VERSION "dbc-export 1 2025.20.8"

NS_ :

BS_:

BU_: APP BMS CC CMP CMPD CP DAS DI DIF DIR EPBL EPBR EVSE FC GTW HCML HCMR HVP ICR PCS PM PMF PMR PTC SCCM SDCR TAS UMC VC VCFRONT VCLEFT VCRIGHT VCSEC

BO_ 909 APP_VC_infoMessage: 8 APP
 SG_ APP_inTunnel : 0|2@1+ (1,0) [1|3] "" Vector__XXX
 SG_ APP_windshieldHeaterOnReason : 2|3@1+ (1,0) [1|7] "" Vector__XXX
 SG_ APP_selfieCameraBlocked : 6|2@1+ (1,0) [1|3] "" Vector__XXX
 SG_ APP_selfieCameraLUX : 8|8@1+ (1,0) [0|253] "lux" Vector__XXX
 SG_ APP_sceneTagClearlyRaining : 16|2@1+ (1,0) [1|3] "" Vector__XXX
 SG_ APP_sceneTagFog : 18|2@1+ (1,0) [1|3] "" Vector__XXX
 SG_ APP_sceneTagFullyBlocked : 20|2@1+ (1,0) [1|3] "" Vector__XXX
 SG_ APP_sceneTagIndoors : 22|2@1+ (1,0) [1|3] "" Vector__XXX
 SG_ APP_sceneTagLensFlare : 24|2@1+ (1,0) [1|3] "" Vector__XXX
 SG_ APP_sceneTagRaining : 26|2@1+ (1,0) [1|3] "" Vector__XXX
 SG_ APP_sceneTagSevereWeather : 28|2@1+ (1,0) [1|3] "" Vector__XXX
 SG_ APP_sceneTagSnowing : 30|2@1+ (1,0) [1|3] "" Vector__XXX
 SG_ APP_sceneTagSnowyRoad : 32|2@1+ (1,0) [1|3] "" Vector__XXX
 SG_ APP_sceneTagSunGlare : 34|2@1+ (1,0) [1|3] "" Vector__XXX
 SG_ APP_sceneTagTunnel : 36|2@1+ (1,0) [1|3] "" Vector__XXX
 SG_ APP_sceneTagWetRoad : 38|2@1+ (1,0) [1|3] "" Vector__XXX
 SG_ APP_fisheyeInPathVisibility : 40|3@1+ (1,0) [1|7] "" Vector__XXX
 SG_ APP_fisheyeOverallVisibility : 43|3@1+ (1,0) [1|7] "" Vector__XXX
 SG_ APP_mainInPathVisibility : 46|3@1+ (1,0) [1|7] "" Vector__XXX
 SG_ APP_mainOverallVisibility : 49|3@1+ (1,0) [1|7] "" Vector__XXX
 SG_ APP_narrowInPathVisibility : 52|3@1+ (1,0) [1|7] "" Vector__XXX
 SG_ APP_narrowOverallVisibility : 55|3@1+ (1,0) [1|7] "" Vector__XXX
 SG_ APP_frontCamOcclusionType : 58|3@1+ (1,0) [0|7] "" Vector__XXX

BO_ 818 BMS_bmbMinMax: 6 BMS
 SG_ BMS_bmbMinMaxMultiplexer M : 0|2@1+ (1,0) [0|3] "" Vector__XXX
 SG_ BMS_thermistorNumTMin m0 : 2|4@1+ (1,0) [0|15] "" Vector__XXX
 SG_ BMS_thermistorNumTMax m0 : 8|4@1+ (1,0) [0|15] "" Vector__XXX
 SG_ BMS_thermistorTMax m0 : 16|8@1+ (0.5,-40) [-40|87.5] "DegC" Vector__XXX
 SG_ BMS_thermistorTMin m0 : 24|8@1+ (0.5,-40) [-40|87.5] "DegC" Vector__XXX
 SG_ BMS_thermistorTAvg m0 : 32|8@1+ (0.5,-40) [-40|87.5] "DegC" Vector__XXX
 SG_ BMS_brickVoltageMax m1 : 2|12@1+ (0.002,0) [0|5] "V" Vector__XXX
 SG_ BMS_brickVoltageMin m1 : 16|12@1+ (0.002,0) [0|5] "V" Vector__XXX
 SG_ BMS_brickNumVoltageMax m1 : 32|7@1+ (1,1) [1|128] "" Vector__XXX
 SG_ BMS_brickNumVoltageMin m1 : 40|7@1+ (1,1) [1|128] "" Vector__XXX

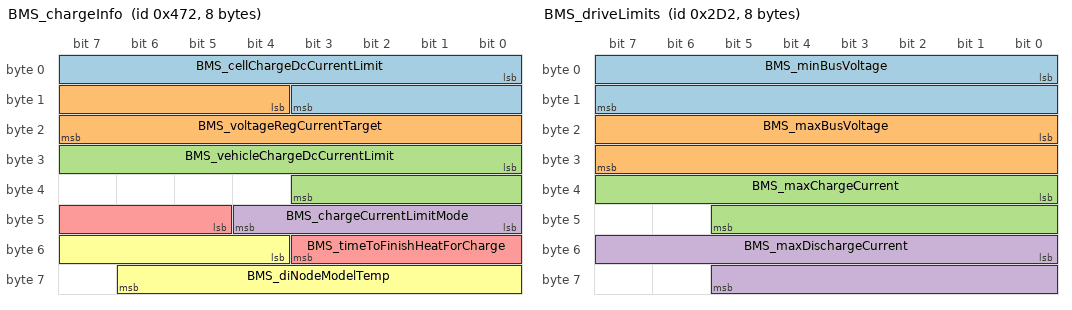
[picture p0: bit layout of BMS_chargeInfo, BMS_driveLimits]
BO_ 1138 BMS_chargeInfo: 8 BMS
 SG_ BMS_cellChargeDcCurrentLimit : 0|12@1+ (0.5,0) [0|2047.5] "A" Vector__XXX
 SG_ BMS_voltageRegCurrentTarget : 12|12@1+ (0.5,0) [0|2047.5] "A" Vector__XXX
 SG_ BMS_vehicleChargeDcCurrentLimit : 24|12@1+ (0.5,0) [0|2047.5] "A" Vector__XXX
 SG_ BMS_chargeCurrentLimitMode : 40|5@1+ (1,0) [0|31] "" Vector__XXX
 SG_ BMS_timeToFinishHeatForCharge : 45|7@1+ (5,0) [0|600] "min" Vector__XXX
 SG_ BMS_diNodeModelTemp : 52|11@1+ (0.1,-50) [-50|154.6] "degC" Vector__XXX

BO_ 722 BMS_driveLimits: 8 BMS
 SG_ BMS_minBusVoltage : 0|16@1+ (0.02,0) [0|1200] "V" Vector__XXX
 SG_ BMS_maxBusVoltage : 16|16@1+ (0.02,0) [0|1200] "V" Vector__XXX
 SG_ BMS_maxChargeCurrent : 32|14@1+ (0.1,0) [0|1638.2] "A" Vector__XXX
 SG_ BMS_maxDischargeCurrent : 48|14@1+ (0.15,0) [0|2455] "A" Vector__XXX

BO_ 850 BMS_energyStatus: 8 BMS
 SG_ BMS_energyStatusMultiplexer M : 0|2@1+ (1,0) [0|3] "" Vector__XXX
 SG_ BMS_nominalFullPackEnergy m0 : 16|16@1+ (0.02,0) [0|1310.68] "kWh" Vector__XXX
 SG_ BMS_nominalEnergyRemaining m0 : 32|16@1+ (0.02,0) [0|1310.68] "kWh" Vector__XXX
 SG_ BMS_idealEnergyRemaining m0 : 48|16@1+ (0.02,0) [0|1310.68] "kWh" Vector__XXX
 SG_ BMS_fullChargeComplete m1 : 15|1@1+ (1,0) [0|1] "" Vector__XXX
 SG_ BMS_energyBuffer m1 : 16|16@1+ (0.01,0) [0|655.34] "kWh" Vector__XXX
 SG_ BMS_expectedEnergyRemaining m1 : 32|16@1+ (0.02,0) [0|1310.68] "kWh" Vector__XXX
 SG_ BMS_energyToChargeComplete m1 : 48|16@1+ (0.02,0) [0|1310.68] "kWh" Vector__XXX
 SG_ BMS_energyRemainingDisplay m2 : 8|16@1+ (0.02,0) [0|1310.68] "kWh" Vector__XXX
 SG_ BMS_energyRemainingTDisplay m2 : 24|16@1+ (0.02,0) [0|1310.68] "kWh" Vector__XXX
 SG_ BMS_energyDisplayErrorBlendRate m2 : 40|12@1+ (0.0156288165599,0) [0|64] "%" Vector__XXX
 SG_ BMS_userFacingSoe m2 : 52|11@1+ (0.05,0) [0|100] "%" Vector__XXX

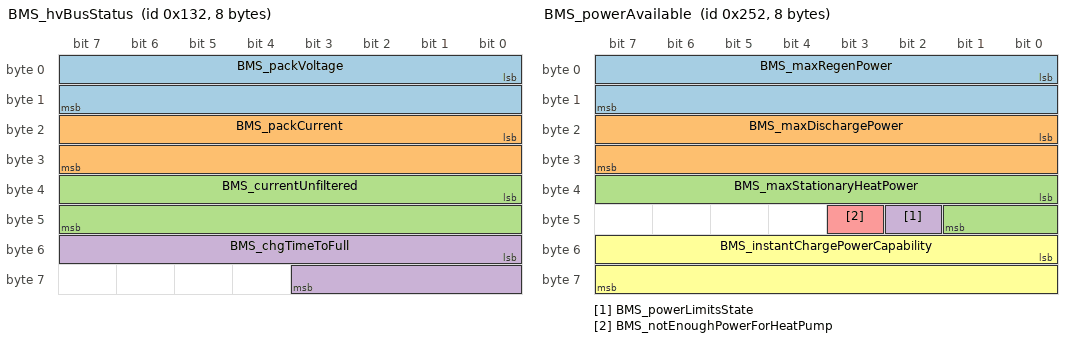
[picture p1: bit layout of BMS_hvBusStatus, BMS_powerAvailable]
BO_ 306 BMS_hvBusStatus: 8 BMS
 SG_ BMS_packVoltage : 0|16@1+ (0.01,0) [0|655.35] "V" Vector__XXX
 SG_ BMS_packCurrent : 16|16@1- (0.1,0) [-3276.7|3276.7] "A" Vector__XXX
 SG_ BMS_currentUnfiltered : 32|16@1- (0.05,-822) [-2460.3|816.3] "A" Vector__XXX
 SG_ BMS_chgTimeToFull : 48|12@1+ (0.01666667,0) [0|68.23334698] "Hours" Vector__XXX

BO_ 768 BMS_info: 8 BMS
 SG_ BMS_infoIndex M : 0|8@1+ (1,0) [0|255] "" Vector__XXX
 SG_ BMS_buildType m10 : 8|3@1+ (1,0) [0|7] "" Vector__XXX
 SG_ BMS_buildConfigId m10 : 16|16@1+ (1,0) [0|65535] "" Vector__XXX
 SG_ BMS_hardwareId m10 : 32|16@1+ (1,0) [0|65535] "" Vector__XXX
 SG_ BMS_componentId m10 : 48|16@1+ (1,0) [0|65535] "" Vector__XXX
 SG_ BMS_pcbaId m11 : 16|8@1+ (1,0) [0|255] "" Vector__XXX
 SG_ BMS_assemblyId m11 : 24|8@1+ (1,0) [0|255] "" Vector__XXX
 SG_ BMS_usageId m11 : 32|16@1+ (1,0) [0|65535] "" Vector__XXX
 SG_ BMS_subUsageId m11 : 48|16@1+ (1,0) [0|65535] "" Vector__XXX
 SG_ BMS_platformType m13 : 8|8@1+ (1,0) [0|255] "" Vector__XXX
 SG_ BMS_appCrc m13 : 32|32@1+ (1,0) [0|4294967295] "" Vector__XXX
 SG_ BMS_appGitHash m17 : 8|56@1+ (1,0) [0|7.20575940379e+16] "" Vector__XXX
 SG_ BMS_bootGitHash m18 : 8|56@1+ (1,0) [0|7.20575940379e+16] "" Vector__XXX
 SG_ BMS_bootUdsProtoVersion m20 : 8|8@1+ (1,0) [0|255] "" Vector__XXX
 SG_ BMS_bootCrc m20 : 32|32@1+ (1,0) [0|4294967295] "" Vector__XXX

BO_ 978 BMS_kwhCounter: 8 BMS
 SG_ BMS_kwhDischargeTotal : 0|32@1+ (0.001,0) [0|268435.456] "KWh" Vector__XXX
 SG_ BMS_kwhChargeTotal : 32|32@1+ (0.001,0) [0|268435.456] "KWh" Vector__XXX

BO_ 1010 BMS_kwhCountersMultiplexed: 8 BMS
 SG_ BMS_kwhCounter_Id M : 0|4@1+ (1,0) [0|15] "" Vector__XXX
 SG_ BMS_acChargerKwhTotal m0 : 8|32@1+ (0.001,0) [0|268435.456] "KWh" Vector__XXX
 SG_ BMS_dcChargerKwhTotal m1 : 8|32@1+ (0.001,0) [0|268435.456] "KWh" Vector__XXX
 SG_ BMS_kwhRegenChargeTotal m2 : 8|32@1+ (0.001,0) [0|268435.456] "KWh" Vector__XXX
 SG_ BMS_kwhDriveDischargeTotal m3 : 8|32@1+ (0.001,0) [0|268435.456] "KWh" Vector__XXX
 SG_ BMS_kwhDischargeTotalModule1 m4 : 8|28@1+ (0.001,0) [0|268435.455] "KWh" Vector__XXX
 SG_ BMS_kwhChargeTotalModule1 m4 : 36|28@1+ (0.001,0) [0|268435.455] "KWh" Vector__XXX
 SG_ BMS_kwhAcChargeTotalModule1 m5 : 8|28@1+ (0.001,0) [0|268435.455] "KWh" Vector__XXX
 SG_ BMS_kwhDcChargeTotalModule1 m5 : 36|28@1+ (0.001,0) [0|268435.455] "KWh" Vector__XXX
 SG_ BMS_kwhDischargeTotalModule2 m6 : 8|28@1+ (0.001,0) [0|268435.455] "KWh" Vector__XXX
 SG_ BMS_kwhChargeTotalModule2 m6 : 36|28@1+ (0.001,0) [0|268435.455] "KWh" Vector__XXX
 SG_ BMS_kwhAcChargeTotalModule2 m7 : 8|28@1+ (0.001,0) [0|268435.455] "KWh" Vector__XXX
 SG_ BMS_kwhDcChargeTotalModule2 m7 : 36|28@1+ (0.001,0) [0|268435.455] "KWh" Vector__XXX
 SG_ BMS_kwhDischargeTotalModule3 m8 : 8|28@1+ (0.001,0) [0|268435.455] "KWh" Vector__XXX
 SG_ BMS_kwhChargeTotalModule3 m8 : 36|28@1+ (0.001,0) [0|268435.455] "KWh" Vector__XXX
 SG_ BMS_kwhAcChargeTotalModule3 m9 : 8|28@1+ (0.001,0) [0|268435.455] "KWh" Vector__XXX
 SG_ BMS_kwhDcChargeTotalModule3 m9 : 36|28@1+ (0.001,0) [0|268435.455] "KWh" Vector__XXX
 SG_ BMS_kwhDischargeTotalModule4 m10 : 8|28@1+ (0.001,0) [0|268435.455] "KWh" Vector__XXX
 SG_ BMS_kwhChargeTotalModule4 m10 : 36|28@1+ (0.001,0) [0|268435.455] "KWh" Vector__XXX
 SG_ BMS_kwhAcChargeTotalModule4 m11 : 8|28@1+ (0.001,0) [0|268435.455] "KWh" Vector__XXX
 SG_ BMS_kwhDcChargeTotalModule4 m11 : 36|28@1+ (0.001,0) [0|268435.455] "KWh" Vector__XXX

BO_ 882 BMS_log1: 8 BMS
 SG_ BMS_log1MuxId M : 0|8@1+ (1,0) [0|255] "" Vector__XXX
 SG_ BMS_extDcPrechargeVoltageLimit m8 : 20|12@1+ (0.146502256393,0) [0|599.926739929] "V" Vector__XXX
 SG_ BMS_dcChargeCurrentRequest m8 : 32|14@1- (0.25,0) [-2048|2047.75] "A" Vector__XXX
 SG_ BMS_dcChargeCurrentLimit m8 : 46|13@1- (0.5,0) [-2048|2047.5] "A" Vector__XXX
 SG_ BMS_dcDischargeEnabled m8 : 59|1@1+ (1,0) [0|1] "" Vector__XXX
 SG_ BMS_rippleChargeRetryCount m8 : 60|3@1+ (1,0) [0|7] "" Vector__XXX
 SG_ BMS_dcChargeVoltageLimit m9 : 8|12@1+ (0.146502256393,0) [0|599.926739929] "V" Vector__XXX
 SG_ BMS_dcChargePowerLimit m9 : 20|12@1- (1,0) [-2048|2047] "kW" Vector__XXX
 SG_ BMS_maxExtIsoFcLinkV m9 : 48|13@1+ (0.134293735027,0) [0|1099.99998361] "V" Vector__XXX
 SG_ BMS_socByDeltaVEnabled m15 : 8|1@1+ (1,0) [0|1] "" Vector__XXX
 SG_ BMS_socByDvMaxSocLimit m15 : 9|10@1+ (0.1,0) [0|102.2] "%" Vector__XXX
 SG_ BMS_socByDvVoltageChangeOverAh m15 : 19|9@1+ (0.002,0) [0|1] "V" Vector__XXX
 SG_ BMS_socByDvMaxSocByAhCorrected m15 : 28|10@1+ (0.1,0) [0|102.2] "%" Vector__XXX
 SG_ BMS_socByDvMaxBrickVoltage m15 : 40|12@1+ (0.002,0) [0|5] "V" Vector__XXX
 SG_ BMS_socByDvMaxBrickId m15 : 56|8@1+ (1,1) [1|256] "" Vector__XXX

BO_ 946 BMS_log2: 8 BMS
 SG_ BMS_log2MuxId M : 0|7@1+ (1,0) [0|127] "" Vector__XXX
 SG_ BMS_cacAvg m0 : 8|13@1+ (0.1,0) [0|819.1] "Ah" Vector__XXX
 SG_ BMS_cacMin m0 : 24|13@1+ (0.1,0) [0|819.1] "Ah" Vector__XXX
 SG_ BMS_cacMinBrickId m0 : 37|7@1+ (1,1) [1|128] "" Vector__XXX
 SG_ BMS_cacMax m0 : 44|13@1+ (0.1,0) [0|819.1] "Ah" Vector__XXX
 SG_ BMS_cacMaxBrickId m0 : 57|7@1+ (1,1) [1|128] "" Vector__XXX
 SG_ BMS_acRippleConfigNvramValid m18 : 7|1@1+ (1,0) [0|1] "" Vector__XXX
 SG_ BMS_hvChain_useLeakyBucket m18 : 8|1@1+ (1,0) [0|1] "" Vector__XXX
 SG_ BMS_hvChain_iLimit m18 : 9|14@1+ (0.2,0) [0|3275] "A" Vector__XXX
 SG_ BMS_hvChain_limitingState m18 : 23|9@1+ (1,1) [1|511] "" Vector__XXX
 SG_ BMS_hvChain_limitingStateTempera m18 : 32|13@1- (0.1,367.6) [-40|775] "DegC" Vector__XXX
 SG_ BMS_acRippleIsSupported m18 : 45|1@1+ (1,0) [0|1] "" Vector__XXX
 SG_ BMS_acRippleStartTemperatureMax m18 : 46|9@1+ (0.25,-25) [-25|100] "DegC" Vector__XXX
 SG_ BMS_acRippleStartTemperatureMin m18 : 55|9@1+ (0.25,-25) [-25|100] "DegC" Vector__XXX
 SG_ BMS_fcLinkTestDecayTime m20 : 8|10@1+ (2,0) [0|2044] "mS" Vector__XXX
 SG_ BMS_fcLinkTestTimeSinceLastRun m20 : 18|12@1+ (0.0175824183971,0) [0|71.99] "Hours" Vector__XXX
 SG_ BMS_pcsPrechargeTargetVoltage m20 : 32|16@1- (0.1,0) [-3276.8|3276.7] "V" Vector__XXX
 SG_ BMS_recentOvUvAlert m20 : 48|1@1+ (1,0) [0|1] "" Vector__XXX
 SG_ BMS_recentIsoAlert m20 : 49|1@1+ (1,0) [0|1] "" Vector__XXX
 SG_ BMS_recentBmbMiaAlert m20 : 50|1@1+ (1,0) [0|1] "" Vector__XXX
 SG_ BMS_cacBlendingConfigNvramValid m20 : 51|1@1+ (1,0) [0|1] "" Vector__XXX
 SG_ BMS_cacBlendingEnabled m20 : 52|1@1+ (1,0) [0|1] "" Vector__XXX
 SG_ BMS_cacBlendPercentPerCycle m20 : 53|10@1+ (0.001,0) [0|1.023] "%" Vector__XXX
 SG_ BMS_energyVariableChgRequested m21 : 8|1@1+ (1,0) [0|1] "" Vector__XXX
 SG_ BMS_packRestTime m21 : 9|12@1+ (0.0175824183971,0) [0|71.99] "Hours" Vector__XXX
 SG_ BMS_idealEnergyFloor m21 : 21|10@1+ (0.1,0) [0|102.2] "KWh" Vector__XXX
 SG_ BMS_thmGradientSlopeCondition m21 : 31|1@1+ (1,0) [0|1] "" Vector__XXX
 SG_ BMS_recentSlopeConditon m21 : 32|1@1+ (1,0) [0|1] "" Vector__XXX
 SG_ BMS_dynamicEnergyBuffer m21 : 33|10@1+ (0.1,0) [0|102.2] "KWh" Vector__XXX
 SG_ BMS_temperatureCondition m21 : 43|1@1+ (1,0) [0|1] "" Vector__XXX
 SG_ BMS_thmGradientSlope m21 : 44|10@1- (0.01,0) [-5.12|5.11] "C/min" Vector__XXX
 SG_ BMS_thmGradient m21 : 56|8@1+ (0.1,0) [0|25.5] "C" Vector__XXX
 SG_ BMS_dSocNormalizedMin m33 : 8|12@1+ (0.0030517578125,-12.4969482422) [-12.4969482422|-0.003051757825] "%" Vector__XXX
 SG_ BMS_dSocNormalizedFiltMin m33 : 20|12@1+ (0.0030517578125,-12.4969482422) [-12.4969482422|-0.003051757825] "%" Vector__XXX
 SG_ BMS_dSocMinAlpha m33 : 32|12@1+ (0.0030517578125,-12.4969482422) [-12.4969482422|-0.003051757825] "%" Vector__XXX
 SG_ BMS_dSocMaxLowAlphaCounter m33 : 44|4@1+ (1,0) [0|15] "" Vector__XXX
 SG_ BMS_dSocMinAlphaBrickID m33 : 48|7@1+ (1,1) [1|128] "" Vector__XXX
 SG_ BMS_dSocCacMargin m33 : 55|9@1+ (0.0030517578125,0) [0|1.55639648438] "%" Vector__XXX
 SG_ BMS_lifeModelAvgTempSeverity m55 : 8|5@1+ (0.1,0) [0|3] "-" Vector__XXX
 SG_ BMS_lifeModelDepthOfDischargeSev m55 : 16|8@1+ (0.01,0) [0|1.5] "-" Vector__XXX
 SG_ BMS_lifeModelHistogramCapacityLo m55 : 24|9@1+ (0.1,0) [0|51] "%" Vector__XXX
 SG_ BMS_lifeModelHistogramBrickCapac m55 : 33|13@1+ (0.1,0) [0|819] "Ah" Vector__XXX
 SG_ BMS_lifeModelDcrGrowthPercent m55 : 48|14@1- (0.1,200) [-100|500] "%" Vector__XXX
 SG_ BMS_nominalFullPackEnergyRaw m56 : 8|16@1+ (0.02,0) [0|1310.68] "kWh" Vector__XXX
 SG_ BMS_userChargeCalibratingReason m56 : 24|2@1+ (1,0) [0|3] "" Vector__XXX
 SG_ BMS_nominalEnergyRemainingBuffer m56 : 32|16@1+ (0.02,0) [0|1310.68] "kWh" Vector__XXX
 SG_ BMS_idealEnergyRemainingBuffered m56 : 48|16@1+ (0.02,0) [0|1310.68] "kWh" Vector__XXX
 SG_ BMS_largestCacSpreadErrorLower m64 : 8|12@1+ (0.1,0) [0|409.4] "Ah" Vector__XXX
 SG_ BMS_lifeModelAverageCac m64 : 20|12@1+ (0.1,0) [0|409.4] "Ah" Vector__XXX
 SG_ BMS_lifeModelCacBrick1 m64 : 32|12@1+ (0.1,0) [0|409.4] "Ah" Vector__XXX
 SG_ BMS_lifeModelAverageOffset m64 : 44|10@1- (0.1,0) [-51.1|51.1] "Ah" Vector__XXX
 SG_ BMS_percentCacUpdatesInTimeWindo m64 : 54|10@1+ (0.1,0) [0|100] "%" Vector__XXX
 SG_ BMS_lifeModelMaxCacBrickId m65 : 8|8@1+ (1,1) [1|255] "" Vector__XXX
 SG_ BMS_lifeModelMaxCac m65 : 16|12@1+ (0.1,0) [0|409.4] "Ah" Vector__XXX
 SG_ BMS_lifeModelMinCacBrickId m65 : 28|8@1+ (1,1) [1|255] "" Vector__XXX
 SG_ BMS_lifeModelMinCac m65 : 36|12@1+ (0.1,0) [0|409.4] "Ah" Vector__XXX
 SG_ BMS_restingPointCacAvg m65 : 48|12@1+ (0.1,0) [0|409.4] "Ah" Vector__XXX
 SG_ BMS_cacEstimationSource m65 : 60|2@1+ (1,0) [0|3] "" Vector__XXX
 SG_ BMS_synchronizedCacMaxRaw m71 : 8|12@1+ (0.1,0) [0|409.4] "Ah" Vector__XXX
 SG_ BMS_synchronizedCacMinRaw m71 : 20|12@1+ (0.1,0) [0|409.4] "Ah" Vector__XXX
 SG_ BMS_largestSyncCacErrorStartSoc m71 : 32|10@1+ (0.1,0) [0|102.2] "%" Vector__XXX
 SG_ BMS_largestSyncCacErrorEndSoc m71 : 42|10@1+ (0.1,0) [0|102.2] "%" Vector__XXX
 SG_ BMS_runtimeSocConfigNvramValid m71 : 52|1@1+ (1,0) [0|1] "" Vector__XXX
 SG_ BMS_runtimeSocCorrectionsEnabled m71 : 53|1@1+ (1,0) [0|1] "" Vector__XXX
 SG_ BMS_rubberBandingEnabled m71 : 54|1@1+ (1,0) [0|1] "" Vector__XXX
 SG_ BMS_rubberBandingConfigNvramVali m71 : 55|1@1+ (1,0) [0|1] "" Vector__XXX
 SG_ BMS_runtimeSocMinTempForModel m71 : 56|6@1+ (0.5,0) [0|20] "DegC" Vector__XXX
 SG_ BMS_energyBufferConfigNvramValid m71 : 62|1@1+ (1,0) [0|1] "" Vector__XXX
 SG_ BMS_thermalEvent1pDetectConfigDi m71 : 63|1@1+ (1,0) [0|1] "" Vector__XXX
 SG_ BMS_sohEnergy m79 : 8|11@1+ (0.1,0) [0|204.6] "KWh" Vector__XXX
 SG_ BMS_fullCapacitySohEnergy m79 : 19|11@1+ (0.1,0) [0|204.6] "KWh" Vector__XXX
 SG_ BMS_calibratedCapacitySohEnergy m79 : 30|11@1+ (0.1,0) [0|204.6] "KWh" Vector__XXX
 SG_ BMS_estimatedCapacitySohEnergy m79 : 41|11@1+ (0.1,0) [0|204.6] "KWh" Vector__XXX
 SG_ BMS_prevUserFacingSohEnergy m79 : 52|11@1+ (0.1,0) [0|204.6] "KWh" Vector__XXX
 SG_ BMS_stateOfHealthMinCac m80 : 8|13@1+ (0.1,0) [0|819] "Ah" Vector__XXX
 SG_ BMS_lifeModelStorageLossPackAge m80 : 24|14@1+ (1,0) [0|16382] "days" Vector__XXX
 SG_ BMS_lifeModelThroughputCycleCoun m80 : 40|12@1+ (1,0) [0|4094] "Cycles" Vector__XXX
 SG_ BMS_lifeModelThroughputDcrCycleC m80 : 52|12@1+ (1,0) [0|4094] "Cycles" Vector__XXX
 SG_ BMS_energyWalkCounter m83 : 8|8@1+ (1,0) [0|255] "" Vector__XXX
 SG_ BMS_energyWalkTimeoutCounter m83 : 16|8@1+ (1,0) [0|255] "" Vector__XXX
 SG_ BMS_dynamicCcvEnabled m83 : 24|1@1+ (1,0) [0|1] "" Vector__XXX
 SG_ BMS_chargeTargetLookupSoc m83 : 32|10@1+ (0.1,0) [0|102.2] "%" Vector__XXX
 SG_ BMS_stateOfHealth m83 : 42|10@1+ (0.1,0) [0|100] "%" Vector__XXX

BO_ 914 BMS_packConfig: 8 BMS
 SG_ BMS_packConfigMultiplexer M : 0|8@1+ (1,0) [0|255] "" Vector__XXX
 SG_ BMS_reservedConfig_0 m0 : 8|5@1+ (1,0) [0|31] "" Vector__XXX
 SG_ BMS_moduleType m1 : 8|3@1+ (1,0) [0|7] "" Vector__XXX
 SG_ BMS_thermalPackType m1 : 11|4@1+ (1,0) [0|15] "" Vector__XXX
 SG_ BMS_packMass m1 : 16|8@1+ (1,300) [342|540] "kg" Vector__XXX
 SG_ BMS_platformMaxBusVoltage m1 : 24|10@1+ (1,300) [300|1300] "V" Vector__XXX
 SG_ BMS_standbySupplyContinuousPower m1 : 36|2@1+ (1,0) [0|3] "" Vector__XXX

BO_ 594 BMS_powerAvailable: 8 BMS
 SG_ BMS_maxRegenPower : 0|16@1+ (0.01,0) [0|655.35] "kW" Vector__XXX
 SG_ BMS_maxDischargePower : 16|16@1+ (0.013,0) [0|850] "kW" Vector__XXX
 SG_ BMS_maxStationaryHeatPower : 32|10@1+ (0.01,0) [0|10.23] "kW" Vector__XXX
 SG_ BMS_powerLimitsState : 42|1@1+ (1,0) [0|1] "" Vector__XXX
 SG_ BMS_notEnoughPowerForHeatPump : 43|1@1+ (1,0) [0|1] "" Vector__XXX
 SG_ BMS_instantChargePowerCapability : 48|16@1+ (0.05,0) [0|3276.7] "kW" Vector__XXX

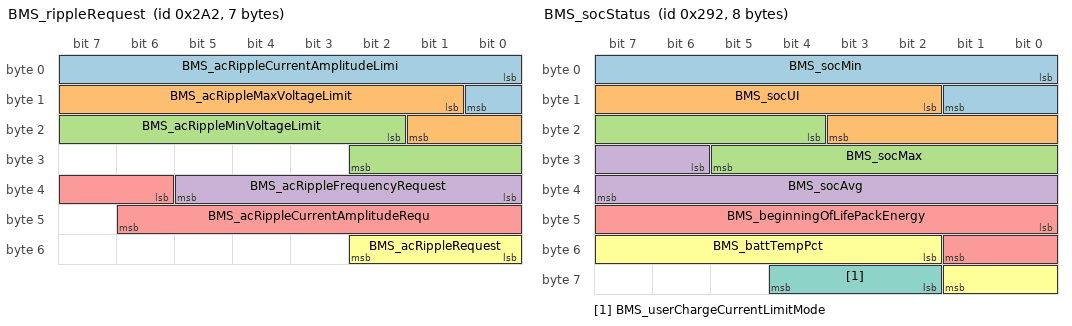
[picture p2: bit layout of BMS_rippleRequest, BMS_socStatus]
BO_ 674 BMS_rippleRequest: 7 BMS
 SG_ BMS_acRippleCurrentAmplitudeLimi : 0|9@1+ (1,0) [0|511] "A" Vector__XXX
 SG_ BMS_acRippleMaxVoltageLimit : 9|9@1+ (1,0) [0|511] "V" Vector__XXX
 SG_ BMS_acRippleMinVoltageLimit : 18|9@1+ (1,0) [0|511] "V" Vector__XXX
 SG_ BMS_acRippleFrequencyRequest : 32|6@1+ (1,80) [80|142] "Hz" Vector__XXX
 SG_ BMS_acRippleCurrentAmplitudeRequ : 38|9@1+ (1,0) [0|511] "A" Vector__XXX
 SG_ BMS_acRippleRequest : 48|3@1+ (1,0) [0|7] "" Vector__XXX

BO_ 658 BMS_socStatus: 8 BMS
 SG_ BMS_socMin : 0|10@1+ (0.1,0) [0|102.2] "%" Vector__XXX
 SG_ BMS_socUI : 10|10@1+ (0.1,0) [0|100] "%" Vector__XXX
 SG_ BMS_socMax : 20|10@1+ (0.1,0) [0|102.2] "%" Vector__XXX
 SG_ BMS_socAvg : 30|10@1+ (0.1,0) [0|102.2] "%" Vector__XXX
 SG_ BMS_beginningOfLifePackEnergy : 40|10@1+ (0.1,0) [0|102.2] "KWh" Vector__XXX
 SG_ BMS_battTempPct : 50|8@1+ (0.4,0) [0|100] "%" Vector__XXX
 SG_ BMS_userChargeCurrentLimitMode : 58|3@1+ (1,0) [0|7] "" Vector__XXX

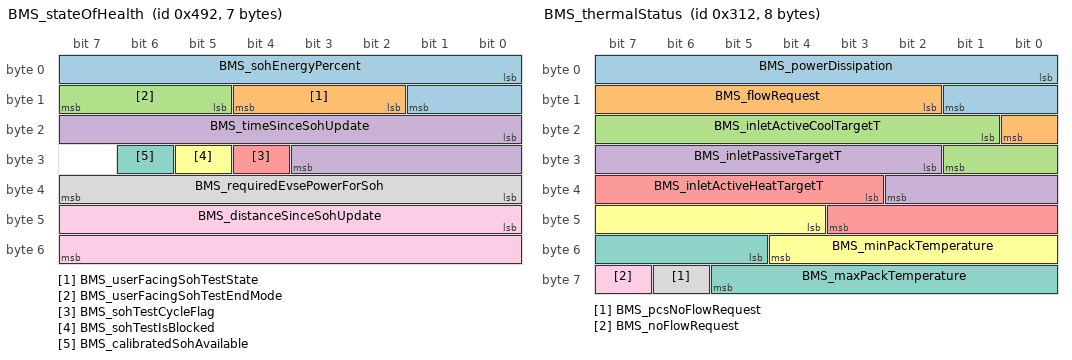
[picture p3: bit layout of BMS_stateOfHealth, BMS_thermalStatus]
BO_ 1170 BMS_stateOfHealth: 7 BMS
 SG_ BMS_sohEnergyPercent : 0|10@1+ (0.1,0) [0|100] "%" Vector__XXX
 SG_ BMS_userFacingSohTestState : 10|3@1+ (1,0) [0|7] "" Vector__XXX
 SG_ BMS_userFacingSohTestEndMode : 13|3@1+ (1,0) [0|7] "" Vector__XXX
 SG_ BMS_timeSinceSohUpdate : 16|12@1+ (1,0) [0|3650] "days" Vector__XXX
 SG_ BMS_sohTestCycleFlag : 28|1@1+ (1,0) [0|1] "" Vector__XXX
 SG_ BMS_sohTestIsBlocked : 29|1@1+ (1,0) [0|1] "" Vector__XXX
 SG_ BMS_calibratedSohAvailable : 30|1@1+ (1,0) [0|1] "" Vector__XXX
 SG_ BMS_requiredEvsePowerForSoh : 32|8@1+ (0.125,0) [0|31.75] "kW" Vector__XXX
 SG_ BMS_distanceSinceSohUpdate : 40|16@1+ (1,0) [0|65534] "km" Vector__XXX

BO_ 530 BMS_status: 8 BMS
 SG_ BMS_hvacPowerRequest : 0|1@1+ (1,0) [0|1] "" Vector__XXX
 SG_ BMS_notEnoughPowerForDrive : 1|1@1+ (1,0) [0|1] "" Vector__XXX
 SG_ BMS_notEnoughPowerForSupport : 2|1@1+ (1,0) [0|1] "" Vector__XXX
 SG_ BMS_preconditionAllowed : 3|1@1+ (1,0) [0|1] "" Vector__XXX
 SG_ BMS_updateAllowed : 4|1@1+ (1,0) [0|1] "" Vector__XXX
 SG_ BMS_activeHeatingWorthwhile : 5|1@1+ (1,0) [0|1] "" Vector__XXX
 SG_ BMS_cpMiaOnHvs : 6|1@1+ (1,0) [0|1] "" Vector__XXX
 SG_ BMS_pcsPwmEnabled : 7|1@1+ (1,0) [0|1] "" Vector__XXX
 SG_ BMS_contactorState : 8|3@1+ (1,0) [1|7] "" Vector__XXX
 SG_ BMS_userChargeStatus : 11|3@1+ (1,0) [0|7] "" Vector__XXX
 SG_ BMS_chargeRequest : 31|1@1+ (1,0) [0|1] "" Vector__XXX
 SG_ BMS_state : 32|4@1+ (1,0) [0|15] "" Vector__XXX
 SG_ BMS_diLimpRequest : 37|1@1+ (1,0) [0|1] "" Vector__XXX
 SG_ BMS_okToShipByAir : 38|1@1+ (1,0) [0|1] "" Vector__XXX
 SG_ BMS_okToShipByLand : 39|1@1+ (1,0) [0|1] "" Vector__XXX
 SG_ BMS_chgPowerAvailable : 40|12@1+ (0.125,0) [0|511.75] "kW" Vector__XXX
 SG_ BMS_chargeRetryCount : 53|3@1+ (1,0) [0|7] "" Vector__XXX
 SG_ BMS_conditioningRequest : 56|1@1+ (1,0) [0|1] "" Vector__XXX
 SG_ BMS_smStateRequest : 57|4@1+ (1,0) [0|15] "" Vector__XXX
 SG_ BMS_hvState : 61|3@1+ (1,0) [0|7] "" Vector__XXX

BO_ 786 BMS_thermalStatus: 8 BMS
 SG_ BMS_powerDissipation : 0|10@1+ (0.02,0) [0|20] "kW" Vector__XXX
 SG_ BMS_flowRequest : 10|7@1+ (0.3,0) [0|38.1] "LPM" Vector__XXX
 SG_ BMS_inletActiveCoolTargetT : 17|9@1+ (0.25,-25) [-25|100] "DegC" Vector__XXX
 SG_ BMS_inletPassiveTargetT : 26|9@1+ (0.25,-25) [-25|100] "DegC" Vector__XXX
 SG_ BMS_inletActiveHeatTargetT : 35|9@1+ (0.25,-25) [-25|100] "DegC" Vector__XXX
 SG_ BMS_minPackTemperature : 44|9@1+ (0.25,-25) [-25|102.75] "DegC" Vector__XXX
 SG_ BMS_maxPackTemperature : 53|9@1+ (0.25,-25) [-25|102.75] "DegC" Vector__XXX
 SG_ BMS_pcsNoFlowRequest : 62|1@1+ (1,0) [0|1] "" Vector__XXX
 SG_ BMS_noFlowRequest : 63|1@1+ (1,0) [0|1] "" Vector__XXX

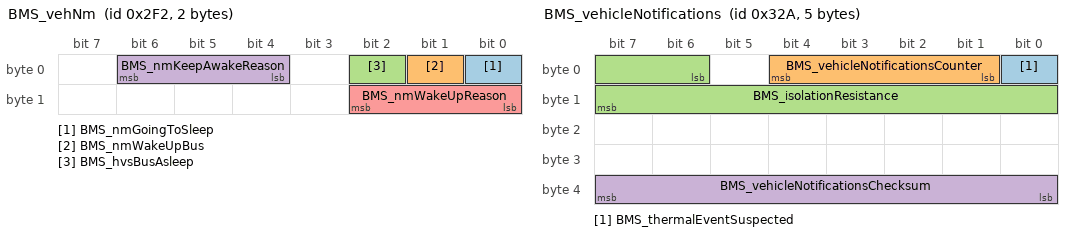
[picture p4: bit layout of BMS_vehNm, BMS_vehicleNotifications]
BO_ 754 BMS_vehNm: 2 BMS
 SG_ BMS_nmGoingToSleep : 0|1@1+ (1,0) [0|1] "" Vector__XXX
 SG_ BMS_nmWakeUpBus : 1|1@1+ (1,0) [0|1] "" Vector__XXX
 SG_ BMS_hvsBusAsleep : 2|1@1+ (1,0) [0|1] "" Vector__XXX
 SG_ BMS_nmKeepAwakeReason : 4|3@1+ (1,0) [1|7] "" Vector__XXX
 SG_ BMS_nmWakeUpReason : 8|3@1+ (1,0) [0|7] "" Vector__XXX

BO_ 810 BMS_vehicleNotifications: 5 BMS
 SG_ BMS_thermalEventSuspected : 0|1@1+ (1,0) [0|1] "" Vector__XXX
 SG_ BMS_vehicleNotificationsCounter : 1|4@1+ (1,0) [0|15] "" Vector__XXX
 SG_ BMS_isolationResistance : 6|10@1+ (10,0) [0|10000] "kOhm" Vector__XXX
 SG_ BMS_vehicleNotificationsChecksum : 32|8@1+ (1,0) [0|255] "" Vector__XXX

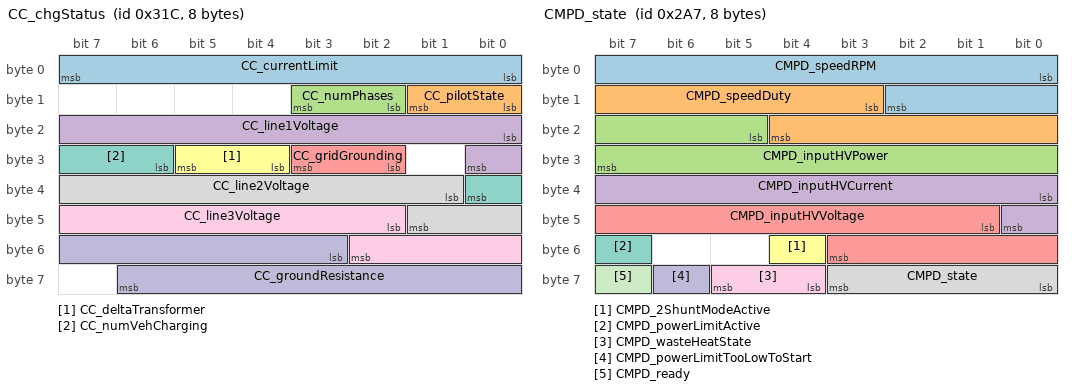
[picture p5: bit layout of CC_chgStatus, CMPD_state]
BO_ 796 CC_chgStatus: 8 CC
 SG_ CC_currentLimit : 0|8@1+ (0.5,0) [0|127] "A" Vector__XXX
 SG_ CC_pilotState : 8|2@1+ (1,0) [0|2] "" Vector__XXX
 SG_ CC_numPhases : 10|2@1+ (1,0) [1|3] "" Vector__XXX
 SG_ CC_line1Voltage : 16|9@1+ (1,0) [0|510] "V" Vector__XXX
 SG_ CC_gridGrounding : 26|2@1+ (1,0) [0|3] "" Vector__XXX
 SG_ CC_deltaTransformer : 28|2@1+ (1,0) [0|3] "" Vector__XXX
 SG_ CC_numVehCharging : 30|3@1+ (1,0) [0|7] "" Vector__XXX
 SG_ CC_line2Voltage : 33|9@1+ (1,0) [0|510] "V" Vector__XXX
 SG_ CC_line3Voltage : 42|9@1+ (1,0) [0|510] "V" Vector__XXX
 SG_ CC_groundResistance : 51|12@1+ (1,0) [0|4094] "kOhm" Vector__XXX

BO_ 797 CC_chgStatus2: 8 CC
 SG_ CC_chgStatus2Index M : 0|8@1+ (1,0) [0|255] "" Vector__XXX
 SG_ CC_buttonState m0 : 8|1@1+ (1,0) [0|1] "" Vector__XXX

BO_ 812 CC_logData: 8 CC
 SG_ CC_logIndex M : 0|8@1+ (1,0) [0|255] "" Vector__XXX
 SG_ CC_activeConnectorID m0 : 8|8@1+ (1,0) [0|255] "" Vector__XXX
 SG_ CC_temperature1 m0 : 16|8@1- (1,88) [-40|215] "DegC" Vector__XXX
 SG_ CC_temperature2 m0 : 24|8@1- (1,88) [-40|215] "DegC" Vector__XXX
 SG_ CC_temperature3 m0 : 32|8@1- (1,88) [-40|215] "DegC" Vector__XXX
 SG_ CC_contactor1Closed m0 : 40|2@1+ (1,0) [0|3] "" Vector__XXX
 SG_ CC_contactor2Closed m0 : 42|2@1+ (1,0) [0|3] "" Vector__XXX
 SG_ CC_temperature4 m0 : 44|8@1- (1,88) [-40|215] "DegC" Vector__XXX
 SG_ CC_conn1Current m1 : 8|8@1+ (0.5,0) [0|127] "A" Vector__XXX
 SG_ CC_conn2Current m2 : 8|8@1+ (0.5,0) [0|127] "A" Vector__XXX
 SG_ CC_conn3Current m3 : 8|8@1+ (0.5,0) [0|127] "A" Vector__XXX
 SG_ CC_conn4Current m4 : 8|8@1+ (0.5,0) [0|127] "A" Vector__XXX
 SG_ CC_lifetimei2t m10 : 32|32@1+ (0.1,0) [0|429496729.5] "A2h" Vector__XXX
 SG_ CC_lifetimeCtrCycles m11 : 8|28@1+ (1,0) [0|268435455] "" Vector__XXX
 SG_ CC_lifetimeCtrCyclesLoaded m11 : 36|28@1+ (1,0) [0|268435455] "" Vector__XXX
 SG_ CC_lifetimeAlertCount m12 : 8|28@1+ (1,0) [0|268435455] "" Vector__XXX
 SG_ CC_lifetimeThermalFoldbacks m12 : 36|28@1+ (1,0) [0|268435455] "" Vector__XXX
 SG_ CC_lifetimeAvgStartupTemp m13 : 36|28@1- (0.1,0) [-13421772.8|13421772.7] "degC" Vector__XXX

BO_ 870 CMPD_info: 8 CMPD
 SG_ CMPD_infoIndex M : 0|8@1+ (1,0) [0|255] "" Vector__XXX
 SG_ CMPD_infoBuildType m10 : 8|8@1+ (1,0) [0|255] "" Vector__XXX
 SG_ CMPD_infoBuildConfigId m10 : 16|16@1+ (1,0) [0|65535] "" Vector__XXX
 SG_ CMPD_infoHardwareId m10 : 32|16@1+ (1,0) [0|65535] "" Vector__XXX
 SG_ CMPD_infoComponentId m10 : 48|16@1+ (1,0) [0|65535] "" Vector__XXX
 SG_ CMPD_infoPcbaId m11 : 16|8@1+ (1,0) [0|255] "" Vector__XXX
 SG_ CMPD_infoAssemblyId m11 : 24|8@1+ (1,0) [0|254] "" Vector__XXX
 SG_ CMPD_infoUsageId m11 : 32|16@1+ (1,0) [0|65535] "" Vector__XXX
 SG_ CMPD_infoSubUsageId m11 : 48|16@1+ (1,0) [0|65535] "" Vector__XXX

BO_ 679 CMPD_state: 8 CMPD
 SG_ CMPD_speedRPM : 0|11@1+ (10,0) [0|20000] "RPM" Vector__XXX
 SG_ CMPD_speedDuty : 11|10@1+ (0.1,0) [0|100] "%" Vector__XXX
 SG_ CMPD_inputHVPower : 21|11@1+ (10,0) [0|20000] "W" Vector__XXX
 SG_ CMPD_inputHVCurrent : 32|9@1+ (0.1,0) [0|50] "A" Vector__XXX
 SG_ CMPD_inputHVVoltage : 41|11@1+ (0.5,0) [0|1000] "V" Vector__XXX
 SG_ CMPD_2ShuntModeActive : 52|1@1+ (1,0) [0|1] "" Vector__XXX
 SG_ CMPD_powerLimitActive : 55|1@1+ (1,0) [0|1] "" Vector__XXX
 SG_ CMPD_state : 56|4@1+ (1,0) [0|14] "" Vector__XXX
 SG_ CMPD_wasteHeatState : 60|2@1+ (1,0) [0|3] "" Vector__XXX
 SG_ CMPD_powerLimitTooLowToStart : 62|1@1+ (1,0) [0|1] "" Vector__XXX
 SG_ CMPD_ready : 63|1@1+ (1,0) [0|1] "" Vector__XXX

BO_ 867 CMP_info: 8 CMP
 SG_ CMP_infoIndex M : 0|8@1+ (1,0) [0|255] "" Vector__XXX
 SG_ CMP_infoBuildType m10 : 8|8@1+ (1,0) [0|255] "" Vector__XXX
 SG_ CMP_infoBuildConfigId m10 : 16|16@1+ (1,0) [0|65535] "" Vector__XXX
 SG_ CMP_infoHardwareId m10 : 32|16@1+ (1,0) [0|65535] "" Vector__XXX
 SG_ CMP_infoComponentId m10 : 48|16@1+ (1,0) [0|65535] "" Vector__XXX
 SG_ CMP_infoPcbaId m11 : 16|8@1+ (1,0) [0|255] "" Vector__XXX
 SG_ CMP_infoAssemblyId m11 : 24|8@1+ (1,0) [0|254] "" Vector__XXX
 SG_ CMP_infoUsageId m11 : 32|16@1+ (1,0) [0|65535] "" Vector__XXX
 SG_ CMP_infoSubUsageId m11 : 48|16@1+ (1,0) [0|65535] "" Vector__XXX
 SG_ CMP_infoPlatformType m13 : 8|8@1+ (1,0) [0|255] "" Vector__XXX
 SG_ CMP_infoAppCrc m13 : 32|32@1+ (1,0) [0|4294967295] "" Vector__XXX
 SG_ CMP_infoBootUdsProtoVersion m20 : 8|8@1+ (1,0) [0|255] "" Vector__XXX
 SG_ CMP_infoBootCrc m20 : 32|32@1+ (1,0) [0|4294967295] "" Vector__XXX

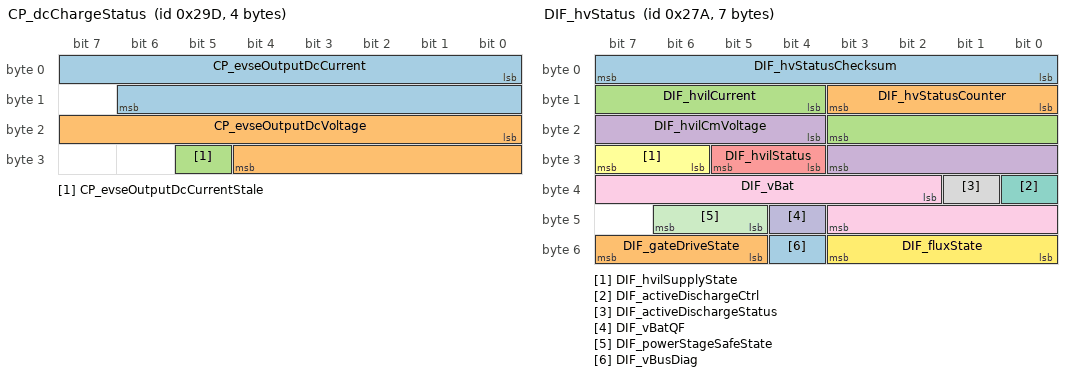
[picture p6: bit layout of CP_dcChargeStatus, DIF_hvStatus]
BO_ 669 CP_dcChargeStatus: 4 CP
 SG_ CP_evseOutputDcCurrent : 0|15@1- (0.125,0) [-2048|2047.875] "A" Vector__XXX
 SG_ CP_evseOutputDcVoltage : 16|13@1+ (0.07324219,0) [0|599.92675822] "V" Vector__XXX
 SG_ CP_evseOutputDcCurrentStale : 29|1@1+ (1,0) [0|1] "" Vector__XXX

BO_ 541 CP_evseStatus: 8 CP
 SG_ CP_evseAccept : 0|1@1+ (1,0) [0|1] "" Vector__XXX
 SG_ CP_evseRequest : 1|1@1+ (1,0) [0|1] "" Vector__XXX
 SG_ CP_proximity : 2|2@1+ (1,0) [1|3] "" Vector__XXX
 SG_ CP_pilot : 4|3@1+ (1,0) [0|6] "" Vector__XXX
 SG_ CP_digitalCommsEstablished : 7|1@1+ (1,0) [0|1] "" Vector__XXX
 SG_ CP_pilotCurrent : 8|8@1+ (0.5,0) [0|127.5] "A" Vector__XXX
 SG_ CP_cableType : 16|3@1+ (1,0) [0|7] "" Vector__XXX
 SG_ CP_iecPilotState : 19|4@1+ (1,0) [0|15] "" Vector__XXX
 SG_ CP_plcSupported : 23|1@1+ (1,0) [0|1] "" Vector__XXX
 SG_ CP_cableCurrentLimit : 24|7@1+ (1,0) [0|127] "A" Vector__XXX
 SG_ CP_teslaSwcanState : 34|4@1+ (1,0) [0|15] "" Vector__XXX
 SG_ CP_evseChargeType_UI : 38|2@1+ (1,0) [0|3] "" Vector__XXX
 SG_ CP_gbState : 40|4@1+ (1,0) [0|15] "" Vector__XXX
 SG_ CP_gbdcStopChargeReason : 44|4@1+ (1,0) [0|15] "" Vector__XXX
 SG_ CP_gbdcFailureReason : 48|2@1+ (1,0) [0|3] "" Vector__XXX
 SG_ CP_gbdcChargeAttempts : 50|2@1+ (1,0) [0|3] "" Vector__XXX
 SG_ CP_acChargeState : 52|3@1+ (1,0) [0|7] "" Vector__XXX
 SG_ CP_teslaDcState : 56|4@1+ (1,0) [0|15] "" Vector__XXX

BO_ 1342 CP_info: 8 CP
 SG_ CP_infoIndex M : 0|8@1+ (1,0) [0|255] "" Vector__XXX
 SG_ CP_buildType m10 : 8|3@1+ (1,0) [0|7] "" Vector__XXX
 SG_ CP_buildConfigId m10 : 16|16@1+ (1,0) [0|65535] "" Vector__XXX
 SG_ CP_hardwareId m10 : 32|16@1+ (1,0) [0|65535] "" Vector__XXX
 SG_ CP_componentId m10 : 48|16@1+ (1,0) [0|65535] "" Vector__XXX
 SG_ CP_pcbaId m11 : 16|8@1+ (1,0) [0|255] "" Vector__XXX
 SG_ CP_assemblyId m11 : 24|8@1+ (1,0) [0|255] "" Vector__XXX
 SG_ CP_usageId m11 : 32|16@1+ (1,0) [0|65535] "" Vector__XXX
 SG_ CP_subUsageId m11 : 48|16@1+ (1,0) [0|65535] "" Vector__XXX
 SG_ CP_platformType m13 : 8|8@1+ (1,0) [0|255] "" Vector__XXX
 SG_ CP_appCrc m13 : 32|32@1+ (1,0) [0|4294967295] "" Vector__XXX
 SG_ CP_appGitHash m17 : 8|56@1+ (1,0) [0|7.20575940379e+16] "" Vector__XXX
 SG_ CP_bootGitHash m18 : 8|56@1+ (1,0) [0|7.20575940379e+16] "" Vector__XXX
 SG_ CP_bootUdsProtoVersion m20 : 8|8@1+ (1,0) [0|255] "" Vector__XXX
 SG_ CP_bootCrc m20 : 32|32@1+ (1,0) [0|4294967295] "" Vector__XXX

BO_ 1885 CP_loggingFast: 8 CP
 SG_ CP_loggingFastSelect M : 0|4@1+ (1,0) [0|15] "" Vector__XXX
 SG_ CP_inductiveSensor_raw m0 : 4|28@1+ (1,0) [0|268435455] "" Vector__XXX
 SG_ CP_doorOpenActuationTime m0 : 32|14@1+ (1,0) [0|16383] "ms" Vector__XXX
 SG_ CP_doorCloseActuationTime m0 : 46|14@1+ (1,0) [0|16383] "ms" Vector__XXX
 SG_ CP_chargeCableSecured m0 : 60|1@1+ (1,0) [0|1] "" Vector__XXX
 SG_ CP_chargeCablePresent m0 : 61|1@1+ (1,0) [0|1] "" Vector__XXX
 SG_ CP_latchCheckAvailable m0 : 62|1@1+ (1,0) [0|1] "" Vector__XXX
 SG_ CP_UHF_controlState m2 : 4|4@1+ (1,0) [0|15] "" Vector__XXX
 SG_ CP_proximityV m2 : 8|16@1+ (0.0001,0) [0|6.5535] "V" Vector__XXX
 SG_ CP_proximityV_GBCC1 m2 : 24|14@1+ (0.001,0) [0|13.3] "V" Vector__XXX
 SG_ CP_proximityV_GBCC2 m2 : 38|14@1+ (0.001,0) [0|13.3] "V" Vector__XXX
 SG_ CP_doorPot m2 : 52|12@1+ (0.025,0) [0|100] "%" Vector__XXX
 SG_ CP_doorOpenRequest m3 : 16|4@1+ (1,0) [0|15] "" Vector__XXX
 SG_ CP_doorOpenEndOfDriveReason m3 : 20|3@1+ (1,0) [0|7] "" Vector__XXX
 SG_ CP_coverClosed m3 : 23|1@1+ (1,0) [0|1] "" Vector__XXX
 SG_ CP_doorCloseEndOfDriveReason m3 : 24|3@1+ (1,0) [0|7] "" Vector__XXX
 SG_ CP_doorCloseRequest m3 : 27|5@1+ (1,0) [0|31] "" Vector__XXX
 SG_ CP_latchDisengagingTime m3 : 32|10@1+ (1,0) [0|1023] "ms" Vector__XXX
 SG_ CP_latchEngagingTime m3 : 42|10@1+ (1,0) [0|1023] "ms" Vector__XXX
 SG_ CP_latchDisengagingStopReason m3 : 52|3@1+ (1,0) [0|7] "" Vector__XXX
 SG_ CP_latchEngagingStopReason m3 : 56|3@1+ (1,0) [0|7] "" Vector__XXX
 SG_ CP_doorIdDetectionState m3 : 59|2@1+ (1,0) [1|3] "" Vector__XXX
 SG_ CP_doorIdDetectedBin m3 : 61|2@1+ (1,0) [0|3] "" Vector__XXX

BO_ 989 CP_loggingSlow: 8 CP
 SG_ CP_loggingSlowSelect M : 0|4@1+ (1,0) [0|15] "" Vector__XXX
 SG_ CP_UHF_chipState m3 : 4|3@1+ (1,0) [0|7] "" Vector__XXX
 SG_ CP_UHF_rssi m3 : 8|8@1+ (1,0) [0|255] "" Vector__XXX
 SG_ CP_UHF_rxOverflow m3 : 16|1@1+ (1,0) [0|1] "" Vector__XXX
 SG_ CP_UHF_rxNumBytes m3 : 17|8@1+ (1,0) [0|255] "" Vector__XXX
 SG_ CP_UHF_selfTestRssi m3 : 25|8@1+ (1,0) [0|255] "" Vector__XXX
 SG_ CP_latchI m3 : 33|12@1+ (0.0025,0) [0|10.2375] "A" Vector__XXX
 SG_ CP_inlet1HarnessIdState m3 : 45|2@1+ (1,0) [1|3] "" Vector__XXX
 SG_ CP_inlet1HarnessIdValue m3 : 47|3@1+ (1,0) [0|7] "" Vector__XXX
 SG_ CP_inlet2HarnessIdState m3 : 50|2@1+ (1,0) [1|3] "" Vector__XXX
 SG_ CP_inlet2HarnessIdValue m3 : 52|3@1+ (1,0) [0|7] "" Vector__XXX
 SG_ CP_inletHeaterState m3 : 55|2@1+ (1,0) [0|3] "" Vector__XXX
 SG_ CP_inletHeaterDuty m3 : 57|7@1+ (1,0) [0|100] "%" Vector__XXX
 SG_ CP_nvm_dataValid m5 : 4|1@1+ (1,0) [0|1] "" Vector__XXX
 SG_ CP_nvm_doorOpenCycles m5 : 8|16@1+ (1,0) [0|65535] "" Vector__XXX
 SG_ CP_nvm_doorCloseCycles m5 : 24|16@1+ (1,0) [0|65535] "" Vector__XXX
 SG_ CP_nvm_doorOpen m5 : 40|1@1+ (1,0) [0|1] "" Vector__XXX
 SG_ CP_nvm_doorPresent m5 : 41|1@1+ (1,0) [0|1] "" Vector__XXX
 SG_ CP_nvm_doorPresentValid m5 : 42|1@1+ (1,0) [0|1] "" Vector__XXX
 SG_ CP_nvm_badPilotDiodeDetected m5 : 43|1@1+ (1,0) [0|1] "" Vector__XXX
 SG_ CP_nvm_pilotDiodeFaultCount m5 : 44|3@1+ (1,0) [0|7] "" Vector__XXX
 SG_ CP_doorOpenLimiterMaxCount m5 : 47|4@1+ (1,0) [0|15] "counts" Vector__XXX
 SG_ CP_doorOpenLimiterMaxRequestType m5 : 51|4@1+ (1,0) [0|15] "" Vector__XXX
 SG_ CP_doorCloseLimiterMaxCount m5 : 55|4@1+ (1,0) [0|15] "counts" Vector__XXX
 SG_ CP_doorCloseLimiterMaxRequestTyp m5 : 59|5@1+ (1,0) [0|31] "" Vector__XXX

BO_ 605 CP_status: 8 CP
 SG_ CP_type : 0|2@1+ (1,0) [0|3] "" Vector__XXX
 SG_ CP_insertEnableLine : 2|1@1+ (1,0) [0|1] "" Vector__XXX
 SG_ CP_latchState : 3|2@1+ (1,0) [1|3] "" Vector__XXX
 SG_ CP_permanentPowerRequest : 5|1@1+ (1,0) [0|1] "" Vector__XXX
 SG_ CP_chargeDoorOpen : 6|1@1+ (1,0) [0|1] "" Vector__XXX
 SG_ CP_doorControlState : 8|3@1+ (1,0) [0|7] "" Vector__XXX
 SG_ CP_doorButtonPressed : 11|1@1+ (1,0) [0|1] "" Vector__XXX
 SG_ CP_swcanRelayClosed : 12|1@1+ (1,0) [0|1] "" Vector__XXX
 SG_ CP_inhibitOta : 13|1@1+ (1,0) [0|1] "" Vector__XXX
 SG_ CP_chargeCableState : 14|2@1+ (1,0) [1|3] "" Vector__XXX
 SG_ CP_latchControlState : 16|3@1+ (1,0) [0|7] "" Vector__XXX
 SG_ CP_ledColor : 19|4@1+ (1,0) [0|15] "" Vector__XXX
 SG_ CP_UHF_handleFound : 23|1@1+ (1,0) [0|1] "" Vector__XXX
 SG_ CP_faultLineSensed : 24|1@1+ (1,0) [0|1] "" Vector__XXX
 SG_ CP_doorPresenceState : 25|3@1+ (1,0) [0|7] "" Vector__XXX
 SG_ CP_inductiveSensorState : 28|3@1+ (1,0) [0|7] "" Vector__XXX
 SG_ CP_chargeDoorOpenUI : 31|1@1+ (1,0) [0|1] "" Vector__XXX
 SG_ CP_vehicleUnlockRequest : 32|1@1+ (1,0) [0|1] "" Vector__XXX
 SG_ CP_coldWeatherMode : 33|1@1+ (1,0) [0|1] "" Vector__XXX
 SG_ CP_latchEngaged : 35|1@1+ (1,0) [0|1] "" Vector__XXX
 SG_ CP_inletHeaterUiState : 40|3@1+ (1,0) [0|7] "" Vector__XXX

BO_ 893 CP_thermalStatus: 8 CP
 SG_ CP_thermalStatusSelect M : 0|1@1+ (1,0) [0|1] "" Vector__XXX
 SG_ CP_pinTemperature1 m1 : 8|8@1+ (0.8039216,-55) [-55|149.99] "C" Vector__XXX
 SG_ CP_pinTemperature2 m1 : 16|8@1+ (0.8039216,-55) [-55|149.99] "C" Vector__XXX
 SG_ CP_pinTemperature3 m1 : 24|8@1+ (0.8039216,-55) [-55|149.99] "C" Vector__XXX

BO_ 1001 DAS_bodyControls: 8 DAS
 SG_ DAS_headlightRequest : 0|2@1+ (1,0) [0|3] "" Vector__XXX
 SG_ DAS_hazardLightRequest : 2|2@1+ (1,0) [0|2] "" Vector__XXX
 SG_ DAS_wiperSpeed : 4|4@1+ (1,0) [0|15] "" Vector__XXX
 SG_ DAS_turnIndicatorRequest : 8|3@1+ (1,0) [0|7] "" Vector__XXX
 SG_ DAS_highLowBeamDecision : 11|2@1+ (1,0) [0|2] "" Vector__XXX
 SG_ DAS_heaterRequest : 13|2@1+ (1,0) [1|3] "" Vector__XXX
 SG_ DAS_highLowBeamOffReason : 15|3@1+ (1,0) [0|7] "" Vector__XXX
 SG_ DAS_forwardCamHeaterDutyCycle : 18|4@1+ (0.06666667,0) [0|1] "-" Vector__XXX
 SG_ DAS_dynamicBrakeLightRequest : 22|1@1+ (1,0) [0|1] "" Vector__XXX
 SG_ DAS_radarHeaterRequest : 23|1@1+ (1,0) [0|1] "" Vector__XXX
 SG_ DAS_ahlbOverride : 24|1@1+ (1,0) [0|1] "" Vector__XXX
 SG_ DAS_mirrorFoldRequest : 25|2@1+ (1,0) [0|2] "" Vector__XXX
 SG_ DAS_wiperWashRequest : 27|1@1+ (1,0) [0|1] "" Vector__XXX
 SG_ DAS_ulcConfirmationRequestActive : 28|1@1+ (1,0) [0|1] "" Vector__XXX
 SG_ DAS_overrideWiperSetting : 29|1@1+ (1,0) [0|1] "" Vector__XXX
 SG_ DAS_autoWiperState : 30|3@1+ (1,0) [0|7] "" Vector__XXX
 SG_ DAS_turnIndicatorRequestReason : 33|5@1+ (1,0) [0|31] "" Vector__XXX
 SG_ DAS_forwardRadarPowerRequest : 38|1@1+ (1,0) [0|1] "" Vector__XXX
 SG_ DAS_driverDomeLightRequest : 39|1@1+ (1,0) [0|1] "" Vector__XXX
 SG_ DAS_drivePowerStateRequest : 43|1@1+ (1,0) [0|1] "" Vector__XXX
 SG_ DAS_enableIcrDataCollection : 44|1@1+ (1,0) [0|1] "" Vector__XXX
 SG_ DAS_rPillarCamHeaterDutyCycle : 45|4@1+ (0.06666667,0) [0|1] "-" Vector__XXX
 SG_ DAS_adaptiveHighBeamIsFaulted : 49|1@1+ (1,0) [0|1] "" Vector__XXX
 SG_ DAS_restrictDoorReleaseLeft : 50|1@1+ (1,0) [0|1] "" Vector__XXX
 SG_ DAS_restrictDoorReleaseRight : 51|1@1+ (1,0) [0|1] "" Vector__XXX
 SG_ DAS_bodyControlsCounter : 52|4@1+ (1,0) [0|15] "" Vector__XXX
 SG_ DAS_bodyControlsChecksum : 56|8@1+ (1,0) [0|255] "" Vector__XXX

BO_ 634 DIF_hvStatus: 7 DIF
 SG_ DIF_hvStatusChecksum : 0|8@1+ (1,0) [0|255] "" Vector__XXX
 SG_ DIF_hvStatusCounter : 8|4@1+ (1,0) [0|15] "" Vector__XXX
 SG_ DIF_hvilCurrent : 12|8@1+ (0.1,0) [0|25.5] "mA" Vector__XXX
 SG_ DIF_hvilCmVoltage : 20|8@1+ (0.08,0) [0|20.4] "V" Vector__XXX
 SG_ DIF_hvilStatus : 28|2@1+ (1,0) [0|2] "" Vector__XXX
 SG_ DIF_hvilSupplyState : 30|2@1+ (1,0) [0|3] "" Vector__XXX
 SG_ DIF_activeDischargeCtrl : 32|1@1+ (1,0) [0|1] "" Vector__XXX
 SG_ DIF_activeDischargeStatus : 33|1@1+ (1,0) [0|1] "" Vector__XXX
 SG_ DIF_vBat : 34|10@1+ (1,0) [0|1023] "V" Vector__XXX
 SG_ DIF_vBatQF : 44|1@1+ (1,0) [0|1] "" Vector__XXX
 SG_ DIF_powerStageSafeState : 45|2@1+ (1,0) [0|3] "" Vector__XXX
 SG_ DIF_fluxState : 48|4@1+ (1,0) [0|15] "" Vector__XXX
 SG_ DIF_vBusDiag : 52|1@1+ (1,0) [0|1] "" Vector__XXX
 SG_ DIF_gateDriveState : 53|3@1+ (1,0) [0|7] "" Vector__XXX

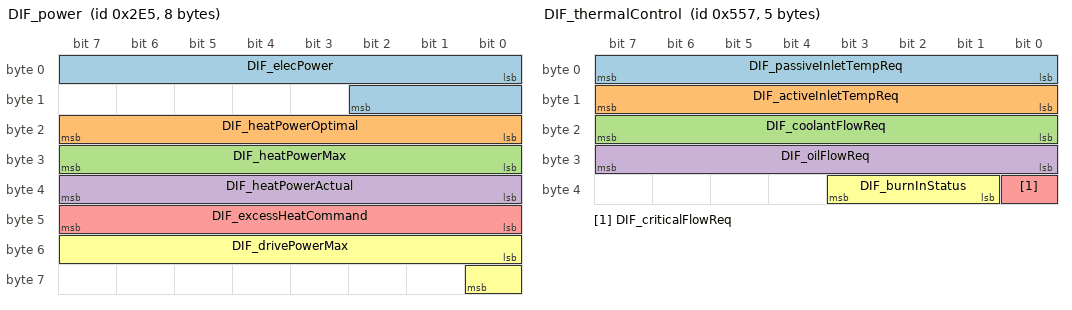
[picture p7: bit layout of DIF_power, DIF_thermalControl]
BO_ 741 DIF_power: 8 DIF
 SG_ DIF_elecPower : 0|11@1- (0.5,0) [-500|500] "kW" Vector__XXX
 SG_ DIF_heatPowerOptimal : 16|8@1+ (0.08,0) [0|20] "kW" Vector__XXX
 SG_ DIF_heatPowerMax : 24|8@1+ (0.08,0) [0|20] "kW" Vector__XXX
 SG_ DIF_heatPowerActual : 32|8@1+ (0.08,0) [0|20] "kW" Vector__XXX
 SG_ DIF_excessHeatCommand : 40|8@1+ (0.08,0) [0|20] "kW" Vector__XXX
 SG_ DIF_drivePowerMax : 48|9@1+ (1,0) [0|400] "kW" Vector__XXX

BO_ 886 DIF_temperature: 8 DIF
 SG_ DIF_tempIndex M : 0|3@1+ (1,0) [0|7] "" Vector__XXX
 SG_ DIF_inverterTQF m0 : 3|2@1+ (1,0) [0|3] "" Vector__XXX
 SG_ DIF_pcbT m0 : 8|8@1+ (1,-40) [-39|215] "DegC" Vector__XXX
 SG_ DIF_inverterT m0 : 16|8@1+ (1,-40) [-40|215] "DegC" Vector__XXX
 SG_ DIF_statorT m0 : 24|8@1+ (1,-40) [-39|215] "DegC" Vector__XXX
 SG_ DIF_dcCapT m0 : 32|8@1+ (1,-40) [-39|215] "DegC" Vector__XXX
 SG_ DIF_heatsinkT m0 : 40|8@1+ (1,-40) [-39|215] "DegC" Vector__XXX
 SG_ DIF_inverterTpct m0 : 48|8@1+ (0.4,0) [0|100] "%" Vector__XXX
 SG_ DIF_statorTpct m0 : 56|8@1+ (0.4,0) [0|100] "%" Vector__XXX
 SG_ DIF_fluidInTemp m2 : 8|8@1+ (1,-40) [-39|215] "DegC" Vector__XXX
 SG_ DIF_normalFetBurnIn m2 : 16|16@1+ (0.00763,0) [0|500] "Hours" Vector__XXX
 SG_ DIF_additionalFetBurnIn m2 : 32|16@1+ (0.00763,0) [0|500] "Hours" Vector__XXX
 SG_ DIF_currentWeibullMiles m3 : 3|16@1+ (8,0) [0|500000] "miles" Vector__XXX
 SG_ DIF_endOfServiceWeibullMiles m3 : 19|16@1+ (8,0) [0|500000] "miles" Vector__XXX
 SG_ DIF_burnInDamageRatio m3 : 35|9@1+ (0.01,0) [0|5] "1" Vector__XXX
 SG_ DIF_inverterSensorEst m3 : 44|8@1+ (1,-40) [-40|120] "C" Vector__XXX
 SG_ DIF_inverterHS1Est m3 : 52|8@1+ (1,-40) [-40|120] "C" Vector__XXX
 SG_ DIF_initialBurnInVehicleOdometer m4 : 8|32@1+ (0.001,0) [0|4294967.294] "km" Vector__XXX
 SG_ DIF_inverterHS2Est m4 : 40|8@1+ (1,-40) [-40|120] "C" Vector__XXX
 SG_ DIF_inverterInletEst m4 : 48|8@1+ (1,-40) [-40|120] "C" Vector__XXX

BO_ 1367 DIF_thermalControl: 5 DIF
 SG_ DIF_passiveInletTempReq : 0|8@1+ (1,-40) [-40|215] "DegC" Vector__XXX
 SG_ DIF_activeInletTempReq : 8|8@1+ (1,-40) [-40|215] "DegC" Vector__XXX
 SG_ DIF_coolantFlowReq : 16|8@1+ (0.2,0) [0|50] "LPM" Vector__XXX
 SG_ DIF_oilFlowReq : 24|8@1+ (0.1,0) [0|25.4] "LPM" Vector__XXX
 SG_ DIF_criticalFlowReq : 32|1@1+ (1,0) [0|1] "" Vector__XXX
 SG_ DIF_burnInStatus : 33|3@1+ (1,0) [0|7] "" Vector__XXX

BO_ 2005 DIR_debug: 8 DIR
 SG_ DIR_debugSelector M : 0|8@1+ (1,0) [0|255] "" Vector__XXX
 SG_ DIR_phaseOutBusbarTemp m70 : 8|8@1+ (1,-40) [-39|215] "DegC" Vector__XXX
 SG_ DIR_phaseOutBusbarWeldTemp m70 : 16|8@1+ (1,-40) [-39|215] "DegC" Vector__XXX
 SG_ DIR_phaseOutLugTemp m70 : 24|8@1+ (1,-40) [-39|215] "DegC" Vector__XXX
 SG_ DIR_dcLinkCapTemp m70 : 32|8@1+ (1,-40) [-39|215] "DegC" Vector__XXX
 SG_ DIR_hvDcCableTemp m70 : 40|8@1+ (1,-40) [-39|215] "DegC" Vector__XXX
 SG_ DIR_negDcBusbarTemp m70 : 48|8@1+ (1,-40) [-39|215] "DegC" Vector__XXX
 SG_ DIR_posDcBusbarTemp m70 : 56|8@1+ (1,-40) [-39|215] "DegC" Vector__XXX
 SG_ DIR_statorEndWindingTemp m72 : 8|8@1+ (1,-40) [-39|215] "DegC" Vector__XXX
 SG_ DIR_rotorMaxMagnetTemp m72 : 16|8@1+ (1,-40) [-39|215] "DegC" Vector__XXX
 SG_ DIR_lightSenseV m72 : 24|6@1+ (0.1,0) [0|3.3] "V" Vector__XXX
 SG_ DIR_pyroSenseV m72 : 30|8@1+ (0.02,0) [0|3.3] "V" Vector__XXX
 SG_ DIR_statorSlotWindingTemp m72 : 46|8@1+ (1,-40) [-39|215] "DegC" Vector__XXX
 SG_ DIR_intervalMaxHvBusV m72 : 54|10@1+ (1,0) [0|1023] "V" Vector__XXX

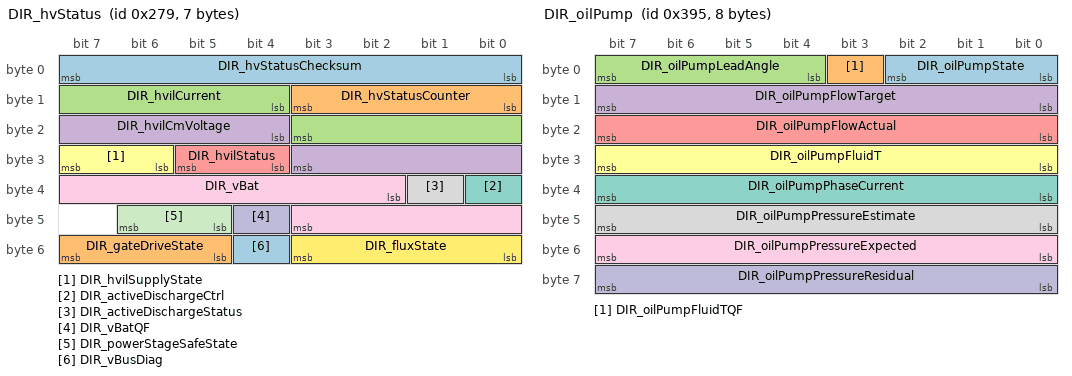
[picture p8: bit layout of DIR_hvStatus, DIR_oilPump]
BO_ 633 DIR_hvStatus: 7 DIR
 SG_ DIR_hvStatusChecksum : 0|8@1+ (1,0) [0|255] "" Vector__XXX
 SG_ DIR_hvStatusCounter : 8|4@1+ (1,0) [0|15] "" Vector__XXX
 SG_ DIR_hvilCurrent : 12|8@1+ (0.1,0) [0|25.5] "mA" Vector__XXX
 SG_ DIR_hvilCmVoltage : 20|8@1+ (0.08,0) [0|20.4] "V" Vector__XXX
 SG_ DIR_hvilStatus : 28|2@1+ (1,0) [0|2] "" Vector__XXX
 SG_ DIR_hvilSupplyState : 30|2@1+ (1,0) [0|3] "" Vector__XXX
 SG_ DIR_activeDischargeCtrl : 32|1@1+ (1,0) [0|1] "" Vector__XXX
 SG_ DIR_activeDischargeStatus : 33|1@1+ (1,0) [0|1] "" Vector__XXX
 SG_ DIR_vBat : 34|10@1+ (1,0) [0|1023] "V" Vector__XXX
 SG_ DIR_vBatQF : 44|1@1+ (1,0) [0|1] "" Vector__XXX
 SG_ DIR_powerStageSafeState : 45|2@1+ (1,0) [0|3] "" Vector__XXX
 SG_ DIR_fluxState : 48|4@1+ (1,0) [0|15] "" Vector__XXX
 SG_ DIR_vBusDiag : 52|1@1+ (1,0) [0|1] "" Vector__XXX
 SG_ DIR_gateDriveState : 53|3@1+ (1,0) [0|7] "" Vector__XXX

BO_ 821 DIR_info: 8 DIR
 SG_ DIR_infoIndex M : 0|8@1+ (1,0) [0|255] "" Vector__XXX
 SG_ DIR_buildType m10 : 8|3@1+ (1,0) [0|7] "" Vector__XXX
 SG_ DIR_buildConfigurationId m10 : 16|16@1+ (1,0) [0|65535] "" Vector__XXX
 SG_ DIR_hardwareId m10 : 32|8@1+ (1,0) [0|252] "" Vector__XXX
 SG_ DIR_componentId m10 : 48|16@1+ (1,0) [0|65535] "" Vector__XXX
 SG_ DIR_pcbaId m11 : 16|8@1+ (1,0) [0|255] "" Vector__XXX
 SG_ DIR_assemblyId m11 : 24|8@1+ (1,0) [0|255] "" Vector__XXX
 SG_ DIR_usageId m11 : 32|16@1+ (1,0) [0|65535] "" Vector__XXX
 SG_ DIR_subUsageId m11 : 48|16@1+ (1,0) [0|65535] "" Vector__XXX
 SG_ DIR_motorType m12 : 8|5@1+ (1,0) [1|31] "" Vector__XXX
 SG_ DIR_siliconType m12 : 16|1@1+ (1,0) [0|1] "" Vector__XXX
 SG_ DIR_mechSafeStateType m12 : 24|2@1+ (1,0) [1|3] "" Vector__XXX
 SG_ DIR_applicationCrc m13 : 32|32@1+ (1,0) [0|4294967295] "" Vector__XXX
 SG_ DIR_oilPumpBuildType m16 : 8|3@1+ (1,0) [0|7] "" Vector__XXX
 SG_ DIR_oilPumpAppCrc m16 : 16|32@1+ (1,0) [0|4294967295] "" Vector__XXX
 SG_ DIR_FPGA_version m16 : 48|8@1+ (1,0) [0|254] "" Vector__XXX
 SG_ DIR_bootGitHash m18 : 8|56@1+ (1,0) [0|7.20575940379e+16] "" Vector__XXX
 SG_ DIR_infoBootLdUdsProtocolVersion m20 : 8|8@1+ (1,0) [0|255] "" Vector__XXX
 SG_ DIR_bootloaderCrc m20 : 32|32@1+ (1,0) [0|4294967295] "" Vector__XXX
 SG_ DIR_oilPumpPcbaId m33 : 8|8@1+ (1,0) [0|255] "" Vector__XXX
 SG_ DIR_oilPumpAssemblyId m33 : 16|8@1+ (1,0) [0|255] "" Vector__XXX
 SG_ DIR_oilPumpUsageId m33 : 24|16@1+ (1,0) [0|65535] "" Vector__XXX
 SG_ DIR_refRotorFlux m35 : 8|16@1+ (0.0001,0) [0|6.5535] "Wb" Vector__XXX
 SG_ DIR_refRotorOffset m35 : 24|12@1- (0.1,0) [-180|180] "deg" Vector__XXX
 SG_ DIR_speedWearTotal m36 : 8|8@1+ (0.4,0) [0|100] "%" Vector__XXX
 SG_ DIR_torqueWearTotal m36 : 24|8@1+ (0.02,0) [0|5.08] "1" Vector__XXX

BO_ 917 DIR_oilPump: 8 DIR
 SG_ DIR_oilPumpState : 0|3@1+ (1,0) [0|6] "" Vector__XXX
 SG_ DIR_oilPumpFluidTQF : 3|1@1+ (1,0) [0|1] "" Vector__XXX
 SG_ DIR_oilPumpLeadAngle : 4|4@1+ (1.875,0) [0|28.125] "degrees" Vector__XXX
 SG_ DIR_oilPumpFlowTarget : 8|8@1+ (0.1,0) [0|25.4] "LPM" Vector__XXX
 SG_ DIR_oilPumpFlowActual : 16|8@1+ (0.1,0) [0|25.4] "LPM" Vector__XXX
 SG_ DIR_oilPumpFluidT : 24|8@1+ (1,-40) [-40|214] "DegC" Vector__XXX
 SG_ DIR_oilPumpPhaseCurrent : 32|8@1+ (0.1,0) [0|25.4] "A" Vector__XXX
 SG_ DIR_oilPumpPressureEstimate : 40|8@1+ (2,0) [0|500] "kPa" Vector__XXX
 SG_ DIR_oilPumpPressureExpected : 48|8@1+ (2,0) [0|500] "kPa" Vector__XXX
 SG_ DIR_oilPumpPressureResidual : 56|8@1+ (4,-500) [-500|500] "kPa" Vector__XXX

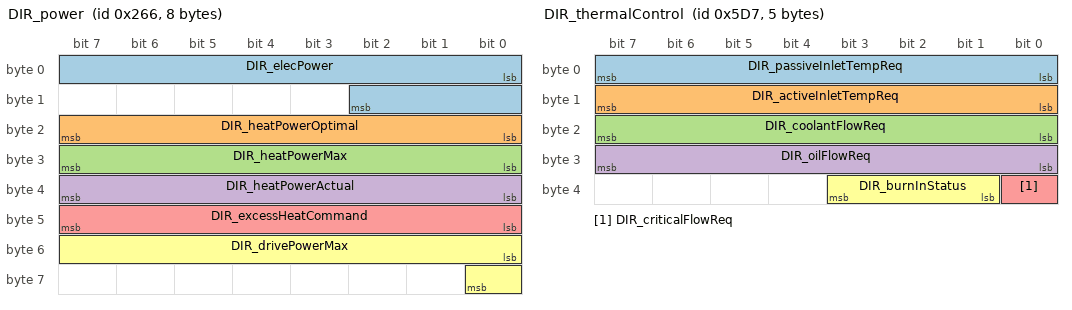
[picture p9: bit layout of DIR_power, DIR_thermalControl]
BO_ 614 DIR_power: 8 DIR
 SG_ DIR_elecPower : 0|11@1- (0.5,0) [-500|500] "kW" Vector__XXX
 SG_ DIR_heatPowerOptimal : 16|8@1+ (0.08,0) [0|20] "kW" Vector__XXX
 SG_ DIR_heatPowerMax : 24|8@1+ (0.08,0) [0|20] "kW" Vector__XXX
 SG_ DIR_heatPowerActual : 32|8@1+ (0.08,0) [0|20] "kW" Vector__XXX
 SG_ DIR_excessHeatCommand : 40|8@1+ (0.08,0) [0|20] "kW" Vector__XXX
 SG_ DIR_drivePowerMax : 48|9@1+ (1,0) [0|400] "kW" Vector__XXX

BO_ 789 DIR_temperature: 8 DIR
 SG_ DIR_tempIndex M : 0|3@1+ (1,0) [0|7] "" Vector__XXX
 SG_ DIR_inverterTQF m0 : 3|2@1+ (1,0) [0|3] "" Vector__XXX
 SG_ DIR_pcbT m0 : 8|8@1+ (1,-40) [-39|215] "DegC" Vector__XXX
 SG_ DIR_inverterT m0 : 16|8@1+ (1,-40) [-40|215] "DegC" Vector__XXX
 SG_ DIR_statorT m0 : 24|8@1+ (1,-40) [-39|215] "DegC" Vector__XXX
 SG_ DIR_dcCapT m0 : 32|8@1+ (1,-40) [-39|215] "DegC" Vector__XXX
 SG_ DIR_heatsinkT m0 : 40|8@1+ (1,-40) [-39|215] "DegC" Vector__XXX
 SG_ DIR_inverterTpct m0 : 48|8@1+ (0.4,0) [0|100] "%" Vector__XXX
 SG_ DIR_statorTpct m0 : 56|8@1+ (0.4,0) [0|100] "%" Vector__XXX
 SG_ DIR_fluidInTemp m2 : 8|8@1+ (1,-40) [-39|215] "DegC" Vector__XXX
 SG_ DIR_normalFetBurnIn m2 : 16|16@1+ (0.00763,0) [0|500] "Hours" Vector__XXX
 SG_ DIR_additionalFetBurnIn m2 : 32|16@1+ (0.00763,0) [0|500] "Hours" Vector__XXX
 SG_ DIR_currentWeibullMiles m3 : 3|16@1+ (8,0) [0|500000] "miles" Vector__XXX
 SG_ DIR_endOfServiceWeibullMiles m3 : 19|16@1+ (8,0) [0|500000] "miles" Vector__XXX
 SG_ DIR_burnInDamageRatio m3 : 35|9@1+ (0.01,0) [0|5] "1" Vector__XXX
 SG_ DIR_inverterSensorEst m3 : 44|8@1+ (1,-40) [-40|120] "C" Vector__XXX
 SG_ DIR_inverterHS1Est m3 : 52|8@1+ (1,-40) [-40|120] "C" Vector__XXX
 SG_ DIR_initialBurnInVehicleOdometer m4 : 8|32@1+ (0.001,0) [0|4294967.294] "km" Vector__XXX
 SG_ DIR_inverterHS2Est m4 : 40|8@1+ (1,-40) [-40|120] "C" Vector__XXX
 SG_ DIR_inverterInletEst m4 : 48|8@1+ (1,-40) [-40|120] "C" Vector__XXX

BO_ 1495 DIR_thermalControl: 5 DIR
 SG_ DIR_passiveInletTempReq : 0|8@1+ (1,-40) [-40|215] "DegC" Vector__XXX
 SG_ DIR_activeInletTempReq : 8|8@1+ (1,-40) [-40|215] "DegC" Vector__XXX
 SG_ DIR_coolantFlowReq : 16|8@1+ (0.2,0) [0|50] "LPM" Vector__XXX
 SG_ DIR_oilFlowReq : 24|8@1+ (0.1,0) [0|25.4] "LPM" Vector__XXX
 SG_ DIR_criticalFlowReq : 32|1@1+ (1,0) [0|1] "" Vector__XXX
 SG_ DIR_burnInStatus : 33|3@1+ (1,0) [0|7] "" Vector__XXX

BO_TX_BU_ 909 : APP;
BO_TX_BU_ 818 : BMS;
BO_TX_BU_ 1138 : BMS;
BO_TX_BU_ 722 : BMS;
BO_TX_BU_ 850 : BMS;
BO_TX_BU_ 306 : BMS;
BO_TX_BU_ 768 : BMS;
BO_TX_BU_ 978 : BMS;
BO_TX_BU_ 1010 : BMS;
BO_TX_BU_ 882 : BMS;
BO_TX_BU_ 946 : BMS;
BO_TX_BU_ 914 : BMS;
BO_TX_BU_ 594 : BMS;
BO_TX_BU_ 674 : BMS;
BO_TX_BU_ 658 : BMS;
BO_TX_BU_ 1170 : BMS;
BO_TX_BU_ 530 : BMS;
BO_TX_BU_ 786 : BMS;
BO_TX_BU_ 754 : BMS;
BO_TX_BU_ 810 : BMS;
BO_TX_BU_ 796 : CC;
BO_TX_BU_ 797 : CC;
BO_TX_BU_ 812 : CC;
BO_TX_BU_ 870 : CMPD;
BO_TX_BU_ 679 : CMPD;
BO_TX_BU_ 867 : CMP;
BO_TX_BU_ 669 : CP;
BO_TX_BU_ 541 : CP;
BO_TX_BU_ 1342 : CP;
BO_TX_BU_ 1885 : CP;
BO_TX_BU_ 989 : CP;
BO_TX_BU_ 605 : CP;
BO_TX_BU_ 893 : CP;
BO_TX_BU_ 1001 : DAS;
BO_TX_BU_ 634 : DIF;
BO_TX_BU_ 741 : DIF;
BO_TX_BU_ 886 : DIF;
BO_TX_BU_ 1367 : DIF;
BO_TX_BU_ 2005 : DIR;
BO_TX_BU_ 633 : DIR;
BO_TX_BU_ 821 : DIR;
BO_TX_BU_ 917 : DIR;
BO_TX_BU_ 614 : DIR;
BO_TX_BU_ 789 : DIR;
BO_TX_BU_ 1495 : DIR;

CM_ "Tesla Model 3 CAN bus database; bus VEH; firmware 2025.20.8. Decoded CAN signal definitions (layout, scaling, units, value tables).";
CM_ BU_ APP "Driver assistance computer (primary)";
CM_ BU_ BMS "High-voltage battery management system";
CM_ BU_ CC "Charge cable controller";
CM_ BU_ CMP "A/C compressor";
CM_ BU_ CMPD "CMPD ECU";
CM_ BU_ CP "Charge port controller";
CM_ BU_ DAS "Driver assistance computer";
CM_ BU_ DI "Drive inverter";
CM_ BU_ DIF "Front drive inverter";
CM_ BU_ DIR "Rear drive inverter";
CM_ BU_ EPBL "Left electric parking brake";
CM_ BU_ EPBR "Right electric parking brake";
CM_ BU_ EVSE "EVSE ECU";
CM_ BU_ FC "FC ECU";
CM_ BU_ GTW "Gateway";
CM_ BU_ HCML "HCML ECU";
CM_ BU_ HCMR "HCMR ECU";
CM_ BU_ HVP "High-voltage processor (pack contactor and isolation controller)";
CM_ BU_ ICR "ICR ECU";
CM_ BU_ PCS "Power conversion system (on-board charger and DC-DC converter)";
CM_ BU_ PM "PM ECU";
CM_ BU_ PMF "PMF ECU";
CM_ BU_ PMR "PMR ECU";
CM_ BU_ PTC "Cabin heater";
CM_ BU_ SCCM "Steering column control module";
CM_ BU_ SDCR "SDCR ECU";
CM_ BU_ TAS "Air suspension controller";
CM_ BU_ UMC "UMC ECU";
CM_ BU_ VC "VC ECU";
CM_ BU_ VCFRONT "Front body controller";
CM_ BU_ VCLEFT "Left body controller";
CM_ BU_ VCRIGHT "Right body controller";
CM_ BU_ VCSEC "Vehicle security controller";
CM_ BO_ 909 "Driver assistance computer (primary) message: VC info message";
CM_ SG_ 909 APP_inTunnel "Driver assistance computer (primary): in tunnel; raw 0 = signal not available (SNA)";
CM_ SG_ 909 APP_windshieldHeaterOnReason "Reports the reason why Autopilot (AP) is turning windshield heater on.; raw 0 = signal not available (SNA)";
CM_ SG_ 909 APP_selfieCameraBlocked "Indicates if the selfie camera is currently blocked, or if this selfie camera model doesn't report lux.; raw 0 = signal not available (SNA)";
CM_ SG_ 909 APP_selfieCameraLUX "Reports lux reading. Note that selfie camera lux is not currently calibrated against other cameras so the range is different.; raw 255 = signal not available (SNA)";
CM_ SG_ 909 APP_sceneTagClearlyRaining "Indicates if the vision scene tag is clearly raining.; raw 0 = signal not available (SNA)";
CM_ SG_ 909 APP_sceneTagFog "Indicates if the vision scene tag detects fog.; raw 0 = signal not available (SNA)";
CM_ SG_ 909 APP_sceneTagFullyBlocked "Indicates if the vision scene tag detects a fully blocked view.; raw 0 = signal not available (SNA)";
CM_ SG_ 909 APP_sceneTagIndoors "Indicates if the vision scene tag detects an indoor environment.; raw 0 = signal not available (SNA)";
CM_ SG_ 909 APP_sceneTagLensFlare "Indicates if the vision scene tag detects lens flare.; raw 0 = signal not available (SNA)";
CM_ SG_ 909 APP_sceneTagRaining "Indicates if the vision scene tag detects raining conditions.; raw 0 = signal not available (SNA)";
CM_ SG_ 909 APP_sceneTagSevereWeather "Indicates if the vision scene tag detects severe weather conditions.; raw 0 = signal not available (SNA)";
CM_ SG_ 909 APP_sceneTagSnowing "Indicates if the vision scene tag detects snowing conditions.; raw 0 = signal not available (SNA)";
CM_ SG_ 909 APP_sceneTagSnowyRoad "Indicates if the vision scene tag detects snowy road conditions.; raw 0 = signal not available (SNA)";
CM_ SG_ 909 APP_sceneTagSunGlare "Indicates if the vision scene tag detects sun glare conditions.; raw 0 = signal not available (SNA)";
CM_ SG_ 909 APP_sceneTagTunnel "Indicates if the vision scene tag detects a tunnel environment.; raw 0 = signal not available (SNA)";
CM_ SG_ 909 APP_sceneTagWetRoad "Indicates if the vision scene tag detects wet road conditions.; raw 0 = signal not available (SNA)";
CM_ SG_ 909 APP_fisheyeInPathVisibility "Driver assistance computer (primary): fisheye in path visibility; raw 0 = signal not available (SNA)";
CM_ SG_ 909 APP_fisheyeOverallVisibility "Driver assistance computer (primary): fisheye overall visibility; raw 0 = signal not available (SNA)";
CM_ SG_ 909 APP_mainInPathVisibility "Driver assistance computer (primary): main in path visibility; raw 0 = signal not available (SNA)";
CM_ SG_ 909 APP_mainOverallVisibility "Driver assistance computer (primary): main overall visibility; raw 0 = signal not available (SNA)";
CM_ SG_ 909 APP_narrowInPathVisibility "Driver assistance computer (primary): narrow in path visibility; raw 0 = signal not available (SNA)";
CM_ SG_ 909 APP_narrowOverallVisibility "Driver assistance computer (primary): narrow overall visibility; raw 0 = signal not available (SNA)";
CM_ SG_ 909 APP_frontCamOcclusionType "Reports the current type of what is obstructing the front camera vision.";
CM_ BO_ 818 "High-voltage battery management system message: bmb min max";
CM_ SG_ 818 BMS_bmbMinMaxMultiplexer "High-voltage battery management system: bmb min max multiplexer";
CM_ SG_ 818 BMS_thermistorNumTMin "BMB module number with minimum temperature.";
CM_ SG_ 818 BMS_thermistorNumTMax "BMB module number with maximum temperature.";
CM_ SG_ 818 BMS_thermistorTMax "Max temperature of all valid filtered thermistors";
CM_ SG_ 818 BMS_thermistorTMin "Min temperature of all valid filtered thermistors";
CM_ SG_ 818 BMS_thermistorTAvg "Average temperature of all valid filtered thermistors";
CM_ SG_ 818 BMS_brickVoltageMax "Brick voltage maximum.";
CM_ SG_ 818 BMS_brickVoltageMin "Brick voltage minimum.";
CM_ SG_ 818 BMS_brickNumVoltageMax "Brick number with maximum voltage (1 indexed)";
CM_ SG_ 818 BMS_brickNumVoltageMin "Brick number with minimum voltage (1 indexed)";
CM_ BO_ 1138 "High-voltage battery management system message: charge info";
CM_ SG_ 1138 BMS_cellChargeDcCurrentLimit "DC current target based on cell voltage & temp tables";
CM_ SG_ 1138 BMS_voltageRegCurrentTarget "DC current target based on voltage regulator";
CM_ SG_ 1138 BMS_vehicleChargeDcCurrentLimit "Charge current target after all aggregating all vehicle-side limits, exclude EVSE limits";
CM_ SG_ 1138 BMS_chargeCurrentLimitMode "BMS charging current limiting factor";
CM_ SG_ 1138 BMS_timeToFinishHeatForCharge "High-voltage battery management system: time to finish heat for charge; raw 127 = signal not available (SNA)";
CM_ SG_ 1138 BMS_diNodeModelTemp "High-voltage battery management system: di node model temp; raw 2047 = signal not available (SNA)";
CM_ BO_ 722 "High-voltage battery management system message: drive limits";
CM_ SG_ 722 BMS_minBusVoltage "Calculated min bus voltage limit";
CM_ SG_ 722 BMS_maxBusVoltage "Calculated max bus voltage limit for the pack";
CM_ SG_ 722 BMS_maxChargeCurrent "Calculated max charge current limit for the pack";
CM_ SG_ 722 BMS_maxDischargeCurrent "Calculated max discharge current limit for the pack";
CM_ BO_ 850 "High-voltage battery management system message: energy status";
CM_ SG_ 850 BMS_energyStatusMultiplexer "High-voltage battery management system: energy status multiplexer";
CM_ SG_ 850 BMS_nominalFullPackEnergy "Full pack energy based on calculated pack energy from the full pack discharge energy walk; raw 65535 = signal not available (SNA)";
CM_ SG_ 850 BMS_nominalEnergyRemaining "Nominal energy remaining based on calculated pack energy from the nominal discharge energy walk; raw 65535 = signal not available (SNA)";
CM_ SG_ 850 BMS_idealEnergyRemaining "Ideal energy remaining based on calculated pack energy from ideal discharge energy walk; raw 65535 = signal not available (SNA)";
CM_ SG_ 850 BMS_fullChargeComplete "Indicates BMS is fully charged";
CM_ SG_ 850 BMS_energyBuffer "Rough indication of confidence in the energy estimation; raw 65535 = signal not available (SNA)";
CM_ SG_ 850 BMS_expectedEnergyRemaining "High-voltage battery management system: expected energy remaining; raw 65535 = signal not available (SNA)";
CM_ SG_ 850 BMS_energyToChargeComplete "Calculated energy required to reach charge complete; raw 65535 = signal not available (SNA)";
CM_ SG_ 850 BMS_energyRemainingDisplay "Rubber-banding energy remaining to be used for the UI facing miles remaining display; raw 65535 = signal not available (SNA)";
CM_ SG_ 850 BMS_energyRemainingTDisplay "Rubber-banding energy remaining to be used for the UI facing miles remaining display; raw 65535 = signal not available (SNA)";
CM_ SG_ 850 BMS_energyDisplayErrorBlendRate "Rubber-banding blend rate to be used to ensure consistency between the gauge display and UI energy algorithms";
CM_ SG_ 850 BMS_userFacingSoe "User facing state of energy; raw 2047 = signal not available (SNA)";
CM_ BO_ 306 "High-voltage battery management system message: hv bus status";
CM_ SG_ 306 BMS_packVoltage "Measures voltage on the battery side of the High Voltage (HV) contactors.";
CM_ SG_ 306 BMS_packCurrent "Current measured at the HV contactors of the HV battery.; raw 32768 = signal not available (SNA)";
CM_ SG_ 306 BMS_currentUnfiltered "Pack current with no filters applied; raw 32768 = signal not available (SNA)";
CM_ SG_ 306 BMS_chgTimeToFull "Estimated time remaining until charge termination percent will be reached; raw 4095 = signal not available (SNA)";
CM_ BO_ 768 "High-voltage battery management system message: info";
CM_ SG_ 768 BMS_infoIndex "High-voltage battery management system: info index";
CM_ SG_ 768 BMS_buildType "High-voltage battery management system: build type";
CM_ SG_ 768 BMS_buildConfigId "High-voltage battery management system: build config id";
CM_ SG_ 768 BMS_hardwareId "High-voltage battery management system: hardware id";
CM_ SG_ 768 BMS_componentId "High-voltage battery management system: component id";
CM_ SG_ 768 BMS_pcbaId "BMS' assigned PCBA ID";
CM_ SG_ 768 BMS_assemblyId "BMS' assigned assembly ID";
CM_ SG_ 768 BMS_usageId "BMS' assigned usage ID";
CM_ SG_ 768 BMS_subUsageId "BMS' assigned subusage ID";
CM_ SG_ 768 BMS_platformType "High-voltage battery management system: platform type";
CM_ SG_ 768 BMS_appCrc "High-voltage battery management system: app crc";
CM_ SG_ 768 BMS_appGitHash "High-voltage battery management system: app git hash";
CM_ SG_ 768 BMS_bootGitHash "High-voltage battery management system: boot git hash";
CM_ SG_ 768 BMS_bootUdsProtoVersion "High-voltage battery management system: boot uds proto version";
CM_ SG_ 768 BMS_bootCrc "High-voltage battery management system: boot crc";
CM_ BO_ 978 "High-voltage battery management system message: kwh counter";
CM_ SG_ 978 BMS_kwhDischargeTotal "Total energy-lost kWh count during discharging";
CM_ SG_ 978 BMS_kwhChargeTotal "Total energy-gained kWh count during charging";
CM_ BO_ 1010 "High-voltage battery management system message: kwh counters multiplexed";
CM_ SG_ 1010 BMS_kwhCounter_Id "High-voltage battery management system: kwh counter id";
CM_ SG_ 1010 BMS_acChargerKwhTotal "Total energy-gained kWh count during AC charge";
CM_ SG_ 1010 BMS_dcChargerKwhTotal "Total energy-gained kWh count during DC charging";
CM_ SG_ 1010 BMS_kwhRegenChargeTotal "Total energy-gained kWh count during charging with regen";
CM_ SG_ 1010 BMS_kwhDriveDischargeTotal "Total energy-lost kWh count during discharging while driving";
CM_ SG_ 1010 BMS_kwhDischargeTotalModule1 "Total energy-lost kWh count during discharging for module number (1 indexed)";
CM_ SG_ 1010 BMS_kwhChargeTotalModule1 "Total energy-gained kWh count for module number (1 indexed)";
CM_ SG_ 1010 BMS_kwhAcChargeTotalModule1 "Total energy-gained kWh count during AC charge for module number (1 indexed)";
CM_ SG_ 1010 BMS_kwhDcChargeTotalModule1 "Total energy-gained kWh count during DC charge for module number (1 indexed)";
CM_ SG_ 1010 BMS_kwhDischargeTotalModule2 "Total energy-lost kWh count during discharging for module number (1 indexed)";
CM_ SG_ 1010 BMS_kwhChargeTotalModule2 "Total energy-gained kWh count for module number (1 indexed)";
CM_ SG_ 1010 BMS_kwhAcChargeTotalModule2 "Total energy-gained kWh count during AC charge for module number (1 indexed)";
CM_ SG_ 1010 BMS_kwhDcChargeTotalModule2 "Total energy-gained kWh count during DC charge for module number (1 indexed)";
CM_ SG_ 1010 BMS_kwhDischargeTotalModule3 "Total energy-lost kWh count during discharging for module number (1 indexed)";
CM_ SG_ 1010 BMS_kwhChargeTotalModule3 "Total energy-gained kWh count for module number (1 indexed)";
CM_ SG_ 1010 BMS_kwhAcChargeTotalModule3 "Total energy-gained kWh count during AC charge for module number (1 indexed)";
CM_ SG_ 1010 BMS_kwhDcChargeTotalModule3 "Total energy-gained kWh count during DC charge for module number (1 indexed)";
CM_ SG_ 1010 BMS_kwhDischargeTotalModule4 "Total energy-lost kWh count during discharging for module number (1 indexed)";
CM_ SG_ 1010 BMS_kwhChargeTotalModule4 "Total energy-gained kWh count for module number (1 indexed)";
CM_ SG_ 1010 BMS_kwhAcChargeTotalModule4 "Total energy-gained kWh count during AC charge for module number (1 indexed)";
CM_ SG_ 1010 BMS_kwhDcChargeTotalModule4 "Total energy-gained kWh count during DC charge for module number (1 indexed)";
CM_ BO_ 882 "High-voltage battery management system message: log1";
CM_ SG_ 882 BMS_log1MuxId "High-voltage battery management system: log1 mux id";
CM_ SG_ 882 BMS_extDcPrechargeVoltageLimit "High-voltage battery management system: ext dc precharge voltage limit";
CM_ SG_ 882 BMS_dcChargeCurrentRequest "The BMS's instantaneous DC charge current request to the EVSE";
CM_ SG_ 882 BMS_dcChargeCurrentLimit "The vehicle's charge current limit on a DC EVSE's output";
CM_ SG_ 882 BMS_dcDischargeEnabled "High-voltage battery management system: dc discharge enabled";
CM_ SG_ 882 BMS_rippleChargeRetryCount "High-voltage battery management system: ripple charge retry count";
CM_ SG_ 882 BMS_dcChargeVoltageLimit "The vehicle's charge voltage limit on a DC EVSE's output";
CM_ SG_ 882 BMS_dcChargePowerLimit "Max power limit for pack during DC charging";
CM_ SG_ 882 BMS_maxExtIsoFcLinkV "The max voltage read on the FC link during the external isolation check";
CM_ SG_ 882 BMS_socByDeltaVEnabled "High-voltage battery management system: soc by delta v enabled";
CM_ SG_ 882 BMS_socByDvMaxSocLimit "High-voltage battery management system: soc by dv max soc limit";
CM_ SG_ 882 BMS_socByDvVoltageChangeOverAh "High-voltage battery management system: soc by dv voltage change over ah";
CM_ SG_ 882 BMS_socByDvMaxSocByAhCorrected "High-voltage battery management system: soc by dv max soc by ah corrected";
CM_ SG_ 882 BMS_socByDvMaxBrickVoltage "High-voltage battery management system: soc by dv max brick voltage";
CM_ SG_ 882 BMS_socByDvMaxBrickId "High-voltage battery management system: soc by dv max brick id";
CM_ BO_ 946 "High-voltage battery management system message: log2";
CM_ SG_ 946 BMS_log2MuxId "High-voltage battery management system: log2 mux id";
CM_ SG_ 946 BMS_cacAvg "BMS Calculated Ah Capacity (CAC). This is the average of all the brick CACs";
CM_ SG_ 946 BMS_cacMin "BMS Calculated Ah Capacity (CAC). This is the min of all the brick CACs";
CM_ SG_ 946 BMS_cacMinBrickId "High-voltage battery management system: cac min brick id";
CM_ SG_ 946 BMS_cacMax "BMS Calculated Ah Capacity (CAC). This is the max of all the brick CACs";
CM_ SG_ 946 BMS_cacMaxBrickId "High-voltage battery management system: cac max brick id";
CM_ SG_ 946 BMS_acRippleConfigNvramValid "High-voltage battery management system: ac ripple config nvram valid";
CM_ SG_ 946 BMS_hvChain_useLeakyBucket "Is the leaky bucket being used - an indicator of the HV Chain Model health";
CM_ SG_ 946 BMS_hvChain_iLimit "High-voltage battery management system: hv chain i limit; raw 16383 = signal not available (SNA)";
CM_ SG_ 946 BMS_hvChain_limitingState "High-voltage battery management system: hv chain limiting state; raw 511 = signal not available (SNA)";
CM_ SG_ 946 BMS_hvChain_limitingStateTempera "High-voltage battery management system: hv chain limiting state temperature; raw 4096 = signal not available (SNA)";
CM_ SG_ 946 BMS_acRippleIsSupported "High-voltage battery management system: ac ripple is supported";
CM_ SG_ 946 BMS_acRippleStartTemperatureMax "High-voltage battery management system: ac ripple start temperature max";
CM_ SG_ 946 BMS_acRippleStartTemperatureMin "High-voltage battery management system: ac ripple start temperature min";
CM_ SG_ 946 BMS_fcLinkTestDecayTime "High-voltage battery management system: fc link test decay time; raw 1023 = signal not available (SNA)";
CM_ SG_ 946 BMS_fcLinkTestTimeSinceLastRun "High-voltage battery management system: fc link test time since last run";
CM_ SG_ 946 BMS_pcsPrechargeTargetVoltage "Target voltage for precharging HV bus";
CM_ SG_ 946 BMS_recentOvUvAlert "At least one of the Brick OV or UV alerts has been active recently; consumed by BMS_a049_SW_Thermal_Event set condition";
CM_ SG_ 946 BMS_recentIsoAlert "At least one of the isolation alerts has been active recently; consumed by BMS_a049_SW_Thermal_Event set condition";
CM_ SG_ 946 BMS_recentBmbMiaAlert "At least one of the BMB communication alerts has been active recently; consumed by BMS_a049_SW_Thermal_Event set condition";
CM_ SG_ 946 BMS_cacBlendingConfigNvramValid "High-voltage battery management system: cac blending config nvram valid";
CM_ SG_ 946 BMS_cacBlendingEnabled "High-voltage battery management system: cac blending enabled";
CM_ SG_ 946 BMS_cacBlendPercentPerCycle "High-voltage battery management system: cac blend percent per cycle";
CM_ SG_ 946 BMS_energyVariableChgRequested "High-voltage battery management system: energy variable chg requested";
CM_ SG_ 946 BMS_packRestTime "Minimum resting time of all bricks";
CM_ SG_ 946 BMS_idealEnergyFloor "Ideal energy estimate based on the min bounded SOC that accounts for accumulated shunt error; raw 1023 = signal not available (SNA)";
CM_ SG_ 946 BMS_thmGradientSlopeCondition "High-voltage battery management system: thm gradient slope condition";
CM_ SG_ 946 BMS_recentSlopeConditon "High-voltage battery management system: recent slope conditon";
CM_ SG_ 946 BMS_dynamicEnergyBuffer "BMS estimate of energy error based on SOC measurement inaccuracy; raw 1023 = signal not available (SNA)";
CM_ SG_ 946 BMS_temperatureCondition "High-voltage battery management system: temperature condition";
CM_ SG_ 946 BMS_thmGradientSlope "High-voltage battery management system: thm gradient slope";
CM_ SG_ 946 BMS_thmGradient "High-voltage battery management system: thm gradient";
CM_ SG_ 946 BMS_dSocNormalizedMin "High-voltage battery management system: d soc normalized min; raw 4095 = signal not available (SNA)";
CM_ SG_ 946 BMS_dSocNormalizedFiltMin "High-voltage battery management system: d soc normalized filt min; raw 4095 = signal not available (SNA)";
CM_ SG_ 946 BMS_dSocMinAlpha "minimum calculated alpha value across all bricks and all dSOC calculations; raw 4095 = signal not available (SNA)";
CM_ SG_ 946 BMS_dSocMaxLowAlphaCounter "High-voltage battery management system: d soc max low alpha counter";
CM_ SG_ 946 BMS_dSocMinAlphaBrickID "High-voltage battery management system: d soc min alpha brick ID";
CM_ SG_ 946 BMS_dSocCacMargin "High-voltage battery management system: d soc cac margin; raw 511 = signal not available (SNA)";
CM_ SG_ 946 BMS_lifeModelAvgTempSeverity "High-voltage battery management system: life model avg temp severity; raw 31 = signal not available (SNA)";
CM_ SG_ 946 BMS_lifeModelDepthOfDischargeSev "High-voltage battery management system: life model depth of discharge severity; raw 255 = signal not available (SNA)";
CM_ SG_ 946 BMS_lifeModelHistogramCapacityLo "High-voltage battery management system: life model histogram capacity loss; raw 511 = signal not available (SNA)";
CM_ SG_ 946 BMS_lifeModelHistogramBrickCapac "High-voltage battery management system: life model histogram brick capacity; raw 8191 = signal not available (SNA)";
CM_ SG_ 946 BMS_lifeModelDcrGrowthPercent "High-voltage battery management system: life model dcr growth percent; raw 8192 = signal not available (SNA)";
CM_ SG_ 946 BMS_nominalFullPackEnergyRaw "Non-latched version of BMS_nominalEnergyRemaining; raw 65535 = signal not available (SNA)";
CM_ SG_ 946 BMS_userChargeCalibratingReason "High-voltage battery management system: user charge calibrating reason";
CM_ SG_ 946 BMS_nominalEnergyRemainingBuffer "Buffered version of BMS_nominalEnergyRemaining; raw 65535 = signal not available (SNA)";
CM_ SG_ 946 BMS_idealEnergyRemainingBuffered "Buffered version of BMS_idealEnergyRemaining; raw 65535 = signal not available (SNA)";
CM_ SG_ 946 BMS_largestCacSpreadErrorLower "High-voltage battery management system: largest cac spread error lower; raw 4095 = signal not available (SNA)";
CM_ SG_ 946 BMS_lifeModelAverageCac "High-voltage battery management system: life model average cac; raw 4095 = signal not available (SNA)";
CM_ SG_ 946 BMS_lifeModelCacBrick1 "High-voltage battery management system: life model cac brick1; raw 4095 = signal not available (SNA)";
CM_ SG_ 946 BMS_lifeModelAverageOffset "High-voltage battery management system: life model average offset; raw 512 = signal not available (SNA)";
CM_ SG_ 946 BMS_percentCacUpdatesInTimeWindo "High-voltage battery management system: percent cac updates in time window";
CM_ SG_ 946 BMS_lifeModelMaxCacBrickId "High-voltage battery management system: life model max cac brick id; raw 255 = signal not available (SNA)";
CM_ SG_ 946 BMS_lifeModelMaxCac "High-voltage battery management system: life model max cac; raw 4095 = signal not available (SNA)";
CM_ SG_ 946 BMS_lifeModelMinCacBrickId "High-voltage battery management system: life model min cac brick id; raw 255 = signal not available (SNA)";
CM_ SG_ 946 BMS_lifeModelMinCac "High-voltage battery management system: life model min cac; raw 4095 = signal not available (SNA)";
CM_ SG_ 946 BMS_restingPointCacAvg "High-voltage battery management system: resting point cac avg; raw 4095 = signal not available (SNA)";
CM_ SG_ 946 BMS_cacEstimationSource "High-voltage battery management system: cac estimation source";
CM_ SG_ 946 BMS_synchronizedCacMaxRaw "High-voltage battery management system: synchronized cac max raw; raw 4095 = signal not available (SNA)";
CM_ SG_ 946 BMS_synchronizedCacMinRaw "High-voltage battery management system: synchronized cac min raw; raw 4095 = signal not available (SNA)";
CM_ SG_ 946 BMS_largestSyncCacErrorStartSoc "Start SOC for CAC update from the brick with the highest synchronized CAC error";
CM_ SG_ 946 BMS_largestSyncCacErrorEndSoc "Start SOC for CAC update from the brick with the highest synchronized CAC error";
CM_ SG_ 946 BMS_runtimeSocConfigNvramValid "High-voltage battery management system: runtime soc config nvram valid";
CM_ SG_ 946 BMS_runtimeSocCorrectionsEnabled "High-voltage battery management system: runtime soc corrections enabled";
CM_ SG_ 946 BMS_rubberBandingEnabled "Reports whether rubber banding of output energy corrections is enabled.";
CM_ SG_ 946 BMS_rubberBandingConfigNvramVali "High-voltage battery management system: rubber banding config nvram valid";
CM_ SG_ 946 BMS_runtimeSocMinTempForModel "High-voltage battery management system: runtime soc min temp for model";
CM_ SG_ 946 BMS_energyBufferConfigNvramValid "High-voltage battery management system: energy buffer config nvram valid";
CM_ SG_ 946 BMS_thermalEvent1pDetectConfigDi "High-voltage battery management system: thermal event1p detect config disabled";
CM_ SG_ 946 BMS_sohEnergy "Battery SOH energy estimate. If calibrated SOH capacity is unavailable, this value is a filtered result from brick CACs.; raw 2047 = signal not available (SNA)";
CM_ SG_ 946 BMS_fullCapacitySohEnergy "Energy estimate using nominal brick capacity at maximum SOC using SOH retention test conditions; raw 2047 = signal not available (SNA)";
CM_ SG_ 946 BMS_calibratedCapacitySohEnergy "Energy estimate using CAC from the most recent valid SOH test at maximum SOC using SOH retention test conditions; raw 2047 = signal not available (SNA)";
CM_ SG_ 946 BMS_estimatedCapacitySohEnergy "Energy estimate using filtered brick capacities at maximum SOC using SOH retention test conditions; raw 2047 = signal not available (SNA)";
CM_ SG_ 946 BMS_prevUserFacingSohEnergy "The last soh energy stored in NVM for rate limiting purposes; raw 2047 = signal not available (SNA)";
CM_ SG_ 946 BMS_stateOfHealthMinCac "Reports the minimum Calculated Amp-hour Capacity (CAC) by aged Open Circuit Voltage (OCV) raw values across bricks that could be used in State of Health (SOH) calculations.; raw 8191 = signal not available (SNA)";
CM_ SG_ 946 BMS_lifeModelStorageLossPackAge "High-voltage battery management system: life model storage loss pack age; raw 16383 = signal not available (SNA)";
CM_ SG_ 946 BMS_lifeModelThroughputCycleCoun "High-voltage battery management system: life model throughput cycle count; raw 4095 = signal not available (SNA)";
CM_ SG_ 946 BMS_lifeModelThroughputDcrCycleC "High-voltage battery management system: life model throughput dcr cycle count; raw 4095 = signal not available (SNA)";
CM_ SG_ 946 BMS_energyWalkCounter "High-voltage battery management system: energy walk counter";
CM_ SG_ 946 BMS_energyWalkTimeoutCounter "High-voltage battery management system: energy walk timeout counter";
CM_ SG_ 946 BMS_dynamicCcvEnabled "High-voltage battery management system: dynamic ccv enabled";
CM_ SG_ 946 BMS_chargeTargetLookupSoc "High-voltage battery management system: charge target lookup soc";
CM_ SG_ 946 BMS_stateOfHealth "Most recent battery capacity estimate, from a successful SOH test in %; raw 1023 = signal not available (SNA)";
CM_ BO_ 914 "High-voltage battery management system message: pack config";
CM_ SG_ 914 BMS_packConfigMultiplexer "High-voltage battery management system: pack config multiplexer";
CM_ SG_ 914 BMS_reservedConfig_0 "High-voltage battery management system: reserved config 0";
CM_ SG_ 914 BMS_moduleType "High-voltage battery management system: module type";
CM_ SG_ 914 BMS_thermalPackType "High-voltage battery management system: thermal pack type";
CM_ SG_ 914 BMS_packMass "High-voltage battery management system: pack mass";
CM_ SG_ 914 BMS_platformMaxBusVoltage "High-voltage battery management system: platform max bus voltage";
CM_ SG_ 914 BMS_standbySupplyContinuousPower "High-voltage battery management system: standby supply continuous power limit";
CM_ BO_ 594 "High-voltage battery management system message: power available";
CM_ SG_ 594 BMS_maxRegenPower "Calculated max regen power";
CM_ SG_ 594 BMS_maxDischargePower "Calculated max discharge power possible based on max discharge current and sum of loaded voltages";
CM_ SG_ 594 BMS_maxStationaryHeatPower "Maximum heating power the DI can produce when in stationary heating mode";
CM_ SG_ 594 BMS_powerLimitsState "High-voltage battery management system: power limits state";
CM_ SG_ 594 BMS_notEnoughPowerForHeatPump "Flag indicating the min pack power is lower than specified threshold to support heating with the heat pump";
CM_ SG_ 594 BMS_instantChargePowerCapability "Indicates the instantaneous charge power capability of the high voltage battery.; raw 65535 = signal not available (SNA)";
CM_ BO_ 674 "High-voltage battery management system message: ripple request";
CM_ SG_ 674 BMS_acRippleCurrentAmplitudeLimi "Transmits the Battery Management System (BMS) AC ripple current amplitude limit to the Electric Vehicle Supply Equipment (EVSE).";
CM_ SG_ 674 BMS_acRippleMaxVoltageLimit "Reports the maximum voltage limit when the Electric Vehicle Supply Equipment (EVSE) is performing the AC ripple.";
CM_ SG_ 674 BMS_acRippleMinVoltageLimit "Reports the minimum voltage limit when the Electric Vehicle Supply Equipment (EVSE) is performing the AC ripple.";
CM_ SG_ 674 BMS_acRippleFrequencyRequest "Transmits the Battery Management System (BMS) AC ripple frequency request to the Electric Vehicle Supply Equipment (EVSE).; raw 63 = signal not available (SNA)";
CM_ SG_ 674 BMS_acRippleCurrentAmplitudeRequ "Transmits the Battery Management System (BMS) AC ripple current amplitude request to the Electric Vehicle Supply Equipment (EVSE).";
CM_ SG_ 674 BMS_acRippleRequest "High-voltage battery management system: ac ripple request";
CM_ BO_ 658 "High-voltage battery management system message: soc status";
CM_ SG_ 658 BMS_socMin "BMS State Of Charge (SOC). This is the minimum brick SOC.";
CM_ SG_ 658 BMS_socUI "BMS State Of Energy (SOE) for the UI. This is ideal discharge energy from present state / ideal discharge energy from full.";
CM_ SG_ 658 BMS_socMax "BMS State Of Charge (SOC). This is the maximum brick SOC.";
CM_ SG_ 658 BMS_socAvg "BMS State Of Charge (SOC). This is the average of all the brick SOCs";
CM_ SG_ 658 BMS_beginningOfLifePackEnergy "High-voltage battery management system: beginning of life pack energy; raw 1023 = signal not available (SNA)";
CM_ SG_ 658 BMS_battTempPct "High-voltage battery management system: batt temp pct; raw 255 = signal not available (SNA)";
CM_ SG_ 658 BMS_userChargeCurrentLimitMode "BMS' user-facing reason for charge being either limited or not limited";
CM_ BO_ 1170 "High-voltage battery management system message: state of health";
CM_ SG_ 1170 BMS_sohEnergyPercent "Estimate of battery SOH Energy % based on the most accurate capacity estimates the BMS has available; raw 1023 = signal not available (SNA)";
CM_ SG_ 1170 BMS_userFacingSohTestState "High-voltage battery management system: user facing soh test state";
CM_ SG_ 1170 BMS_userFacingSohTestEndMode "High-voltage battery management system: user facing soh test end mode";
CM_ SG_ 1170 BMS_timeSinceSohUpdate "Days since last successful SOH test; raw 4095 = signal not available (SNA)";
CM_ SG_ 1170 BMS_sohTestCycleFlag "Flag that is True from the start of an SOH test until it ends and all relevant signals have been logged";
CM_ SG_ 1170 BMS_sohTestIsBlocked "High-voltage battery management system: soh test is blocked";
CM_ SG_ 1170 BMS_calibratedSohAvailable "SOH Energy is based on valid results from the SOH capacity test";
CM_ SG_ 1170 BMS_requiredEvsePowerForSoh "High-voltage battery management system: required evse power for soh; raw 255 = signal not available (SNA)";
CM_ SG_ 1170 BMS_distanceSinceSohUpdate "Distance since the last State of Health update in km; raw 65535 = signal not available (SNA)";
CM_ BO_ 530 "High-voltage battery management system message: status";
CM_ SG_ 530 BMS_hvacPowerRequest "High-voltage battery management system: hvac power request";
CM_ SG_ 530 BMS_notEnoughPowerForDrive "Flag indicating the min pack power is lower than specified threshold to support drive";
CM_ SG_ 530 BMS_notEnoughPowerForSupport "Flag indicating if the system can support a new request for 12V battery support";
CM_ SG_ 530 BMS_preconditionAllowed "High-voltage battery management system: precondition allowed";
CM_ SG_ 530 BMS_updateAllowed "High-voltage battery management system: update allowed";
CM_ SG_ 530 BMS_activeHeatingWorthwhile "Determination by the Battery Management System (BMS) if active heating is worthwhile";
CM_ SG_ 530 BMS_cpMiaOnHvs "Flag indicating that BMS is no longer receiving comms from CP on HVS bus";
CM_ SG_ 530 BMS_pcsPwmEnabled "Reports the state of the PCS_PWM_ENABLE input on the HVBMS, which is derived from the P1-12-DCDC-ENABLE input, which comes from VCFRONT";
CM_ SG_ 530 BMS_contactorState "BMS Contactor Status; raw 0 = signal not available (SNA)";
CM_ SG_ 530 BMS_userChargeStatus "BMS charge status for UI display. Renamed from BMS_uiChargeStatus";
CM_ SG_ 530 BMS_chargeRequest "Indicates charge is available and charge is desired";
CM_ SG_ 530 BMS_state "BMS operating state.; raw 9 = signal not available (SNA)";
CM_ SG_ 530 BMS_diLimpRequest "BMS request to DI to enter limp mode";
CM_ SG_ 530 BMS_okToShipByAir "High-voltage battery management system: ok to ship by air";
CM_ SG_ 530 BMS_okToShipByLand "High-voltage battery management system: ok to ship by land";
CM_ SG_ 530 BMS_chgPowerAvailable "BMS available charge power; raw 4095 = signal not available (SNA)";
CM_ SG_ 530 BMS_chargeRetryCount "Number of retries remaining to enable charge";
CM_ SG_ 530 BMS_conditioningRequest "BMS request to enable conditioning so it can attempt FEIM recovery";
CM_ SG_ 530 BMS_smStateRequest "BMS high level state request; raw 9 = signal not available (SNA)";
CM_ SG_ 530 BMS_hvState "BMS high voltage state";
CM_ BO_ 786 "High-voltage battery management system message: thermal status";
CM_ SG_ 786 BMS_powerDissipation "High-voltage battery management system: power dissipation";
CM_ SG_ 786 BMS_flowRequest "Requested coolant flow rate in liters per minute (LPM) from the Battery Management System (BMS) to the thermal module";
CM_ SG_ 786 BMS_inletActiveCoolTargetT "Calculated active cooling temperature target at the inlet";
CM_ SG_ 786 BMS_inletPassiveTargetT "Calculated passive temperature target at the inlet";
CM_ SG_ 786 BMS_inletActiveHeatTargetT "Calculated active heating temperature target at the inlet";
CM_ SG_ 786 BMS_minPackTemperature "Minimum pack temperature for consumption by external entities";
CM_ SG_ 786 BMS_maxPackTemperature "Maximum pack temperature for consumption by external entities";
CM_ SG_ 786 BMS_pcsNoFlowRequest "High-voltage battery management system: pcs no flow request";
CM_ SG_ 786 BMS_noFlowRequest "High-voltage battery management system: no flow request";
CM_ BO_ 754 "High-voltage battery management system message: veh nm";
CM_ SG_ 754 BMS_nmGoingToSleep "High-voltage battery management system: nm going to sleep";
CM_ SG_ 754 BMS_nmWakeUpBus "High-voltage battery management system: nm wake up bus";
CM_ SG_ 754 BMS_hvsBusAsleep "HVS bus reported as off";
CM_ SG_ 754 BMS_nmKeepAwakeReason "BMS' determined reason to keep CAN awake; raw 0 = signal not available (SNA)";
CM_ SG_ 754 BMS_nmWakeUpReason "BMS' determined reason to wake up CAN";
CM_ BO_ 810 "High-voltage battery management system message: vehicle notifications";
CM_ SG_ 810 BMS_thermalEventSuspected "Indicates the Battery Management System (BMS) has detected conditions that reflect a possible battery thermal event";
CM_ SG_ 810 BMS_vehicleNotificationsCounter "High-voltage battery management system: vehicle notifications counter";
CM_ SG_ 810 BMS_isolationResistance "Resistance between HV bus and chassis.; raw 1023 = signal not available (SNA)";
CM_ SG_ 810 BMS_vehicleNotificationsChecksum "High-voltage battery management system: vehicle notifications checksum";
CM_ BO_ 796 "Charge cable controller message: chg status";
CM_ SG_ 796 CC_currentLimit "Maximum allowable AC current the wall connector is willing to provide; raw 255 = signal not available (SNA)";
CM_ SG_ 796 CC_pilotState "State of pilot signal reported by the wall connector; raw 3 = signal not available (SNA)";
CM_ SG_ 796 CC_numPhases "Number of AC phases expected by wall connector; raw 0 = signal not available (SNA)";
CM_ SG_ 796 CC_line1Voltage "RMS voltage on L1 terminal of wall connector; raw 511 = signal not available (SNA)";
CM_ SG_ 796 CC_gridGrounding "Grouding scheme expected by the wall connector; raw 2 = signal not available (SNA)";
CM_ SG_ 796 CC_deltaTransformer "Grid configuration expected by the wall connector";
CM_ SG_ 796 CC_numVehCharging "Number of vehicles charging in wall connector load sharing group";
CM_ SG_ 796 CC_line2Voltage "RMS voltage on L2 terminal of wall connector; raw 511 = signal not available (SNA)";
CM_ SG_ 796 CC_line3Voltage "RMS voltage on L3 terminal of wall connector; raw 511 = signal not available (SNA)";
CM_ SG_ 796 CC_groundResistance "Charge cable controller: ground resistance; raw 4095 = signal not available (SNA)";
CM_ BO_ 797 "Charge cable controller message: chg status2";
CM_ SG_ 797 CC_chgStatus2Index "Charge cable controller: chg status2 index";
CM_ SG_ 797 CC_buttonState "Charge cable controller: button state";
CM_ BO_ 812 "Charge cable controller message: log data";
CM_ SG_ 812 CC_logIndex "Charge cable controller: log index";
CM_ SG_ 812 CC_activeConnectorID "Site identifier of active charge connector";
CM_ SG_ 812 CC_temperature1 "Charge cable vehicle connector temperature";
CM_ SG_ 812 CC_temperature2 "Charge cable vehicle connector temperature";
CM_ SG_ 812 CC_temperature3 "Charge cable vehicle connector temperature";
CM_ SG_ 812 CC_contactor1Closed "State of contactor 1 in wall connector";
CM_ SG_ 812 CC_contactor2Closed "State of contactor 1 in wall connector";
CM_ SG_ 812 CC_temperature4 "Charge cable vehicle connector temperature";
CM_ SG_ 812 CC_conn1Current "AC current on connector 1 in wall charger load sharing group; raw 255 = signal not available (SNA)";
CM_ SG_ 812 CC_conn2Current "AC current on connector 2 in wall charger load sharing group; raw 255 = signal not available (SNA)";
CM_ SG_ 812 CC_conn3Current "AC current on connector 3 in wall charger load sharing group; raw 255 = signal not available (SNA)";
CM_ SG_ 812 CC_conn4Current "AC current on connector 4 in wall charger load sharing group; raw 255 = signal not available (SNA)";
CM_ SG_ 812 CC_lifetimei2t "Charge cable controller: lifetimei2t";
CM_ SG_ 812 CC_lifetimeCtrCycles "Charge cable controller: lifetime ctr cycles";
CM_ SG_ 812 CC_lifetimeCtrCyclesLoaded "Charge cable controller: lifetime ctr cycles loaded";
CM_ SG_ 812 CC_lifetimeAlertCount "Charge cable controller: lifetime alert count";
CM_ SG_ 812 CC_lifetimeThermalFoldbacks "Charge cable controller: lifetime thermal foldbacks";
CM_ SG_ 812 CC_lifetimeAvgStartupTemp "Charge cable controller: lifetime avg startup temp";
CM_ BO_ 870 "CMPD ECU message: info";
CM_ SG_ 870 CMPD_infoIndex "CMPD ECU: info index";
CM_ SG_ 870 CMPD_infoBuildType "CMPD ECU: info build type";
CM_ SG_ 870 CMPD_infoBuildConfigId "CMPD ECU: info build config id";
CM_ SG_ 870 CMPD_infoHardwareId "CMPD ECU: info hardware id";
CM_ SG_ 870 CMPD_infoComponentId "CMPD ECU: info component id";
CM_ SG_ 870 CMPD_infoPcbaId "CMPD ECU: info pcba id";
CM_ SG_ 870 CMPD_infoAssemblyId "CMPD ECU: info assembly id; raw 255 = signal not available (SNA)";
CM_ SG_ 870 CMPD_infoUsageId "CMPD ECU: info usage id";
CM_ SG_ 870 CMPD_infoSubUsageId "CMPD ECU: info sub usage id";
CM_ BO_ 679 "CMPD ECU message: state";
CM_ SG_ 679 CMPD_speedRPM "Reports compressor speed.";
CM_ SG_ 679 CMPD_speedDuty "Reports compressor speed duty cycle percentage.";
CM_ SG_ 679 CMPD_inputHVPower "Measures compressor input high voltage (HV) power consumption.";
CM_ SG_ 679 CMPD_inputHVCurrent "Measures compressor input high voltage (HV) current draw.";
CM_ SG_ 679 CMPD_inputHVVoltage "Measures compressor input high voltage (HV) level.";
CM_ SG_ 679 CMPD_2ShuntModeActive "Indicates the compressor motor control is running using only two current shunt resistors instead of three.";
CM_ SG_ 679 CMPD_powerLimitActive "Indicates the compressor power limit is active.";
CM_ SG_ 679 CMPD_state "Reports compressor operational state.; raw 15 = signal not available (SNA)";
CM_ SG_ 679 CMPD_wasteHeatState "Reports compressor waste heat recovery state.";
CM_ SG_ 679 CMPD_powerLimitTooLowToStart "Indicates the compressor power limit is too low to start the compressor.";
CM_ SG_ 679 CMPD_ready "Indicates the compressor is ready to start.";
CM_ BO_ 867 "A/C compressor message: info";
CM_ SG_ 867 CMP_infoIndex "A/C compressor: info index";
CM_ SG_ 867 CMP_infoBuildType "A/C compressor: info build type";
CM_ SG_ 867 CMP_infoBuildConfigId "A/C compressor: info build config id";
CM_ SG_ 867 CMP_infoHardwareId "A/C compressor: info hardware id";
CM_ SG_ 867 CMP_infoComponentId "A/C compressor: info component id";
CM_ SG_ 867 CMP_infoPcbaId "A/C compressor: info pcba id";
CM_ SG_ 867 CMP_infoAssemblyId "A/C compressor: info assembly id; raw 255 = signal not available (SNA)";
CM_ SG_ 867 CMP_infoUsageId "A/C compressor: info usage id";
CM_ SG_ 867 CMP_infoSubUsageId "A/C compressor: info sub usage id";
CM_ SG_ 867 CMP_infoPlatformType "A/C compressor: info platform type";
CM_ SG_ 867 CMP_infoAppCrc "A/C compressor: info app crc";
CM_ SG_ 867 CMP_infoBootUdsProtoVersion "A/C compressor: info boot uds proto version";
CM_ SG_ 867 CMP_infoBootCrc "A/C compressor: info boot crc";
CM_ BO_ 669 "Charge port controller message: dc charge status";
CM_ SG_ 669 CP_evseOutputDcCurrent "The DC EVSE's measured output current";
CM_ SG_ 669 CP_evseOutputDcVoltage "The DC EVSE's measured output voltage";
CM_ SG_ 669 CP_evseOutputDcCurrentStale "Indicates whether the data in CP_evseOutputDcCurrent has not been updated with new info from the DC EVSE recently";
CM_ BO_ 541 "Charge port controller message: evse status";
CM_ SG_ 541 CP_evseAccept "State of pilot EVSE accept state";
CM_ SG_ 541 CP_evseRequest "Request to close AC EVSE relays, used when digital communications have been established";
CM_ SG_ 541 CP_proximity "Sensed state of proximity for all inlets; raw 0 = signal not available (SNA)";
CM_ SG_ 541 CP_pilot "State of EVSE pilot signal sensed by the charge port; raw 7 = signal not available (SNA)";
CM_ SG_ 541 CP_digitalCommsEstablished "Indicates whether digital communications have been established with an EVSE";
CM_ SG_ 541 CP_pilotCurrent "Line current limit detected from pilot signal";
CM_ SG_ 541 CP_cableType "Type of charge cable detected; raw 4 = signal not available (SNA)";
CM_ SG_ 541 CP_iecPilotState "State of the control pilot as defined in IEC-61851-1; raw 9 = signal not available (SNA)";
CM_ SG_ 541 CP_plcSupported "Indicates whether PLC hardware is populated for CCS charging support";
CM_ SG_ 541 CP_cableCurrentLimit "Charge port controller: cable current limit";
CM_ SG_ 541 CP_teslaSwcanState "Charge port controller: tesla swcan state";
CM_ SG_ 541 CP_evseChargeType_UI "Reports the type of Electric Vehicle Supply Equipment (EVSE) connected.";
CM_ SG_ 541 CP_gbState "State of GB DC charging";
CM_ SG_ 541 CP_gbdcStopChargeReason "Reason for stopping GB DC charging";
CM_ SG_ 541 CP_gbdcFailureReason "Reason for failure of GB DC charging";
CM_ SG_ 541 CP_gbdcChargeAttempts "Number of GB DC charging retries used";
CM_ SG_ 541 CP_acChargeState "Charge port controller: ac charge state";
CM_ SG_ 541 CP_teslaDcState "Reports the state of the Tesla direct current (DC) state machine.";
CM_ BO_ 1342 "Charge port controller message: info";
CM_ SG_ 1342 CP_infoIndex "Charge port controller: info index";
CM_ SG_ 1342 CP_buildType "Charge port controller: build type";
CM_ SG_ 1342 CP_buildConfigId "Charge port controller: build config id";
CM_ SG_ 1342 CP_hardwareId "Charge port controller: hardware id";
CM_ SG_ 1342 CP_componentId "Charge port controller: component id";
CM_ SG_ 1342 CP_pcbaId "Charge port controller: pcba id";
CM_ SG_ 1342 CP_assemblyId "Charge port controller: assembly id";
CM_ SG_ 1342 CP_usageId "Charge port controller: usage id";
CM_ SG_ 1342 CP_subUsageId "Charge port controller: sub usage id";
CM_ SG_ 1342 CP_platformType "Charge port controller: platform type";
CM_ SG_ 1342 CP_appCrc "Charge port controller: app crc";
CM_ SG_ 1342 CP_appGitHash "Charge port controller: app git hash";
CM_ SG_ 1342 CP_bootGitHash "Charge port controller: boot git hash";
CM_ SG_ 1342 CP_bootUdsProtoVersion "Charge port controller: boot uds proto version";
CM_ SG_ 1342 CP_bootCrc "Charge port controller: boot crc";
CM_ BO_ 1885 "Charge port controller message: logging fast";
CM_ SG_ 1885 CP_loggingFastSelect "Charge port controller: logging fast select";
CM_ SG_ 1885 CP_inductiveSensor_raw "Charge port controller: inductive sensor raw";
CM_ SG_ 1885 CP_doorOpenActuationTime "Charge port controller: door open actuation time";
CM_ SG_ 1885 CP_doorCloseActuationTime "Charge port controller: door close actuation time";
CM_ SG_ 1885 CP_chargeCableSecured "Indicates whether a charge cable is secured in any inlet";
CM_ SG_ 1885 CP_chargeCablePresent "Indicates whether a charge cable is present in any inlet";
CM_ SG_ 1885 CP_latchCheckAvailable "Charge port controller: latch check available";
CM_ SG_ 1885 CP_UHF_controlState "Control state of UHF receiver";
CM_ SG_ 1885 CP_proximityV "Charge port controller: proximity v";
CM_ SG_ 1885 CP_proximityV_GBCC1 "Sensed voltage of GB DC inlet CC1 connection";
CM_ SG_ 1885 CP_proximityV_GBCC2 "Sensed voltage of GB DC inlet CC2 connection";
CM_ SG_ 1885 CP_doorPot "Position of the charge port door potentiometer";
CM_ SG_ 1885 CP_doorOpenRequest "Door open request trigger";
CM_ SG_ 1885 CP_doorOpenEndOfDriveReason "Reason why the door stopped moving in the open direction";
CM_ SG_ 1885 CP_coverClosed "Charge port controller: cover closed";
CM_ SG_ 1885 CP_doorCloseEndOfDriveReason "Reason why the door stopped moving in the closing direction";
CM_ SG_ 1885 CP_doorCloseRequest "Door close request trigger";
CM_ SG_ 1885 CP_latchDisengagingTime "Charge port controller: latch disengaging time";
CM_ SG_ 1885 CP_latchEngagingTime "Charge port controller: latch engaging time";
CM_ SG_ 1885 CP_latchDisengagingStopReason "Reason why the latch stopped moving in the engaged direction";
CM_ SG_ 1885 CP_latchEngagingStopReason "Reason why the latch stopped moving in the engaged direction";
CM_ SG_ 1885 CP_doorIdDetectionState "Charge port controller: door id detection state; raw 0 = signal not available (SNA)";
CM_ SG_ 1885 CP_doorIdDetectedBin "Charge port controller: door id detected bin";
CM_ BO_ 989 "Charge port controller message: logging slow";
CM_ SG_ 989 CP_loggingSlowSelect "Charge port controller: logging slow select";
CM_ SG_ 989 CP_UHF_chipState "Charge port controller: UHF chip state";
CM_ SG_ 989 CP_UHF_rssi "Signal strength of received UHF signal";
CM_ SG_ 989 CP_UHF_rxOverflow "Charge port controller: UHF rx overflow";
CM_ SG_ 989 CP_UHF_rxNumBytes "Charge port controller: UHF rx num bytes";
CM_ SG_ 989 CP_UHF_selfTestRssi "Signal strength of received self-test UHF signal";
CM_ SG_ 989 CP_latchI "Charge port controller: latch i";
CM_ SG_ 989 CP_inlet1HarnessIdState "State of the CP's inlet 1 harness pedigree; raw 0 = signal not available (SNA)";
CM_ SG_ 989 CP_inlet1HarnessIdValue "Pedigree of the CP's inlet 1 harness";
CM_ SG_ 989 CP_inlet2HarnessIdState "State of the CP's inlet 2 harness pedigree; raw 0 = signal not available (SNA)";
CM_ SG_ 989 CP_inlet2HarnessIdValue "Pedigree of the CP's inlet 2 harness";
CM_ SG_ 989 CP_inletHeaterState "Reports the present state of the inlet heater.";
CM_ SG_ 989 CP_inletHeaterDuty "Inlet heater PWM duty cycle";
CM_ SG_ 989 CP_nvm_dataValid "Charge port controller: nvm data valid";
CM_ SG_ 989 CP_nvm_doorOpenCycles "Charge port controller: nvm door open cycles";
CM_ SG_ 989 CP_nvm_doorCloseCycles "Charge port controller: nvm door close cycles";
CM_ SG_ 989 CP_nvm_doorOpen "Charge port controller: nvm door open";
CM_ SG_ 989 CP_nvm_doorPresent "Charge port controller: nvm door present";
CM_ SG_ 989 CP_nvm_doorPresentValid "Charge port controller: nvm door present valid";
CM_ SG_ 989 CP_nvm_badPilotDiodeDetected "Charge port controller: nvm bad pilot diode detected";
CM_ SG_ 989 CP_nvm_pilotDiodeFaultCount "Charge port controller: nvm pilot diode fault count";
CM_ SG_ 989 CP_doorOpenLimiterMaxCount "Charge port controller: door open limiter max count";
CM_ SG_ 989 CP_doorOpenLimiterMaxRequestType "Charge port controller: door open limiter max request type";
CM_ SG_ 989 CP_doorCloseLimiterMaxCount "Charge port controller: door close limiter max count";
CM_ SG_ 989 CP_doorCloseLimiterMaxRequestTyp "Charge port controller: door close limiter max request type";
CM_ BO_ 605 "Charge port controller message: status";
CM_ SG_ 605 CP_type "Charge port controller: type";
CM_ SG_ 605 CP_insertEnableLine "Sensed state of the charge port latch drive enable hardline";
CM_ SG_ 605 CP_latchState "Sensed state of the charge port latch; raw 0 = signal not available (SNA)";
CM_ SG_ 605 CP_permanentPowerRequest "Charge port controller: permanent power request";
CM_ SG_ 605 CP_chargeDoorOpen "Indicates whether the charge port door is open based on all door sensors";
CM_ SG_ 605 CP_doorControlState "State of the charge port door controller";
CM_ SG_ 605 CP_doorButtonPressed "Indicates whether the charge door button has been pressed";
CM_ SG_ 605 CP_swcanRelayClosed "Indicates whether the single wire CAN relay is closed";
CM_ SG_ 605 CP_inhibitOta "Reports the charge port's request to prevent scheduled Over-The-Air (OTA) updates during critical charging operations.";
CM_ SG_ 605 CP_chargeCableState "Charge cable connection state; raw 0 = signal not available (SNA)";
CM_ SG_ 605 CP_latchControlState "Control state of the charge port latch";
CM_ SG_ 605 CP_ledColor "Color of the charge port LED";
CM_ SG_ 605 CP_UHF_handleFound "Indicates whether a charge handle has been found with UHF";
CM_ SG_ 605 CP_faultLineSensed "A signal indicating the set / cleared state of the CP-HVP bi-directional fault line, as sensed by the CP";
CM_ SG_ 605 CP_doorPresenceState "State of door as detected by the presence sensor";
CM_ SG_ 605 CP_inductiveSensorState "State of inductive door sensor";
CM_ SG_ 605 CP_chargeDoorOpenUI "Indicates whether the charge port door is open based only on the door poteniometer";
CM_ SG_ 605 CP_vehicleUnlockRequest "Request to unlock the vehicle";
CM_ SG_ 605 CP_coldWeatherMode "Indicates whether the charge port is in cold weather mode";
CM_ SG_ 605 CP_latchEngaged "Charge port controller: latch engaged";
CM_ SG_ 605 CP_inletHeaterUiState "Reports to the User Interface (UI) the state of the inlet heater.";
CM_ BO_ 893 "Charge port controller message: thermal status";
CM_ SG_ 893 CP_thermalStatusSelect "Charge port controller: thermal status select";
CM_ SG_ 893 CP_pinTemperature1 "Sensed temperature of the charge port inlet pins";
CM_ SG_ 893 CP_pinTemperature2 "Sensed temperature of the charge port inlet pins";
CM_ SG_ 893 CP_pinTemperature3 "Sensed temperature of the charge port inlet pins";
CM_ BO_ 1001 "Driver assistance computer message: body controls";
CM_ SG_ 1001 DAS_headlightRequest "The DAS request to the body controls ecu to turn on headlights.";
CM_ SG_ 1001 DAS_hazardLightRequest "The command from DAS to body controls to turn on the hazard lights.; raw 3 = signal not available (SNA)";
CM_ SG_ 1001 DAS_wiperSpeed "The auto wiper algorithm speed request to the body controller.";
CM_ SG_ 1001 DAS_turnIndicatorRequest "Reports Driver Assistance System (DAS) request to body controls to turn on/off the left or right turn indicator.";
CM_ SG_ 1001 DAS_highLowBeamDecision "The output of the automatic high beam algorithm, to turn the highbeams on or off.; raw 3 = signal not available (SNA)";
CM_ SG_ 1001 DAS_heaterRequest "The DAS request to the body controller to turn on the front glass heater in front of the triple camera.; raw 0 = signal not available (SNA)";
CM_ SG_ 1001 DAS_highLowBeamOffReason "The reason why automatic high beams are surpressed.; raw 5 = signal not available (SNA)";
CM_ SG_ 1001 DAS_forwardCamHeaterDutyCycle "Supplies the requested duty cycle of the front windshield camera heater";
CM_ SG_ 1001 DAS_dynamicBrakeLightRequest "Indicates if the dynamic brake light alogirthm is requesting pulsing brake lights.";
CM_ SG_ 1001 DAS_radarHeaterRequest "Reports the request from Driver Assistance System (DAS) to body controls to turn on heater to clear out fascia in front of the radar.";
CM_ SG_ 1001 DAS_ahlbOverride "Indicates if body controller should override UI switch and stalk state to allow auto high beam functionality";
CM_ SG_ 1001 DAS_mirrorFoldRequest "DAS request to fold or present mirrors.; raw 3 = signal not available (SNA)";
CM_ SG_ 1001 DAS_wiperWashRequest "Autowiper requests that the windshield be washed";
CM_ SG_ 1001 DAS_ulcConfirmationRequestActive "Driver assistance computer: ulc confirmation request active";
CM_ SG_ 1001 DAS_overrideWiperSetting "Autopilot wants to override the user's wiper setting to enable auto-wiper";
CM_ SG_ 1001 DAS_autoWiperState "DAS auto wiper internal state; raw 5 = signal not available (SNA)";
CM_ SG_ 1001 DAS_turnIndicatorRequestReason "Reports the reason that Driver Assistance System (DAS) is requesting a change to the turn indicator state from body controls.";
CM_ SG_ 1001 DAS_forwardRadarPowerRequest "Driver assistance computer: forward radar power request";
CM_ SG_ 1001 DAS_driverDomeLightRequest "DAS requests that driver side dome light be illuminated";
CM_ SG_ 1001 DAS_drivePowerStateRequest "Reports DAS request for vehicle power state Drive.";
CM_ SG_ 1001 DAS_enableIcrDataCollection "Driver assistance computer: enable icr data collection";
CM_ SG_ 1001 DAS_rPillarCamHeaterDutyCycle "Supplies the requested duty cycle of the right pillar camera heater";
CM_ SG_ 1001 DAS_adaptiveHighBeamIsFaulted "Indicates malfunctioning or unavailable input to the Adaptive High Beam system.";
CM_ SG_ 1001 DAS_restrictDoorReleaseLeft "Reports requests to inhibit left doors from being released.";
CM_ SG_ 1001 DAS_restrictDoorReleaseRight "Reports requests to inhibit right doors from being released.";
CM_ SG_ 1001 DAS_bodyControlsCounter "Driver assistance computer: body controls counter";
CM_ SG_ 1001 DAS_bodyControlsChecksum "Driver assistance computer: body controls checksum";
CM_ BO_ 634 "Front drive inverter message: hv status";
CM_ SG_ 634 DIF_hvStatusChecksum "Front drive inverter: hv status checksum";
CM_ SG_ 634 DIF_hvStatusCounter "Front drive inverter: hv status counter";
CM_ SG_ 634 DIF_hvilCurrent "HVIL Current";
CM_ SG_ 634 DIF_hvilCmVoltage "HVIL Common Mode Voltage";
CM_ SG_ 634 DIF_hvilStatus "Aggregated hardware and measured HVIL unit status; raw 3 = signal not available (SNA)";
CM_ SG_ 634 DIF_hvilSupplyState "Front drive inverter: hvil supply state";
CM_ SG_ 634 DIF_activeDischargeCtrl "Front drive inverter: active discharge ctrl";
CM_ SG_ 634 DIF_activeDischargeStatus "Active discharge status from HVIL_FAULT signal.";
CM_ SG_ 634 DIF_vBat "Reports the battery voltage measured by the Drive Inverter's local Analog to Digital Converter (ADC).";
CM_ SG_ 634 DIF_vBatQF "Front drive inverter: v bat QF";
CM_ SG_ 634 DIF_powerStageSafeState "Front drive inverter: power stage safe state";
CM_ SG_ 634 DIF_fluxState "Front drive inverter: flux state";
CM_ SG_ 634 DIF_vBusDiag "Front drive inverter: v bus diag";
CM_ SG_ 634 DIF_gateDriveState "Front drive inverter: gate drive state";
CM_ BO_ 741 "Front drive inverter message: power";
CM_ SG_ 741 DIF_elecPower "Front drive inverter: elec power; raw 1024 = signal not available (SNA)";
CM_ SG_ 741 DIF_heatPowerOptimal "Front drive inverter: heat power optimal";
CM_ SG_ 741 DIF_heatPowerMax "Drive Inverter maximum heat power capability";
CM_ SG_ 741 DIF_heatPowerActual "Drive Inverter heat power";
CM_ SG_ 741 DIF_excessHeatCommand "Drive Inverter excess heat command";
CM_ SG_ 741 DIF_drivePowerMax "Front drive inverter: drive power max; raw 511 = signal not available (SNA)";
CM_ BO_ 886 "Front drive inverter message: temperature";
CM_ SG_ 886 DIF_tempIndex "Front drive inverter: temp index";
CM_ SG_ 886 DIF_inverterTQF "Detects the Drive Inverter (DI) outlet temperature qualifier.";
CM_ SG_ 886 DIF_pcbT "Front drive inverter: pcb t; raw 0 = signal not available (SNA)";
CM_ SG_ 886 DIF_inverterT "Drive Inverter measured outlet temperature";
CM_ SG_ 886 DIF_statorT "Drive Inverter measured stator temperature.; raw 0 = signal not available (SNA)";
CM_ SG_ 886 DIF_dcCapT "Front drive inverter: dc cap t; raw 0 = signal not available (SNA)";
CM_ SG_ 886 DIF_heatsinkT "Drive Inverter measured heatsink temperature; raw 0 = signal not available (SNA)";
CM_ SG_ 886 DIF_inverterTpct "Front drive inverter: inverter tpct";
CM_ SG_ 886 DIF_statorTpct "Front drive inverter: stator tpct";
CM_ SG_ 886 DIF_fluidInTemp "Inlet fluid temperature; raw 0 = signal not available (SNA)";
CM_ SG_ 886 DIF_normalFetBurnIn "Front drive inverter: normal fet burn in; raw 65535 = signal not available (SNA)";
CM_ SG_ 886 DIF_additionalFetBurnIn "Front drive inverter: additional fet burn in; raw 65535 = signal not available (SNA)";
CM_ SG_ 886 DIF_currentWeibullMiles "Front drive inverter: current weibull miles; raw 32767 = signal not available (SNA)";
CM_ SG_ 886 DIF_endOfServiceWeibullMiles "Front drive inverter: end of service weibull miles; raw 32767 = signal not available (SNA)";
CM_ SG_ 886 DIF_burnInDamageRatio "Front drive inverter: burn in damage ratio; raw 511 = signal not available (SNA)";
CM_ SG_ 886 DIF_inverterSensorEst "Front drive inverter: inverter sensor est";
CM_ SG_ 886 DIF_inverterHS1Est "Front drive inverter: inverter HS1 est";
CM_ SG_ 886 DIF_initialBurnInVehicleOdometer "Front drive inverter: initial burn in vehicle odometer; raw 4294967295 = signal not available (SNA)";
CM_ SG_ 886 DIF_inverterHS2Est "Front drive inverter: inverter HS2 est";
CM_ SG_ 886 DIF_inverterInletEst "Front drive inverter: inverter inlet est";
CM_ BO_ 1367 "Front drive inverter message: thermal control";
CM_ SG_ 1367 DIF_passiveInletTempReq "Front drive inverter: passive inlet temp req";
CM_ SG_ 1367 DIF_activeInletTempReq "Front drive inverter: active inlet temp req";
CM_ SG_ 1367 DIF_coolantFlowReq "Coolant flow requested";
CM_ SG_ 1367 DIF_oilFlowReq "Front drive inverter: oil flow req; raw 255 = signal not available (SNA)";
CM_ SG_ 1367 DIF_criticalFlowReq "Front drive inverter: critical flow req";
CM_ SG_ 1367 DIF_burnInStatus "Front drive inverter: burn in status";
CM_ BO_ 2005 "Rear drive inverter message: debug";
CM_ SG_ 2005 DIR_debugSelector "Rear drive inverter: debug selector";
CM_ SG_ 2005 DIR_phaseOutBusbarTemp "Rear drive inverter: phase out busbar temp; raw 0 = signal not available (SNA)";
CM_ SG_ 2005 DIR_phaseOutBusbarWeldTemp "Rear drive inverter: phase out busbar weld temp; raw 0 = signal not available (SNA)";
CM_ SG_ 2005 DIR_phaseOutLugTemp "Rear drive inverter: phase out lug temp; raw 0 = signal not available (SNA)";
CM_ SG_ 2005 DIR_dcLinkCapTemp "Rear drive inverter: dc link cap temp; raw 0 = signal not available (SNA)";
CM_ SG_ 2005 DIR_hvDcCableTemp "Rear drive inverter: hv dc cable temp; raw 0 = signal not available (SNA)";
CM_ SG_ 2005 DIR_negDcBusbarTemp "Rear drive inverter: neg dc busbar temp; raw 0 = signal not available (SNA)";
CM_ SG_ 2005 DIR_posDcBusbarTemp "Rear drive inverter: pos dc busbar temp; raw 0 = signal not available (SNA)";
CM_ SG_ 2005 DIR_statorEndWindingTemp "Rear drive inverter: stator end winding temp; raw 0 = signal not available (SNA)";
CM_ SG_ 2005 DIR_rotorMaxMagnetTemp "Reports the maximum temperature of the rotor magnet.; raw 0 = signal not available (SNA)";
CM_ SG_ 2005 DIR_lightSenseV "Rear drive inverter: light sense v";
CM_ SG_ 2005 DIR_pyroSenseV "Rear drive inverter: pyro sense v";
CM_ SG_ 2005 DIR_statorSlotWindingTemp "Rear drive inverter: stator slot winding temp; raw 0 = signal not available (SNA)";
CM_ SG_ 2005 DIR_intervalMaxHvBusV "Rear drive inverter: interval max hv bus v";
CM_ BO_ 633 "Rear drive inverter message: hv status";
CM_ SG_ 633 DIR_hvStatusChecksum "Rear drive inverter: hv status checksum";
CM_ SG_ 633 DIR_hvStatusCounter "Rear drive inverter: hv status counter";
CM_ SG_ 633 DIR_hvilCurrent "HVIL Current";
CM_ SG_ 633 DIR_hvilCmVoltage "HVIL Common Mode Voltage";
CM_ SG_ 633 DIR_hvilStatus "Aggregated hardware and measured HVIL unit status; raw 3 = signal not available (SNA)";
CM_ SG_ 633 DIR_hvilSupplyState "Rear drive inverter: hvil supply state";
CM_ SG_ 633 DIR_activeDischargeCtrl "Rear drive inverter: active discharge ctrl";
CM_ SG_ 633 DIR_activeDischargeStatus "Active discharge status from HVIL_FAULT signal.";
CM_ SG_ 633 DIR_vBat "Reports the battery voltage measured by the Drive Inverter's local Analog to Digital Converter (ADC).";
CM_ SG_ 633 DIR_vBatQF "Rear drive inverter: v bat QF";
CM_ SG_ 633 DIR_powerStageSafeState "Rear drive inverter: power stage safe state";
CM_ SG_ 633 DIR_fluxState "Rear drive inverter: flux state";
CM_ SG_ 633 DIR_vBusDiag "Rear drive inverter: v bus diag";
CM_ SG_ 633 DIR_gateDriveState "Rear drive inverter: gate drive state";
CM_ BO_ 821 "Rear drive inverter message: info";
CM_ SG_ 821 DIR_infoIndex "Rear drive inverter: info index";
CM_ SG_ 821 DIR_buildType "Rear drive inverter: build type";
CM_ SG_ 821 DIR_buildConfigurationId "Rear drive inverter: build configuration id";
CM_ SG_ 821 DIR_hardwareId "Rear drive inverter: hardware id";
CM_ SG_ 821 DIR_componentId "Rear drive inverter: component id";
CM_ SG_ 821 DIR_pcbaId "Rear drive inverter: pcba id";
CM_ SG_ 821 DIR_assemblyId "Rear drive inverter: assembly id";
CM_ SG_ 821 DIR_usageId "Rear drive inverter: usage id";
CM_ SG_ 821 DIR_subUsageId "Rear drive inverter: sub usage id";
CM_ SG_ 821 DIR_motorType "Rear drive inverter: motor type; raw 0 = signal not available (SNA)";
CM_ SG_ 821 DIR_siliconType "Rear drive inverter: silicon type";
CM_ SG_ 821 DIR_mechSafeStateType "Rear drive inverter: mech safe state type; raw 0 = signal not available (SNA)";
CM_ SG_ 821 DIR_applicationCrc "Rear drive inverter: application crc";
CM_ SG_ 821 DIR_oilPumpBuildType "Rear drive inverter: oil pump build type";
CM_ SG_ 821 DIR_oilPumpAppCrc "Rear drive inverter: oil pump app crc";
CM_ SG_ 821 DIR_FPGA_version "Rear drive inverter: FPGA version; raw 255 = signal not available (SNA)";
CM_ SG_ 821 DIR_bootGitHash "Rear drive inverter: boot git hash";
CM_ SG_ 821 DIR_infoBootLdUdsProtocolVersion "Rear drive inverter: info boot ld uds protocol version";
CM_ SG_ 821 DIR_bootloaderCrc "Rear drive inverter: bootloader crc";
CM_ SG_ 821 DIR_oilPumpPcbaId "Rear drive inverter: oil pump pcba id";
CM_ SG_ 821 DIR_oilPumpAssemblyId "Rear drive inverter: oil pump assembly id";
CM_ SG_ 821 DIR_oilPumpUsageId "Rear drive inverter: oil pump usage id";
CM_ SG_ 821 DIR_refRotorFlux "Rear drive inverter: ref rotor flux";
CM_ SG_ 821 DIR_refRotorOffset "Rear drive inverter: ref rotor offset; raw 2048 = signal not available (SNA)";
CM_ SG_ 821 DIR_speedWearTotal "Rear drive inverter: speed wear total; raw 255 = signal not available (SNA)";
CM_ SG_ 821 DIR_torqueWearTotal "Rear drive inverter: torque wear total; raw 255 = signal not available (SNA)";
CM_ BO_ 917 "Rear drive inverter message: oil pump";
CM_ SG_ 917 DIR_oilPumpState "Reports the state of the oil pump.; raw 7 = signal not available (SNA)";
CM_ SG_ 917 DIR_oilPumpFluidTQF "Rear drive inverter: oil pump fluid TQF";
CM_ SG_ 917 DIR_oilPumpLeadAngle "Rear drive inverter: oil pump lead angle";
CM_ SG_ 917 DIR_oilPumpFlowTarget "Detects oil pump flow target.; raw 255 = signal not available (SNA)";
CM_ SG_ 917 DIR_oilPumpFlowActual "Detects oil pump flow.; raw 255 = signal not available (SNA)";
CM_ SG_ 917 DIR_oilPumpFluidT "Detects oil pump fluid tester.; raw 255 = signal not available (SNA)";
CM_ SG_ 917 DIR_oilPumpPhaseCurrent "Rear drive inverter: oil pump phase current; raw 255 = signal not available (SNA)";
CM_ SG_ 917 DIR_oilPumpPressureEstimate "Oil pump pressure estimate.; raw 255 = signal not available (SNA)";
CM_ SG_ 917 DIR_oilPumpPressureExpected "Oil pump pressure expected.; raw 255 = signal not available (SNA)";
CM_ SG_ 917 DIR_oilPumpPressureResidual "Oil pressure error outside of allowed tolerance; raw 255 = signal not available (SNA)";
CM_ BO_ 614 "Rear drive inverter message: power";
CM_ SG_ 614 DIR_elecPower "Rear drive inverter: elec power; raw 1024 = signal not available (SNA)";
CM_ SG_ 614 DIR_heatPowerOptimal "Rear drive inverter: heat power optimal";
CM_ SG_ 614 DIR_heatPowerMax "Drive Inverter maximum heat power capability";
CM_ SG_ 614 DIR_heatPowerActual "Drive Inverter heat power";
CM_ SG_ 614 DIR_excessHeatCommand "Drive Inverter excess heat command";
CM_ SG_ 614 DIR_drivePowerMax "Rear drive inverter: drive power max; raw 511 = signal not available (SNA)";
CM_ BO_ 789 "Rear drive inverter message: temperature";
CM_ SG_ 789 DIR_tempIndex "Rear drive inverter: temp index";
CM_ SG_ 789 DIR_inverterTQF "Detects the Drive Inverter (DI) outlet temperature qualifier.";
CM_ SG_ 789 DIR_pcbT "Rear drive inverter: pcb t; raw 0 = signal not available (SNA)";
CM_ SG_ 789 DIR_inverterT "Drive Inverter measured outlet temperature";
CM_ SG_ 789 DIR_statorT "Drive Inverter measured stator temperature.; raw 0 = signal not available (SNA)";
CM_ SG_ 789 DIR_dcCapT "Rear drive inverter: dc cap t; raw 0 = signal not available (SNA)";
CM_ SG_ 789 DIR_heatsinkT "Drive Inverter measured heatsink temperature; raw 0 = signal not available (SNA)";
CM_ SG_ 789 DIR_inverterTpct "Rear drive inverter: inverter tpct";
CM_ SG_ 789 DIR_statorTpct "Rear drive inverter: stator tpct";
CM_ SG_ 789 DIR_fluidInTemp "Inlet fluid temperature; raw 0 = signal not available (SNA)";
CM_ SG_ 789 DIR_normalFetBurnIn "Rear drive inverter: normal fet burn in; raw 65535 = signal not available (SNA)";
CM_ SG_ 789 DIR_additionalFetBurnIn "Rear drive inverter: additional fet burn in; raw 65535 = signal not available (SNA)";
CM_ SG_ 789 DIR_currentWeibullMiles "Rear drive inverter: current weibull miles; raw 32767 = signal not available (SNA)";
CM_ SG_ 789 DIR_endOfServiceWeibullMiles "Rear drive inverter: end of service weibull miles; raw 32767 = signal not available (SNA)";
CM_ SG_ 789 DIR_burnInDamageRatio "Rear drive inverter: burn in damage ratio; raw 511 = signal not available (SNA)";
CM_ SG_ 789 DIR_inverterSensorEst "Rear drive inverter: inverter sensor est";
CM_ SG_ 789 DIR_inverterHS1Est "Rear drive inverter: inverter HS1 est";
CM_ SG_ 789 DIR_initialBurnInVehicleOdometer "Rear drive inverter: initial burn in vehicle odometer; raw 4294967295 = signal not available (SNA)";
CM_ SG_ 789 DIR_inverterHS2Est "Rear drive inverter: inverter HS2 est";
CM_ SG_ 789 DIR_inverterInletEst "Rear drive inverter: inverter inlet est";
CM_ BO_ 1495 "Rear drive inverter message: thermal control";
CM_ SG_ 1495 DIR_passiveInletTempReq "Rear drive inverter: passive inlet temp req";
CM_ SG_ 1495 DIR_activeInletTempReq "Rear drive inverter: active inlet temp req";
CM_ SG_ 1495 DIR_coolantFlowReq "Coolant flow requested";
CM_ SG_ 1495 DIR_oilFlowReq "Rear drive inverter: oil flow req; raw 255 = signal not available (SNA)";
CM_ SG_ 1495 DIR_criticalFlowReq "Rear drive inverter: critical flow req";
CM_ SG_ 1495 DIR_burnInStatus "Rear drive inverter: burn in status";
BA_DEF_ "BusType" STRING;
BA_DEF_ "DBName" STRING;
BA_DEF_ "Baudrate" INT 0 1000000;
BA_DEF_ "BaudrateCANFD" INT 0 16000000;
BA_DEF_ "Manufacturer" STRING;
BA_DEF_ "FirmwareVersion" STRING;
BA_DEF_ "VehicleModel" STRING;
BA_DEF_ BU_ "ECU" STRING;
BA_DEF_ BO_ "GenMsgCycleTime" INT 0 3600000;
BA_DEF_ BO_ "GenMsgSendType" ENUM "Cyclic","NotUsed","NotUsed","NotUsed","NotUsed","NotUsed","NotUsed","IfActive","NoMsgSendType","NotUsed";
BA_DEF_ BO_ "VFrameFormat" ENUM "StandardCAN","ExtendedCAN","reserved","J1939PG","reserved","reserved","reserved","reserved","reserved","reserved","reserved","reserved","reserved","reserved","StandardCAN_FD","ExtendedCAN_FD";
BA_DEF_ BO_ "CANFD_BRS" ENUM "0","1";
BA_DEF_ SG_ "GenSigSNA" STRING;
BA_DEF_ SG_ "SystemSignalLongSymbol" STRING;
BA_DEF_ SG_ "Confidence" ENUM "validated","plausible","layout-only","contradicted";
BA_DEF_DEF_ "BusType" "CAN";
BA_DEF_DEF_ "DBName" "";
BA_DEF_DEF_ "Baudrate" 500000;
BA_DEF_DEF_ "BaudrateCANFD" 2000000;
BA_DEF_DEF_ "Manufacturer" "";
BA_DEF_DEF_ "FirmwareVersion" "";
BA_DEF_DEF_ "VehicleModel" "";
BA_DEF_DEF_ "ECU" "";
BA_DEF_DEF_ "GenMsgCycleTime" 0;
BA_DEF_DEF_ "GenMsgSendType" "NoMsgSendType";
BA_DEF_DEF_ "VFrameFormat" "StandardCAN";
BA_DEF_DEF_ "CANFD_BRS" "1";
BA_DEF_DEF_ "GenSigSNA" "";
BA_DEF_DEF_ "SystemSignalLongSymbol" "";
BA_DEF_DEF_ "Confidence" "layout-only";
BA_ "DBName" "Model3_VEH";
BA_ "Manufacturer" "Tesla";
BA_ "FirmwareVersion" "2025.20.8";
BA_ "VehicleModel" "Model 3";
BA_ "ECU" BU_ APP "APP";
BA_ "ECU" BU_ BMS "BMS";
BA_ "ECU" BU_ CC "CC";
BA_ "ECU" BU_ CMP "CMP";
BA_ "ECU" BU_ CMPD "CMPD";
BA_ "ECU" BU_ CP "CP";
BA_ "ECU" BU_ DAS "DAS";
BA_ "ECU" BU_ DI "DI";
BA_ "ECU" BU_ DIF "DIF";
BA_ "ECU" BU_ DIR "DIR";
BA_ "ECU" BU_ EPBL "EPBL";
BA_ "ECU" BU_ EPBR "EPBR";
BA_ "ECU" BU_ EVSE "EVSE";
BA_ "ECU" BU_ FC "FC";
BA_ "ECU" BU_ GTW "GTW";
BA_ "ECU" BU_ HCML "HCML";
BA_ "ECU" BU_ HCMR "HCMR";
BA_ "ECU" BU_ HVP "HVP";
BA_ "ECU" BU_ ICR "ICR";
BA_ "ECU" BU_ PCS "PCS";
BA_ "ECU" BU_ PM "PM";
BA_ "ECU" BU_ PMF "PMF";
BA_ "ECU" BU_ PMR "PMR";
BA_ "ECU" BU_ PTC "PTC";
BA_ "ECU" BU_ SCCM "SCCM";
BA_ "ECU" BU_ SDCR "SDCR";
BA_ "ECU" BU_ TAS "TAS";
BA_ "ECU" BU_ UMC "UMC";
BA_ "ECU" BU_ VC "VC";
BA_ "ECU" BU_ VCFRONT "VCFRONT";
BA_ "ECU" BU_ VCLEFT "VCLEFT";
BA_ "ECU" BU_ VCRIGHT "VCRIGHT";
BA_ "ECU" BU_ VCSEC "VCSEC";
BA_ "GenMsgCycleTime" BO_ 909 1000;
BA_ "GenMsgSendType" BO_ 909 0;
BA_ "GenMsgCycleTime" BO_ 818 1000;
BA_ "GenMsgSendType" BO_ 818 0;
BA_ "GenMsgCycleTime" BO_ 1138 1000;
BA_ "GenMsgSendType" BO_ 1138 0;
BA_ "GenMsgCycleTime" BO_ 722 100;
BA_ "GenMsgSendType" BO_ 722 0;
BA_ "GenMsgCycleTime" BO_ 850 2000;
BA_ "GenMsgSendType" BO_ 850 0;
BA_ "GenMsgCycleTime" BO_ 306 10;
BA_ "GenMsgSendType" BO_ 306 0;
BA_ "GenMsgCycleTime" BO_ 768 1000;
BA_ "GenMsgSendType" BO_ 768 0;
BA_ "GenMsgCycleTime" BO_ 978 1000;
BA_ "GenMsgSendType" BO_ 978 0;
BA_ "GenMsgCycleTime" BO_ 1010 1000;
BA_ "GenMsgSendType" BO_ 1010 0;
BA_ "GenMsgCycleTime" BO_ 882 1000;
BA_ "GenMsgSendType" BO_ 882 0;
BA_ "GenMsgCycleTime" BO_ 946 30000;
BA_ "GenMsgSendType" BO_ 946 0;
BA_ "GenMsgCycleTime" BO_ 914 1000;
BA_ "GenMsgSendType" BO_ 914 0;
BA_ "GenMsgCycleTime" BO_ 594 100;
BA_ "GenMsgSendType" BO_ 594 0;
BA_ "GenMsgCycleTime" BO_ 674 100;
BA_ "GenMsgSendType" BO_ 674 0;
BA_ "GenMsgCycleTime" BO_ 658 100;
BA_ "GenMsgSendType" BO_ 658 0;
BA_ "GenMsgCycleTime" BO_ 1170 1000;
BA_ "GenMsgSendType" BO_ 1170 0;
BA_ "GenMsgCycleTime" BO_ 530 100;
BA_ "GenMsgSendType" BO_ 530 0;
BA_ "GenMsgCycleTime" BO_ 786 1000;
BA_ "GenMsgSendType" BO_ 786 0;
BA_ "GenMsgCycleTime" BO_ 754 100;
BA_ "GenMsgSendType" BO_ 754 0;
BA_ "GenMsgCycleTime" BO_ 810 5000;
BA_ "GenMsgSendType" BO_ 810 0;
BA_ "GenMsgCycleTime" BO_ 796 100;
BA_ "GenMsgSendType" BO_ 796 0;
BA_ "GenMsgCycleTime" BO_ 797 100;
BA_ "GenMsgSendType" BO_ 797 0;
BA_ "GenMsgCycleTime" BO_ 812 1000;
BA_ "GenMsgSendType" BO_ 812 0;
BA_ "GenMsgCycleTime" BO_ 870 1000;
BA_ "GenMsgSendType" BO_ 870 0;
BA_ "GenMsgCycleTime" BO_ 679 100;
BA_ "GenMsgSendType" BO_ 679 0;
BA_ "GenMsgCycleTime" BO_ 867 1000;
BA_ "GenMsgSendType" BO_ 867 0;
BA_ "GenMsgCycleTime" BO_ 669 100;
BA_ "GenMsgSendType" BO_ 669 0;
BA_ "GenMsgCycleTime" BO_ 541 100;
BA_ "GenMsgSendType" BO_ 541 0;
BA_ "GenMsgCycleTime" BO_ 1342 1000;
BA_ "GenMsgSendType" BO_ 1342 0;
BA_ "GenMsgCycleTime" BO_ 1885 200;
BA_ "GenMsgSendType" BO_ 1885 0;
BA_ "GenMsgCycleTime" BO_ 989 1000;
BA_ "GenMsgSendType" BO_ 989 0;
BA_ "GenMsgCycleTime" BO_ 605 100;
BA_ "GenMsgSendType" BO_ 605 0;
BA_ "GenMsgCycleTime" BO_ 893 1000;
BA_ "GenMsgSendType" BO_ 893 0;
BA_ "GenMsgCycleTime" BO_ 1001 500;
BA_ "GenMsgSendType" BO_ 1001 0;
BA_ "GenMsgCycleTime" BO_ 634 100;
BA_ "GenMsgSendType" BO_ 634 0;
BA_ "GenMsgCycleTime" BO_ 741 1000;
BA_ "GenMsgSendType" BO_ 741 0;
BA_ "GenMsgCycleTime" BO_ 886 1000;
BA_ "GenMsgSendType" BO_ 886 0;
BA_ "GenMsgCycleTime" BO_ 1367 1000;
BA_ "GenMsgSendType" BO_ 1367 0;
BA_ "GenMsgCycleTime" BO_ 2005 100;
BA_ "GenMsgSendType" BO_ 2005 0;
BA_ "GenMsgCycleTime" BO_ 633 100;
BA_ "GenMsgSendType" BO_ 633 0;
BA_ "GenMsgCycleTime" BO_ 821 1000;
BA_ "GenMsgSendType" BO_ 821 0;
BA_ "GenMsgCycleTime" BO_ 917 100;
BA_ "GenMsgSendType" BO_ 917 0;
BA_ "GenMsgCycleTime" BO_ 614 1000;
BA_ "GenMsgSendType" BO_ 614 0;
BA_ "GenMsgCycleTime" BO_ 789 1000;
BA_ "GenMsgSendType" BO_ 789 0;
BA_ "GenMsgCycleTime" BO_ 1495 1000;
BA_ "GenMsgSendType" BO_ 1495 0;
BA_ "Confidence" SG_ 909 APP_inTunnel 0;
BA_ "GenSigSNA" SG_ 909 APP_inTunnel "0";
BA_ "Confidence" SG_ 909 APP_windshieldHeaterOnReason 1;
BA_ "GenSigSNA" SG_ 909 APP_windshieldHeaterOnReason "0";
BA_ "Confidence" SG_ 909 APP_selfieCameraBlocked 0;
BA_ "GenSigSNA" SG_ 909 APP_selfieCameraBlocked "0";
BA_ "Confidence" SG_ 909 APP_selfieCameraLUX 0;
BA_ "GenSigSNA" SG_ 909 APP_selfieCameraLUX "255";
BA_ "Confidence" SG_ 909 APP_sceneTagClearlyRaining 0;
BA_ "GenSigSNA" SG_ 909 APP_sceneTagClearlyRaining "0";
BA_ "Confidence" SG_ 909 APP_sceneTagFog 0;
BA_ "GenSigSNA" SG_ 909 APP_sceneTagFog "0";
BA_ "Confidence" SG_ 909 APP_sceneTagFullyBlocked 0;
BA_ "GenSigSNA" SG_ 909 APP_sceneTagFullyBlocked "0";
BA_ "Confidence" SG_ 909 APP_sceneTagIndoors 0;
BA_ "GenSigSNA" SG_ 909 APP_sceneTagIndoors "0";
BA_ "Confidence" SG_ 909 APP_sceneTagLensFlare 0;
BA_ "GenSigSNA" SG_ 909 APP_sceneTagLensFlare "0";
BA_ "Confidence" SG_ 909 APP_sceneTagRaining 0;
BA_ "GenSigSNA" SG_ 909 APP_sceneTagRaining "0";
BA_ "Confidence" SG_ 909 APP_sceneTagSevereWeather 0;
BA_ "GenSigSNA" SG_ 909 APP_sceneTagSevereWeather "0";
BA_ "Confidence" SG_ 909 APP_sceneTagSnowing 0;
BA_ "GenSigSNA" SG_ 909 APP_sceneTagSnowing "0";
BA_ "Confidence" SG_ 909 APP_sceneTagSnowyRoad 0;
BA_ "GenSigSNA" SG_ 909 APP_sceneTagSnowyRoad "0";
BA_ "Confidence" SG_ 909 APP_sceneTagSunGlare 0;
BA_ "GenSigSNA" SG_ 909 APP_sceneTagSunGlare "0";
BA_ "Confidence" SG_ 909 APP_sceneTagTunnel 0;
BA_ "GenSigSNA" SG_ 909 APP_sceneTagTunnel "0";
BA_ "Confidence" SG_ 909 APP_sceneTagWetRoad 0;
BA_ "GenSigSNA" SG_ 909 APP_sceneTagWetRoad "0";
BA_ "Confidence" SG_ 909 APP_fisheyeInPathVisibility 0;
BA_ "GenSigSNA" SG_ 909 APP_fisheyeInPathVisibility "0";
BA_ "Confidence" SG_ 909 APP_fisheyeOverallVisibility 0;
BA_ "GenSigSNA" SG_ 909 APP_fisheyeOverallVisibility "0";
BA_ "Confidence" SG_ 909 APP_mainInPathVisibility 0;
BA_ "GenSigSNA" SG_ 909 APP_mainInPathVisibility "0";
BA_ "Confidence" SG_ 909 APP_mainOverallVisibility 0;
BA_ "GenSigSNA" SG_ 909 APP_mainOverallVisibility "0";
BA_ "Confidence" SG_ 909 APP_narrowInPathVisibility 0;
BA_ "GenSigSNA" SG_ 909 APP_narrowInPathVisibility "0";
BA_ "Confidence" SG_ 909 APP_narrowOverallVisibility 0;
BA_ "GenSigSNA" SG_ 909 APP_narrowOverallVisibility "0";
BA_ "Confidence" SG_ 909 APP_frontCamOcclusionType 0;
BA_ "Confidence" SG_ 818 BMS_bmbMinMaxMultiplexer 1;
BA_ "Confidence" SG_ 818 BMS_thermistorNumTMin 0;
BA_ "Confidence" SG_ 818 BMS_thermistorNumTMax 0;
BA_ "Confidence" SG_ 818 BMS_thermistorTMax 0;
BA_ "Confidence" SG_ 818 BMS_thermistorTMin 0;
BA_ "Confidence" SG_ 818 BMS_thermistorTAvg 0;
BA_ "Confidence" SG_ 818 BMS_brickVoltageMax 0;
BA_ "Confidence" SG_ 818 BMS_brickVoltageMin 0;
BA_ "Confidence" SG_ 818 BMS_brickNumVoltageMax 0;
BA_ "Confidence" SG_ 818 BMS_brickNumVoltageMin 0;
BA_ "Confidence" SG_ 1138 BMS_cellChargeDcCurrentLimit 1;
BA_ "Confidence" SG_ 1138 BMS_voltageRegCurrentTarget 1;
BA_ "Confidence" SG_ 1138 BMS_vehicleChargeDcCurrentLimit 1;
BA_ "Confidence" SG_ 1138 BMS_chargeCurrentLimitMode 1;
BA_ "Confidence" SG_ 1138 BMS_timeToFinishHeatForCharge 1;
BA_ "GenSigSNA" SG_ 1138 BMS_timeToFinishHeatForCharge "127";
BA_ "Confidence" SG_ 1138 BMS_diNodeModelTemp 1;
BA_ "GenSigSNA" SG_ 1138 BMS_diNodeModelTemp "2047";
BA_ "Confidence" SG_ 722 BMS_minBusVoltage 0;
BA_ "Confidence" SG_ 722 BMS_maxBusVoltage 0;
BA_ "Confidence" SG_ 722 BMS_maxChargeCurrent 0;
BA_ "Confidence" SG_ 722 BMS_maxDischargeCurrent 0;
BA_ "Confidence" SG_ 850 BMS_energyStatusMultiplexer 1;
BA_ "Confidence" SG_ 850 BMS_nominalFullPackEnergy 0;
BA_ "GenSigSNA" SG_ 850 BMS_nominalFullPackEnergy "65535";
BA_ "Confidence" SG_ 850 BMS_nominalEnergyRemaining 0;
BA_ "GenSigSNA" SG_ 850 BMS_nominalEnergyRemaining "65535";
BA_ "Confidence" SG_ 850 BMS_idealEnergyRemaining 0;
BA_ "GenSigSNA" SG_ 850 BMS_idealEnergyRemaining "65535";
BA_ "Confidence" SG_ 850 BMS_fullChargeComplete 0;
BA_ "Confidence" SG_ 850 BMS_energyBuffer 0;
BA_ "GenSigSNA" SG_ 850 BMS_energyBuffer "65535";
BA_ "Confidence" SG_ 850 BMS_expectedEnergyRemaining 0;
BA_ "GenSigSNA" SG_ 850 BMS_expectedEnergyRemaining "65535";
BA_ "Confidence" SG_ 850 BMS_energyToChargeComplete 0;
BA_ "GenSigSNA" SG_ 850 BMS_energyToChargeComplete "65535";
BA_ "Confidence" SG_ 850 BMS_energyRemainingDisplay 0;
BA_ "GenSigSNA" SG_ 850 BMS_energyRemainingDisplay "65535";
BA_ "Confidence" SG_ 850 BMS_energyRemainingTDisplay 0;
BA_ "GenSigSNA" SG_ 850 BMS_energyRemainingTDisplay "65535";
BA_ "Confidence" SG_ 850 BMS_energyDisplayErrorBlendRate 0;
BA_ "Confidence" SG_ 850 BMS_userFacingSoe 0;
BA_ "GenSigSNA" SG_ 850 BMS_userFacingSoe "2047";
BA_ "Confidence" SG_ 306 BMS_packVoltage 1;
BA_ "Confidence" SG_ 306 BMS_packCurrent 0;
BA_ "GenSigSNA" SG_ 306 BMS_packCurrent "32768";
BA_ "Confidence" SG_ 306 BMS_currentUnfiltered 0;
BA_ "GenSigSNA" SG_ 306 BMS_currentUnfiltered "32768";
BA_ "Confidence" SG_ 306 BMS_chgTimeToFull 1;
BA_ "GenSigSNA" SG_ 306 BMS_chgTimeToFull "4095";
BA_ "Confidence" SG_ 768 BMS_infoIndex 1;
BA_ "Confidence" SG_ 768 BMS_buildType 0;
BA_ "Confidence" SG_ 768 BMS_buildConfigId 0;
BA_ "Confidence" SG_ 768 BMS_hardwareId 0;
BA_ "Confidence" SG_ 768 BMS_componentId 0;
BA_ "Confidence" SG_ 768 BMS_pcbaId 0;
BA_ "Confidence" SG_ 768 BMS_assemblyId 0;
BA_ "Confidence" SG_ 768 BMS_usageId 0;
BA_ "Confidence" SG_ 768 BMS_subUsageId 0;
BA_ "Confidence" SG_ 768 BMS_platformType 0;
BA_ "Confidence" SG_ 768 BMS_appCrc 0;
BA_ "Confidence" SG_ 768 BMS_appGitHash 0;
BA_ "Confidence" SG_ 768 BMS_bootGitHash 0;
BA_ "Confidence" SG_ 768 BMS_bootUdsProtoVersion 0;
BA_ "Confidence" SG_ 768 BMS_bootCrc 0;
BA_ "Confidence" SG_ 978 BMS_kwhDischargeTotal 0;
BA_ "Confidence" SG_ 978 BMS_kwhChargeTotal 0;
BA_ "Confidence" SG_ 1010 BMS_kwhCounter_Id 1;
BA_ "Confidence" SG_ 1010 BMS_acChargerKwhTotal 0;
BA_ "Confidence" SG_ 1010 BMS_dcChargerKwhTotal 0;
BA_ "Confidence" SG_ 1010 BMS_kwhRegenChargeTotal 0;
BA_ "Confidence" SG_ 1010 BMS_kwhDriveDischargeTotal 0;
BA_ "Confidence" SG_ 1010 BMS_kwhDischargeTotalModule1 0;
BA_ "Confidence" SG_ 1010 BMS_kwhChargeTotalModule1 0;
BA_ "Confidence" SG_ 1010 BMS_kwhAcChargeTotalModule1 0;
BA_ "Confidence" SG_ 1010 BMS_kwhDcChargeTotalModule1 0;
BA_ "Confidence" SG_ 1010 BMS_kwhDischargeTotalModule2 0;
BA_ "Confidence" SG_ 1010 BMS_kwhChargeTotalModule2 0;
BA_ "Confidence" SG_ 1010 BMS_kwhAcChargeTotalModule2 0;
BA_ "Confidence" SG_ 1010 BMS_kwhDcChargeTotalModule2 0;
BA_ "Confidence" SG_ 1010 BMS_kwhDischargeTotalModule3 0;
BA_ "Confidence" SG_ 1010 BMS_kwhChargeTotalModule3 0;
BA_ "Confidence" SG_ 1010 BMS_kwhAcChargeTotalModule3 0;
BA_ "Confidence" SG_ 1010 BMS_kwhDcChargeTotalModule3 0;
BA_ "Confidence" SG_ 1010 BMS_kwhDischargeTotalModule4 0;
BA_ "Confidence" SG_ 1010 BMS_kwhChargeTotalModule4 0;
BA_ "Confidence" SG_ 1010 BMS_kwhAcChargeTotalModule4 0;
BA_ "Confidence" SG_ 1010 BMS_kwhDcChargeTotalModule4 0;
BA_ "Confidence" SG_ 882 BMS_log1MuxId 1;
BA_ "Confidence" SG_ 882 BMS_extDcPrechargeVoltageLimit 0;
BA_ "Confidence" SG_ 882 BMS_dcChargeCurrentRequest 0;
BA_ "Confidence" SG_ 882 BMS_dcChargeCurrentLimit 0;
BA_ "Confidence" SG_ 882 BMS_dcDischargeEnabled 0;
BA_ "Confidence" SG_ 882 BMS_rippleChargeRetryCount 0;
BA_ "Confidence" SG_ 882 BMS_dcChargeVoltageLimit 0;
BA_ "Confidence" SG_ 882 BMS_dcChargePowerLimit 0;
BA_ "Confidence" SG_ 882 BMS_maxExtIsoFcLinkV 0;
BA_ "Confidence" SG_ 882 BMS_socByDeltaVEnabled 0;
BA_ "Confidence" SG_ 882 BMS_socByDvMaxSocLimit 0;
BA_ "Confidence" SG_ 882 BMS_socByDvVoltageChangeOverAh 0;
BA_ "Confidence" SG_ 882 BMS_socByDvMaxSocByAhCorrected 0;
BA_ "Confidence" SG_ 882 BMS_socByDvMaxBrickVoltage 0;
BA_ "Confidence" SG_ 882 BMS_socByDvMaxBrickId 0;
BA_ "Confidence" SG_ 946 BMS_log2MuxId 1;
BA_ "Confidence" SG_ 946 BMS_cacAvg 0;
BA_ "Confidence" SG_ 946 BMS_cacMin 0;
BA_ "Confidence" SG_ 946 BMS_cacMinBrickId 0;
BA_ "Confidence" SG_ 946 BMS_cacMax 0;
BA_ "Confidence" SG_ 946 BMS_cacMaxBrickId 0;
BA_ "Confidence" SG_ 946 BMS_acRippleConfigNvramValid 0;
BA_ "Confidence" SG_ 946 BMS_hvChain_useLeakyBucket 0;
BA_ "Confidence" SG_ 946 BMS_hvChain_iLimit 0;
BA_ "GenSigSNA" SG_ 946 BMS_hvChain_iLimit "16383";
BA_ "Confidence" SG_ 946 BMS_hvChain_limitingState 0;
BA_ "GenSigSNA" SG_ 946 BMS_hvChain_limitingState "511";
BA_ "Confidence" SG_ 946 BMS_hvChain_limitingStateTempera 0;
BA_ "GenSigSNA" SG_ 946 BMS_hvChain_limitingStateTempera "4096";
BA_ "SystemSignalLongSymbol" SG_ 946 BMS_hvChain_limitingStateTempera "BMS_hvChain_limitingStateTemperature";
BA_ "Confidence" SG_ 946 BMS_acRippleIsSupported 0;
BA_ "Confidence" SG_ 946 BMS_acRippleStartTemperatureMax 0;
BA_ "Confidence" SG_ 946 BMS_acRippleStartTemperatureMin 0;
BA_ "Confidence" SG_ 946 BMS_fcLinkTestDecayTime 0;
BA_ "GenSigSNA" SG_ 946 BMS_fcLinkTestDecayTime "1023";
BA_ "Confidence" SG_ 946 BMS_fcLinkTestTimeSinceLastRun 0;
BA_ "Confidence" SG_ 946 BMS_pcsPrechargeTargetVoltage 0;
BA_ "Confidence" SG_ 946 BMS_recentOvUvAlert 0;
BA_ "Confidence" SG_ 946 BMS_recentIsoAlert 0;
BA_ "Confidence" SG_ 946 BMS_recentBmbMiaAlert 0;
BA_ "Confidence" SG_ 946 BMS_cacBlendingConfigNvramValid 0;
BA_ "Confidence" SG_ 946 BMS_cacBlendingEnabled 0;
BA_ "Confidence" SG_ 946 BMS_cacBlendPercentPerCycle 0;
BA_ "Confidence" SG_ 946 BMS_energyVariableChgRequested 0;
BA_ "Confidence" SG_ 946 BMS_packRestTime 0;
BA_ "Confidence" SG_ 946 BMS_idealEnergyFloor 0;
BA_ "GenSigSNA" SG_ 946 BMS_idealEnergyFloor "1023";
BA_ "Confidence" SG_ 946 BMS_thmGradientSlopeCondition 0;
BA_ "Confidence" SG_ 946 BMS_recentSlopeConditon 0;
BA_ "Confidence" SG_ 946 BMS_dynamicEnergyBuffer 0;
BA_ "GenSigSNA" SG_ 946 BMS_dynamicEnergyBuffer "1023";
BA_ "Confidence" SG_ 946 BMS_temperatureCondition 0;
BA_ "Confidence" SG_ 946 BMS_thmGradientSlope 0;
BA_ "Confidence" SG_ 946 BMS_thmGradient 0;
BA_ "Confidence" SG_ 946 BMS_dSocNormalizedMin 0;
BA_ "GenSigSNA" SG_ 946 BMS_dSocNormalizedMin "4095";
BA_ "Confidence" SG_ 946 BMS_dSocNormalizedFiltMin 0;
BA_ "GenSigSNA" SG_ 946 BMS_dSocNormalizedFiltMin "4095";
BA_ "Confidence" SG_ 946 BMS_dSocMinAlpha 0;
BA_ "GenSigSNA" SG_ 946 BMS_dSocMinAlpha "4095";
BA_ "Confidence" SG_ 946 BMS_dSocMaxLowAlphaCounter 0;
BA_ "Confidence" SG_ 946 BMS_dSocMinAlphaBrickID 0;
BA_ "Confidence" SG_ 946 BMS_dSocCacMargin 0;
BA_ "GenSigSNA" SG_ 946 BMS_dSocCacMargin "511";
BA_ "Confidence" SG_ 946 BMS_lifeModelAvgTempSeverity 0;
BA_ "GenSigSNA" SG_ 946 BMS_lifeModelAvgTempSeverity "31";
BA_ "Confidence" SG_ 946 BMS_lifeModelDepthOfDischargeSev 0;
BA_ "GenSigSNA" SG_ 946 BMS_lifeModelDepthOfDischargeSev "255";
BA_ "SystemSignalLongSymbol" SG_ 946 BMS_lifeModelDepthOfDischargeSev "BMS_lifeModelDepthOfDischargeSeverity";
BA_ "Confidence" SG_ 946 BMS_lifeModelHistogramCapacityLo 0;
BA_ "GenSigSNA" SG_ 946 BMS_lifeModelHistogramCapacityLo "511";
BA_ "SystemSignalLongSymbol" SG_ 946 BMS_lifeModelHistogramCapacityLo "BMS_lifeModelHistogramCapacityLoss";
BA_ "Confidence" SG_ 946 BMS_lifeModelHistogramBrickCapac 0;
BA_ "GenSigSNA" SG_ 946 BMS_lifeModelHistogramBrickCapac "8191";
BA_ "SystemSignalLongSymbol" SG_ 946 BMS_lifeModelHistogramBrickCapac "BMS_lifeModelHistogramBrickCapacity";
BA_ "Confidence" SG_ 946 BMS_lifeModelDcrGrowthPercent 0;
BA_ "GenSigSNA" SG_ 946 BMS_lifeModelDcrGrowthPercent "8192";
BA_ "Confidence" SG_ 946 BMS_nominalFullPackEnergyRaw 0;
BA_ "GenSigSNA" SG_ 946 BMS_nominalFullPackEnergyRaw "65535";
BA_ "Confidence" SG_ 946 BMS_userChargeCalibratingReason 1;
BA_ "Confidence" SG_ 946 BMS_nominalEnergyRemainingBuffer 1;
BA_ "GenSigSNA" SG_ 946 BMS_nominalEnergyRemainingBuffer "65535";
BA_ "SystemSignalLongSymbol" SG_ 946 BMS_nominalEnergyRemainingBuffer "BMS_nominalEnergyRemainingBuffered";
BA_ "Confidence" SG_ 946 BMS_idealEnergyRemainingBuffered 1;
BA_ "GenSigSNA" SG_ 946 BMS_idealEnergyRemainingBuffered "65535";
BA_ "Confidence" SG_ 946 BMS_largestCacSpreadErrorLower 0;
BA_ "GenSigSNA" SG_ 946 BMS_largestCacSpreadErrorLower "4095";
BA_ "Confidence" SG_ 946 BMS_lifeModelAverageCac 0;
BA_ "GenSigSNA" SG_ 946 BMS_lifeModelAverageCac "4095";
BA_ "Confidence" SG_ 946 BMS_lifeModelCacBrick1 0;
BA_ "GenSigSNA" SG_ 946 BMS_lifeModelCacBrick1 "4095";
BA_ "Confidence" SG_ 946 BMS_lifeModelAverageOffset 0;
BA_ "GenSigSNA" SG_ 946 BMS_lifeModelAverageOffset "512";
BA_ "Confidence" SG_ 946 BMS_percentCacUpdatesInTimeWindo 0;
BA_ "SystemSignalLongSymbol" SG_ 946 BMS_percentCacUpdatesInTimeWindo "BMS_percentCacUpdatesInTimeWindow";
BA_ "Confidence" SG_ 946 BMS_lifeModelMaxCacBrickId 0;
BA_ "GenSigSNA" SG_ 946 BMS_lifeModelMaxCacBrickId "255";
BA_ "Confidence" SG_ 946 BMS_lifeModelMaxCac 0;
BA_ "GenSigSNA" SG_ 946 BMS_lifeModelMaxCac "4095";
BA_ "Confidence" SG_ 946 BMS_lifeModelMinCacBrickId 0;
BA_ "GenSigSNA" SG_ 946 BMS_lifeModelMinCacBrickId "255";
BA_ "Confidence" SG_ 946 BMS_lifeModelMinCac 0;
BA_ "GenSigSNA" SG_ 946 BMS_lifeModelMinCac "4095";
BA_ "Confidence" SG_ 946 BMS_restingPointCacAvg 0;
BA_ "GenSigSNA" SG_ 946 BMS_restingPointCacAvg "4095";
BA_ "Confidence" SG_ 946 BMS_cacEstimationSource 0;
BA_ "Confidence" SG_ 946 BMS_synchronizedCacMaxRaw 0;
BA_ "GenSigSNA" SG_ 946 BMS_synchronizedCacMaxRaw "4095";
BA_ "Confidence" SG_ 946 BMS_synchronizedCacMinRaw 0;
BA_ "GenSigSNA" SG_ 946 BMS_synchronizedCacMinRaw "4095";
BA_ "Confidence" SG_ 946 BMS_largestSyncCacErrorStartSoc 0;
BA_ "Confidence" SG_ 946 BMS_largestSyncCacErrorEndSoc 0;
BA_ "Confidence" SG_ 946 BMS_runtimeSocConfigNvramValid 0;
BA_ "Confidence" SG_ 946 BMS_runtimeSocCorrectionsEnabled 0;
BA_ "Confidence" SG_ 946 BMS_rubberBandingEnabled 0;
BA_ "Confidence" SG_ 946 BMS_rubberBandingConfigNvramVali 0;
BA_ "SystemSignalLongSymbol" SG_ 946 BMS_rubberBandingConfigNvramVali "BMS_rubberBandingConfigNvramValid";
BA_ "Confidence" SG_ 946 BMS_runtimeSocMinTempForModel 0;
BA_ "Confidence" SG_ 946 BMS_energyBufferConfigNvramValid 0;
BA_ "Confidence" SG_ 946 BMS_thermalEvent1pDetectConfigDi 0;
BA_ "SystemSignalLongSymbol" SG_ 946 BMS_thermalEvent1pDetectConfigDi "BMS_thermalEvent1pDetectConfigDisabled";
BA_ "Confidence" SG_ 946 BMS_sohEnergy 0;
BA_ "GenSigSNA" SG_ 946 BMS_sohEnergy "2047";
BA_ "Confidence" SG_ 946 BMS_fullCapacitySohEnergy 0;
BA_ "GenSigSNA" SG_ 946 BMS_fullCapacitySohEnergy "2047";
BA_ "Confidence" SG_ 946 BMS_calibratedCapacitySohEnergy 0;
BA_ "GenSigSNA" SG_ 946 BMS_calibratedCapacitySohEnergy "2047";
BA_ "Confidence" SG_ 946 BMS_estimatedCapacitySohEnergy 0;
BA_ "GenSigSNA" SG_ 946 BMS_estimatedCapacitySohEnergy "2047";
BA_ "Confidence" SG_ 946 BMS_prevUserFacingSohEnergy 0;
BA_ "GenSigSNA" SG_ 946 BMS_prevUserFacingSohEnergy "2047";
BA_ "Confidence" SG_ 946 BMS_stateOfHealthMinCac 0;
BA_ "GenSigSNA" SG_ 946 BMS_stateOfHealthMinCac "8191";
BA_ "Confidence" SG_ 946 BMS_lifeModelStorageLossPackAge 0;
BA_ "GenSigSNA" SG_ 946 BMS_lifeModelStorageLossPackAge "16383";
BA_ "Confidence" SG_ 946 BMS_lifeModelThroughputCycleCoun 1;
BA_ "GenSigSNA" SG_ 946 BMS_lifeModelThroughputCycleCoun "4095";
BA_ "SystemSignalLongSymbol" SG_ 946 BMS_lifeModelThroughputCycleCoun "BMS_lifeModelThroughputCycleCount";
BA_ "Confidence" SG_ 946 BMS_lifeModelThroughputDcrCycleC 1;
BA_ "GenSigSNA" SG_ 946 BMS_lifeModelThroughputDcrCycleC "4095";
BA_ "SystemSignalLongSymbol" SG_ 946 BMS_lifeModelThroughputDcrCycleC "BMS_lifeModelThroughputDcrCycleCount";
BA_ "Confidence" SG_ 946 BMS_energyWalkCounter 0;
BA_ "Confidence" SG_ 946 BMS_energyWalkTimeoutCounter 0;
BA_ "Confidence" SG_ 946 BMS_dynamicCcvEnabled 0;
BA_ "Confidence" SG_ 946 BMS_chargeTargetLookupSoc 1;
BA_ "Confidence" SG_ 946 BMS_stateOfHealth 1;
BA_ "GenSigSNA" SG_ 946 BMS_stateOfHealth "1023";
BA_ "Confidence" SG_ 914 BMS_packConfigMultiplexer 1;
BA_ "Confidence" SG_ 914 BMS_reservedConfig_0 1;
BA_ "Confidence" SG_ 914 BMS_moduleType 0;
BA_ "Confidence" SG_ 914 BMS_thermalPackType 0;
BA_ "Confidence" SG_ 914 BMS_packMass 0;
BA_ "Confidence" SG_ 914 BMS_platformMaxBusVoltage 0;
BA_ "Confidence" SG_ 914 BMS_standbySupplyContinuousPower 0;
BA_ "SystemSignalLongSymbol" SG_ 914 BMS_standbySupplyContinuousPower "BMS_standbySupplyContinuousPowerLimit";
BA_ "Confidence" SG_ 594 BMS_maxRegenPower 0;
BA_ "Confidence" SG_ 594 BMS_maxDischargePower 0;
BA_ "Confidence" SG_ 594 BMS_maxStationaryHeatPower 0;
BA_ "Confidence" SG_ 594 BMS_powerLimitsState 0;
BA_ "Confidence" SG_ 594 BMS_notEnoughPowerForHeatPump 1;
BA_ "Confidence" SG_ 594 BMS_instantChargePowerCapability 0;
BA_ "GenSigSNA" SG_ 594 BMS_instantChargePowerCapability "65535";
BA_ "Confidence" SG_ 674 BMS_acRippleCurrentAmplitudeLimi 1;
BA_ "SystemSignalLongSymbol" SG_ 674 BMS_acRippleCurrentAmplitudeLimi "BMS_acRippleCurrentAmplitudeLimit";
BA_ "Confidence" SG_ 674 BMS_acRippleMaxVoltageLimit 1;
BA_ "Confidence" SG_ 674 BMS_acRippleMinVoltageLimit 1;
BA_ "Confidence" SG_ 674 BMS_acRippleFrequencyRequest 1;
BA_ "GenSigSNA" SG_ 674 BMS_acRippleFrequencyRequest "63";
BA_ "Confidence" SG_ 674 BMS_acRippleCurrentAmplitudeRequ 1;
BA_ "SystemSignalLongSymbol" SG_ 674 BMS_acRippleCurrentAmplitudeRequ "BMS_acRippleCurrentAmplitudeRequest";
BA_ "Confidence" SG_ 674 BMS_acRippleRequest 1;
BA_ "Confidence" SG_ 658 BMS_socMin 0;
BA_ "Confidence" SG_ 658 BMS_socUI 0;
BA_ "Confidence" SG_ 658 BMS_socMax 0;
BA_ "Confidence" SG_ 658 BMS_socAvg 0;
BA_ "Confidence" SG_ 658 BMS_beginningOfLifePackEnergy 0;
BA_ "GenSigSNA" SG_ 658 BMS_beginningOfLifePackEnergy "1023";
BA_ "Confidence" SG_ 658 BMS_battTempPct 1;
BA_ "GenSigSNA" SG_ 658 BMS_battTempPct "255";
BA_ "Confidence" SG_ 658 BMS_userChargeCurrentLimitMode 1;
BA_ "Confidence" SG_ 1170 BMS_sohEnergyPercent 0;
BA_ "GenSigSNA" SG_ 1170 BMS_sohEnergyPercent "1023";
BA_ "Confidence" SG_ 1170 BMS_userFacingSohTestState 0;
BA_ "Confidence" SG_ 1170 BMS_userFacingSohTestEndMode 0;
BA_ "Confidence" SG_ 1170 BMS_timeSinceSohUpdate 0;
BA_ "GenSigSNA" SG_ 1170 BMS_timeSinceSohUpdate "4095";
BA_ "Confidence" SG_ 1170 BMS_sohTestCycleFlag 0;
BA_ "Confidence" SG_ 1170 BMS_sohTestIsBlocked 0;
BA_ "Confidence" SG_ 1170 BMS_calibratedSohAvailable 0;
BA_ "Confidence" SG_ 1170 BMS_requiredEvsePowerForSoh 0;
BA_ "GenSigSNA" SG_ 1170 BMS_requiredEvsePowerForSoh "255";
BA_ "Confidence" SG_ 1170 BMS_distanceSinceSohUpdate 0;
BA_ "GenSigSNA" SG_ 1170 BMS_distanceSinceSohUpdate "65535";
BA_ "Confidence" SG_ 530 BMS_hvacPowerRequest 0;
BA_ "Confidence" SG_ 530 BMS_notEnoughPowerForDrive 0;
BA_ "Confidence" SG_ 530 BMS_notEnoughPowerForSupport 0;
BA_ "Confidence" SG_ 530 BMS_preconditionAllowed 0;
BA_ "Confidence" SG_ 530 BMS_updateAllowed 0;
BA_ "Confidence" SG_ 530 BMS_activeHeatingWorthwhile 1;
BA_ "Confidence" SG_ 530 BMS_cpMiaOnHvs 1;
BA_ "Confidence" SG_ 530 BMS_pcsPwmEnabled 1;
BA_ "Confidence" SG_ 530 BMS_contactorState 0;
BA_ "GenSigSNA" SG_ 530 BMS_contactorState "0";
BA_ "Confidence" SG_ 530 BMS_userChargeStatus 0;
BA_ "Confidence" SG_ 530 BMS_chargeRequest 1;
BA_ "Confidence" SG_ 530 BMS_state 0;
BA_ "GenSigSNA" SG_ 530 BMS_state "9";
BA_ "Confidence" SG_ 530 BMS_diLimpRequest 1;
BA_ "Confidence" SG_ 530 BMS_chgPowerAvailable 1;
BA_ "GenSigSNA" SG_ 530 BMS_chgPowerAvailable "4095";
BA_ "Confidence" SG_ 530 BMS_chargeRetryCount 1;
BA_ "Confidence" SG_ 530 BMS_conditioningRequest 0;
BA_ "Confidence" SG_ 530 BMS_smStateRequest 0;
BA_ "GenSigSNA" SG_ 530 BMS_smStateRequest "9";
BA_ "Confidence" SG_ 530 BMS_hvState 0;
BA_ "Confidence" SG_ 786 BMS_powerDissipation 1;
BA_ "Confidence" SG_ 786 BMS_flowRequest 1;
BA_ "Confidence" SG_ 786 BMS_inletActiveCoolTargetT 1;
BA_ "Confidence" SG_ 786 BMS_inletPassiveTargetT 1;
BA_ "Confidence" SG_ 786 BMS_inletActiveHeatTargetT 1;
BA_ "Confidence" SG_ 786 BMS_minPackTemperature 1;
BA_ "Confidence" SG_ 786 BMS_maxPackTemperature 1;
BA_ "Confidence" SG_ 754 BMS_nmGoingToSleep 0;
BA_ "Confidence" SG_ 754 BMS_nmWakeUpBus 0;
BA_ "Confidence" SG_ 754 BMS_hvsBusAsleep 0;
BA_ "Confidence" SG_ 754 BMS_nmKeepAwakeReason 1;
BA_ "GenSigSNA" SG_ 754 BMS_nmKeepAwakeReason "0";
BA_ "Confidence" SG_ 754 BMS_nmWakeUpReason 0;
BA_ "Confidence" SG_ 810 BMS_thermalEventSuspected 0;
BA_ "Confidence" SG_ 810 BMS_vehicleNotificationsCounter 0;
BA_ "Confidence" SG_ 810 BMS_isolationResistance 0;
BA_ "GenSigSNA" SG_ 810 BMS_isolationResistance "1023";
BA_ "Confidence" SG_ 810 BMS_vehicleNotificationsChecksum 0;
BA_ "Confidence" SG_ 796 CC_currentLimit 0;
BA_ "GenSigSNA" SG_ 796 CC_currentLimit "255";
BA_ "Confidence" SG_ 796 CC_pilotState 0;
BA_ "GenSigSNA" SG_ 796 CC_pilotState "3";
BA_ "Confidence" SG_ 796 CC_numPhases 0;
BA_ "GenSigSNA" SG_ 796 CC_numPhases "0";
BA_ "Confidence" SG_ 796 CC_line1Voltage 0;
BA_ "GenSigSNA" SG_ 796 CC_line1Voltage "511";
BA_ "Confidence" SG_ 796 CC_gridGrounding 0;
BA_ "GenSigSNA" SG_ 796 CC_gridGrounding "2";
BA_ "Confidence" SG_ 796 CC_deltaTransformer 0;
BA_ "Confidence" SG_ 796 CC_numVehCharging 0;
BA_ "Confidence" SG_ 796 CC_line2Voltage 0;
BA_ "GenSigSNA" SG_ 796 CC_line2Voltage "511";
BA_ "Confidence" SG_ 796 CC_line3Voltage 0;
BA_ "GenSigSNA" SG_ 796 CC_line3Voltage "511";
BA_ "Confidence" SG_ 796 CC_groundResistance 0;
BA_ "GenSigSNA" SG_ 796 CC_groundResistance "4095";
BA_ "Confidence" SG_ 797 CC_chgStatus2Index 1;
BA_ "Confidence" SG_ 797 CC_buttonState 0;
BA_ "Confidence" SG_ 812 CC_logIndex 1;
BA_ "Confidence" SG_ 812 CC_activeConnectorID 0;
BA_ "Confidence" SG_ 812 CC_temperature1 0;
BA_ "Confidence" SG_ 812 CC_temperature2 0;
BA_ "Confidence" SG_ 812 CC_temperature3 0;
BA_ "Confidence" SG_ 812 CC_contactor1Closed 0;
BA_ "Confidence" SG_ 812 CC_contactor2Closed 0;
BA_ "Confidence" SG_ 812 CC_temperature4 0;
BA_ "Confidence" SG_ 812 CC_conn1Current 0;
BA_ "GenSigSNA" SG_ 812 CC_conn1Current "255";
BA_ "Confidence" SG_ 812 CC_conn2Current 0;
BA_ "GenSigSNA" SG_ 812 CC_conn2Current "255";
BA_ "Confidence" SG_ 812 CC_conn3Current 0;
BA_ "GenSigSNA" SG_ 812 CC_conn3Current "255";
BA_ "Confidence" SG_ 812 CC_conn4Current 0;
BA_ "GenSigSNA" SG_ 812 CC_conn4Current "255";
BA_ "Confidence" SG_ 812 CC_lifetimei2t 0;
BA_ "Confidence" SG_ 812 CC_lifetimeCtrCycles 0;
BA_ "Confidence" SG_ 812 CC_lifetimeCtrCyclesLoaded 0;
BA_ "Confidence" SG_ 812 CC_lifetimeAlertCount 0;
BA_ "Confidence" SG_ 812 CC_lifetimeThermalFoldbacks 0;
BA_ "Confidence" SG_ 812 CC_lifetimeAvgStartupTemp 0;
BA_ "Confidence" SG_ 870 CMPD_infoIndex 1;
BA_ "Confidence" SG_ 870 CMPD_infoBuildType 0;
BA_ "Confidence" SG_ 870 CMPD_infoBuildConfigId 0;
BA_ "Confidence" SG_ 870 CMPD_infoHardwareId 0;
BA_ "Confidence" SG_ 870 CMPD_infoComponentId 0;
BA_ "Confidence" SG_ 870 CMPD_infoPcbaId 0;
BA_ "Confidence" SG_ 870 CMPD_infoAssemblyId 0;
BA_ "GenSigSNA" SG_ 870 CMPD_infoAssemblyId "255";
BA_ "Confidence" SG_ 870 CMPD_infoUsageId 0;
BA_ "Confidence" SG_ 870 CMPD_infoSubUsageId 0;
BA_ "Confidence" SG_ 679 CMPD_speedRPM 0;
BA_ "Confidence" SG_ 679 CMPD_speedDuty 0;
BA_ "Confidence" SG_ 679 CMPD_inputHVPower 0;
BA_ "Confidence" SG_ 679 CMPD_inputHVCurrent 0;
BA_ "Confidence" SG_ 679 CMPD_inputHVVoltage 0;
BA_ "Confidence" SG_ 679 CMPD_2ShuntModeActive 0;
BA_ "Confidence" SG_ 679 CMPD_powerLimitActive 0;
BA_ "Confidence" SG_ 679 CMPD_state 0;
BA_ "GenSigSNA" SG_ 679 CMPD_state "15";
BA_ "Confidence" SG_ 679 CMPD_wasteHeatState 0;
BA_ "Confidence" SG_ 679 CMPD_powerLimitTooLowToStart 0;
BA_ "Confidence" SG_ 679 CMPD_ready 0;
BA_ "Confidence" SG_ 867 CMP_infoIndex 1;
BA_ "Confidence" SG_ 867 CMP_infoBuildType 0;
BA_ "Confidence" SG_ 867 CMP_infoBuildConfigId 0;
BA_ "Confidence" SG_ 867 CMP_infoHardwareId 0;
BA_ "Confidence" SG_ 867 CMP_infoComponentId 0;
BA_ "Confidence" SG_ 867 CMP_infoPcbaId 0;
BA_ "Confidence" SG_ 867 CMP_infoAssemblyId 0;
BA_ "GenSigSNA" SG_ 867 CMP_infoAssemblyId "255";
BA_ "Confidence" SG_ 867 CMP_infoUsageId 0;
BA_ "Confidence" SG_ 867 CMP_infoSubUsageId 0;
BA_ "Confidence" SG_ 867 CMP_infoPlatformType 0;
BA_ "Confidence" SG_ 867 CMP_infoAppCrc 0;
BA_ "Confidence" SG_ 867 CMP_infoBootUdsProtoVersion 0;
BA_ "Confidence" SG_ 867 CMP_infoBootCrc 0;
BA_ "Confidence" SG_ 669 CP_evseOutputDcCurrent 0;
BA_ "Confidence" SG_ 669 CP_evseOutputDcVoltage 0;
BA_ "Confidence" SG_ 669 CP_evseOutputDcCurrentStale 0;
BA_ "Confidence" SG_ 541 CP_evseAccept 0;
BA_ "Confidence" SG_ 541 CP_evseRequest 0;
BA_ "Confidence" SG_ 541 CP_proximity 0;
BA_ "GenSigSNA" SG_ 541 CP_proximity "0";
BA_ "Confidence" SG_ 541 CP_pilot 0;
BA_ "GenSigSNA" SG_ 541 CP_pilot "7";
BA_ "Confidence" SG_ 541 CP_digitalCommsEstablished 0;
BA_ "Confidence" SG_ 541 CP_pilotCurrent 0;
BA_ "Confidence" SG_ 541 CP_cableType 0;
BA_ "GenSigSNA" SG_ 541 CP_cableType "4";
BA_ "Confidence" SG_ 541 CP_iecPilotState 0;
BA_ "GenSigSNA" SG_ 541 CP_iecPilotState "9";
BA_ "Confidence" SG_ 541 CP_plcSupported 0;
BA_ "Confidence" SG_ 541 CP_cableCurrentLimit 0;
BA_ "Confidence" SG_ 541 CP_teslaSwcanState 0;
BA_ "Confidence" SG_ 541 CP_evseChargeType_UI 0;
BA_ "Confidence" SG_ 541 CP_gbState 0;
BA_ "Confidence" SG_ 541 CP_gbdcStopChargeReason 0;
BA_ "Confidence" SG_ 541 CP_gbdcFailureReason 0;
BA_ "Confidence" SG_ 541 CP_gbdcChargeAttempts 0;
BA_ "Confidence" SG_ 541 CP_acChargeState 0;
BA_ "Confidence" SG_ 541 CP_teslaDcState 1;
BA_ "Confidence" SG_ 1342 CP_infoIndex 1;
BA_ "Confidence" SG_ 1342 CP_buildType 0;
BA_ "Confidence" SG_ 1342 CP_buildConfigId 0;
BA_ "Confidence" SG_ 1342 CP_hardwareId 0;
BA_ "Confidence" SG_ 1342 CP_componentId 0;
BA_ "Confidence" SG_ 1342 CP_pcbaId 0;
BA_ "Confidence" SG_ 1342 CP_assemblyId 0;
BA_ "Confidence" SG_ 1342 CP_usageId 0;
BA_ "Confidence" SG_ 1342 CP_subUsageId 0;
BA_ "Confidence" SG_ 1342 CP_platformType 0;
BA_ "Confidence" SG_ 1342 CP_appCrc 0;
BA_ "Confidence" SG_ 1342 CP_appGitHash 0;
BA_ "Confidence" SG_ 1342 CP_bootGitHash 0;
BA_ "Confidence" SG_ 1342 CP_bootUdsProtoVersion 0;
BA_ "Confidence" SG_ 1342 CP_bootCrc 0;
BA_ "Confidence" SG_ 1885 CP_loggingFastSelect 1;
BA_ "Confidence" SG_ 1885 CP_inductiveSensor_raw 0;
BA_ "Confidence" SG_ 1885 CP_doorOpenActuationTime 0;
BA_ "Confidence" SG_ 1885 CP_doorCloseActuationTime 0;
BA_ "Confidence" SG_ 1885 CP_chargeCableSecured 0;
BA_ "Confidence" SG_ 1885 CP_chargeCablePresent 0;
BA_ "Confidence" SG_ 1885 CP_latchCheckAvailable 0;
BA_ "Confidence" SG_ 1885 CP_UHF_controlState 0;
BA_ "Confidence" SG_ 1885 CP_proximityV 0;
BA_ "Confidence" SG_ 1885 CP_proximityV_GBCC1 0;
BA_ "Confidence" SG_ 1885 CP_proximityV_GBCC2 0;
BA_ "Confidence" SG_ 1885 CP_doorPot 0;
BA_ "Confidence" SG_ 1885 CP_doorOpenRequest 0;
BA_ "Confidence" SG_ 1885 CP_doorOpenEndOfDriveReason 0;
BA_ "Confidence" SG_ 1885 CP_coverClosed 0;
BA_ "Confidence" SG_ 1885 CP_doorCloseEndOfDriveReason 0;
BA_ "Confidence" SG_ 1885 CP_doorCloseRequest 0;
BA_ "Confidence" SG_ 1885 CP_latchDisengagingTime 0;
BA_ "Confidence" SG_ 1885 CP_latchEngagingTime 0;
BA_ "Confidence" SG_ 1885 CP_latchDisengagingStopReason 0;
BA_ "Confidence" SG_ 1885 CP_latchEngagingStopReason 1;
BA_ "Confidence" SG_ 1885 CP_doorIdDetectionState 0;
BA_ "GenSigSNA" SG_ 1885 CP_doorIdDetectionState "0";
BA_ "Confidence" SG_ 1885 CP_doorIdDetectedBin 0;
BA_ "Confidence" SG_ 989 CP_loggingSlowSelect 1;
BA_ "Confidence" SG_ 989 CP_UHF_chipState 0;
BA_ "Confidence" SG_ 989 CP_UHF_rssi 0;
BA_ "Confidence" SG_ 989 CP_UHF_rxOverflow 0;
BA_ "Confidence" SG_ 989 CP_UHF_rxNumBytes 0;
BA_ "Confidence" SG_ 989 CP_UHF_selfTestRssi 0;
BA_ "Confidence" SG_ 989 CP_latchI 0;
BA_ "Confidence" SG_ 989 CP_inlet1HarnessIdState 0;
BA_ "GenSigSNA" SG_ 989 CP_inlet1HarnessIdState "0";
BA_ "Confidence" SG_ 989 CP_inlet1HarnessIdValue 0;
BA_ "Confidence" SG_ 989 CP_inlet2HarnessIdState 0;
BA_ "GenSigSNA" SG_ 989 CP_inlet2HarnessIdState "0";
BA_ "Confidence" SG_ 989 CP_inlet2HarnessIdValue 0;
BA_ "Confidence" SG_ 989 CP_inletHeaterState 0;
BA_ "Confidence" SG_ 989 CP_inletHeaterDuty 0;
BA_ "Confidence" SG_ 989 CP_nvm_dataValid 0;
BA_ "Confidence" SG_ 989 CP_doorOpenLimiterMaxCount 1;
BA_ "Confidence" SG_ 989 CP_doorOpenLimiterMaxRequestType 1;
BA_ "Confidence" SG_ 989 CP_doorCloseLimiterMaxCount 1;
BA_ "Confidence" SG_ 989 CP_doorCloseLimiterMaxRequestTyp 1;
BA_ "SystemSignalLongSymbol" SG_ 989 CP_doorCloseLimiterMaxRequestTyp "CP_doorCloseLimiterMaxRequestType";
BA_ "Confidence" SG_ 605 CP_type 0;
BA_ "Confidence" SG_ 605 CP_insertEnableLine 0;
BA_ "Confidence" SG_ 605 CP_latchState 0;
BA_ "GenSigSNA" SG_ 605 CP_latchState "0";
BA_ "Confidence" SG_ 605 CP_permanentPowerRequest 0;
BA_ "Confidence" SG_ 605 CP_chargeDoorOpen 0;
BA_ "Confidence" SG_ 605 CP_doorControlState 0;
BA_ "Confidence" SG_ 605 CP_doorButtonPressed 0;
BA_ "Confidence" SG_ 605 CP_swcanRelayClosed 0;
BA_ "Confidence" SG_ 605 CP_inhibitOta 0;
BA_ "Confidence" SG_ 605 CP_chargeCableState 0;
BA_ "GenSigSNA" SG_ 605 CP_chargeCableState "0";
BA_ "Confidence" SG_ 605 CP_latchControlState 0;
BA_ "Confidence" SG_ 605 CP_ledColor 0;
BA_ "Confidence" SG_ 605 CP_UHF_handleFound 0;
BA_ "Confidence" SG_ 605 CP_faultLineSensed 0;
BA_ "Confidence" SG_ 605 CP_doorPresenceState 0;
BA_ "Confidence" SG_ 605 CP_inductiveSensorState 0;
BA_ "Confidence" SG_ 605 CP_chargeDoorOpenUI 0;
BA_ "Confidence" SG_ 605 CP_vehicleUnlockRequest 0;
BA_ "Confidence" SG_ 605 CP_coldWeatherMode 0;
BA_ "Confidence" SG_ 605 CP_inletHeaterUiState 1;
BA_ "Confidence" SG_ 893 CP_thermalStatusSelect 1;
BA_ "Confidence" SG_ 893 CP_pinTemperature1 0;
BA_ "Confidence" SG_ 893 CP_pinTemperature2 0;
BA_ "Confidence" SG_ 893 CP_pinTemperature3 0;
BA_ "Confidence" SG_ 1001 DAS_headlightRequest 0;
BA_ "Confidence" SG_ 1001 DAS_hazardLightRequest 0;
BA_ "GenSigSNA" SG_ 1001 DAS_hazardLightRequest "3";
BA_ "Confidence" SG_ 1001 DAS_wiperSpeed 0;
BA_ "Confidence" SG_ 1001 DAS_turnIndicatorRequest 0;
BA_ "Confidence" SG_ 1001 DAS_highLowBeamDecision 0;
BA_ "GenSigSNA" SG_ 1001 DAS_highLowBeamDecision "3";
BA_ "Confidence" SG_ 1001 DAS_heaterRequest 0;
BA_ "GenSigSNA" SG_ 1001 DAS_heaterRequest "0";
BA_ "Confidence" SG_ 1001 DAS_highLowBeamOffReason 0;
BA_ "GenSigSNA" SG_ 1001 DAS_highLowBeamOffReason "5";
BA_ "Confidence" SG_ 1001 DAS_forwardCamHeaterDutyCycle 0;
BA_ "Confidence" SG_ 1001 DAS_dynamicBrakeLightRequest 0;
BA_ "Confidence" SG_ 1001 DAS_radarHeaterRequest 0;
BA_ "Confidence" SG_ 1001 DAS_ahlbOverride 0;
BA_ "Confidence" SG_ 1001 DAS_mirrorFoldRequest 0;
BA_ "GenSigSNA" SG_ 1001 DAS_mirrorFoldRequest "3";
BA_ "Confidence" SG_ 1001 DAS_wiperWashRequest 0;
BA_ "Confidence" SG_ 1001 DAS_ulcConfirmationRequestActive 0;
BA_ "Confidence" SG_ 1001 DAS_overrideWiperSetting 0;
BA_ "Confidence" SG_ 1001 DAS_autoWiperState 0;
BA_ "GenSigSNA" SG_ 1001 DAS_autoWiperState "5";
BA_ "Confidence" SG_ 1001 DAS_turnIndicatorRequestReason 0;
BA_ "Confidence" SG_ 1001 DAS_forwardRadarPowerRequest 0;
BA_ "Confidence" SG_ 1001 DAS_driverDomeLightRequest 0;
BA_ "Confidence" SG_ 1001 DAS_drivePowerStateRequest 0;
BA_ "Confidence" SG_ 1001 DAS_enableIcrDataCollection 0;
BA_ "Confidence" SG_ 1001 DAS_rPillarCamHeaterDutyCycle 0;
BA_ "Confidence" SG_ 1001 DAS_adaptiveHighBeamIsFaulted 0;
BA_ "Confidence" SG_ 1001 DAS_restrictDoorReleaseLeft 0;
BA_ "Confidence" SG_ 1001 DAS_restrictDoorReleaseRight 0;
BA_ "Confidence" SG_ 1001 DAS_bodyControlsCounter 0;
BA_ "Confidence" SG_ 1001 DAS_bodyControlsChecksum 0;
BA_ "Confidence" SG_ 634 DIF_hvStatusChecksum 0;
BA_ "Confidence" SG_ 634 DIF_hvStatusCounter 0;
BA_ "Confidence" SG_ 634 DIF_hvilCurrent 0;
BA_ "Confidence" SG_ 634 DIF_hvilCmVoltage 0;
BA_ "Confidence" SG_ 634 DIF_hvilStatus 0;
BA_ "GenSigSNA" SG_ 634 DIF_hvilStatus "3";
BA_ "Confidence" SG_ 634 DIF_hvilSupplyState 0;
BA_ "Confidence" SG_ 634 DIF_activeDischargeCtrl 0;
BA_ "Confidence" SG_ 634 DIF_activeDischargeStatus 0;
BA_ "Confidence" SG_ 634 DIF_vBat 0;
BA_ "Confidence" SG_ 634 DIF_vBatQF 0;
BA_ "Confidence" SG_ 634 DIF_powerStageSafeState 0;
BA_ "Confidence" SG_ 634 DIF_fluxState 0;
BA_ "Confidence" SG_ 634 DIF_vBusDiag 0;
BA_ "Confidence" SG_ 634 DIF_gateDriveState 0;
BA_ "Confidence" SG_ 741 DIF_elecPower 0;
BA_ "GenSigSNA" SG_ 741 DIF_elecPower "1024";
BA_ "Confidence" SG_ 741 DIF_heatPowerOptimal 0;
BA_ "Confidence" SG_ 741 DIF_heatPowerMax 0;
BA_ "Confidence" SG_ 741 DIF_heatPowerActual 0;
BA_ "Confidence" SG_ 741 DIF_excessHeatCommand 0;
BA_ "Confidence" SG_ 741 DIF_drivePowerMax 0;
BA_ "GenSigSNA" SG_ 741 DIF_drivePowerMax "511";
BA_ "Confidence" SG_ 886 DIF_tempIndex 1;
BA_ "Confidence" SG_ 886 DIF_inverterTQF 0;
BA_ "Confidence" SG_ 886 DIF_pcbT 0;
BA_ "GenSigSNA" SG_ 886 DIF_pcbT "0";
BA_ "Confidence" SG_ 886 DIF_inverterT 0;
BA_ "Confidence" SG_ 886 DIF_statorT 0;
BA_ "GenSigSNA" SG_ 886 DIF_statorT "0";
BA_ "Confidence" SG_ 886 DIF_dcCapT 0;
BA_ "GenSigSNA" SG_ 886 DIF_dcCapT "0";
BA_ "Confidence" SG_ 886 DIF_heatsinkT 0;
BA_ "GenSigSNA" SG_ 886 DIF_heatsinkT "0";
BA_ "Confidence" SG_ 886 DIF_inverterTpct 0;
BA_ "Confidence" SG_ 886 DIF_statorTpct 0;
BA_ "Confidence" SG_ 886 DIF_fluidInTemp 0;
BA_ "GenSigSNA" SG_ 886 DIF_fluidInTemp "0";
BA_ "Confidence" SG_ 886 DIF_normalFetBurnIn 0;
BA_ "GenSigSNA" SG_ 886 DIF_normalFetBurnIn "65535";
BA_ "Confidence" SG_ 886 DIF_additionalFetBurnIn 0;
BA_ "GenSigSNA" SG_ 886 DIF_additionalFetBurnIn "65535";
BA_ "Confidence" SG_ 886 DIF_currentWeibullMiles 0;
BA_ "GenSigSNA" SG_ 886 DIF_currentWeibullMiles "32767";
BA_ "Confidence" SG_ 886 DIF_endOfServiceWeibullMiles 0;
BA_ "GenSigSNA" SG_ 886 DIF_endOfServiceWeibullMiles "32767";
BA_ "Confidence" SG_ 886 DIF_burnInDamageRatio 0;
BA_ "GenSigSNA" SG_ 886 DIF_burnInDamageRatio "511";
BA_ "Confidence" SG_ 886 DIF_inverterSensorEst 0;
BA_ "Confidence" SG_ 886 DIF_inverterHS1Est 0;
BA_ "Confidence" SG_ 886 DIF_initialBurnInVehicleOdometer 0;
BA_ "GenSigSNA" SG_ 886 DIF_initialBurnInVehicleOdometer "4294967295";
BA_ "Confidence" SG_ 886 DIF_inverterHS2Est 0;
BA_ "Confidence" SG_ 886 DIF_inverterInletEst 0;
BA_ "Confidence" SG_ 1367 DIF_passiveInletTempReq 0;
BA_ "Confidence" SG_ 1367 DIF_activeInletTempReq 0;
BA_ "Confidence" SG_ 1367 DIF_coolantFlowReq 0;
BA_ "Confidence" SG_ 1367 DIF_oilFlowReq 0;
BA_ "GenSigSNA" SG_ 1367 DIF_oilFlowReq "255";
BA_ "Confidence" SG_ 1367 DIF_criticalFlowReq 0;
BA_ "Confidence" SG_ 1367 DIF_burnInStatus 0;
BA_ "Confidence" SG_ 2005 DIR_debugSelector 1;
BA_ "Confidence" SG_ 2005 DIR_phaseOutBusbarTemp 0;
BA_ "GenSigSNA" SG_ 2005 DIR_phaseOutBusbarTemp "0";
BA_ "Confidence" SG_ 2005 DIR_phaseOutBusbarWeldTemp 0;
BA_ "GenSigSNA" SG_ 2005 DIR_phaseOutBusbarWeldTemp "0";
BA_ "Confidence" SG_ 2005 DIR_phaseOutLugTemp 0;
BA_ "GenSigSNA" SG_ 2005 DIR_phaseOutLugTemp "0";
BA_ "Confidence" SG_ 2005 DIR_dcLinkCapTemp 0;
BA_ "GenSigSNA" SG_ 2005 DIR_dcLinkCapTemp "0";
BA_ "Confidence" SG_ 2005 DIR_hvDcCableTemp 0;
BA_ "GenSigSNA" SG_ 2005 DIR_hvDcCableTemp "0";
BA_ "Confidence" SG_ 2005 DIR_negDcBusbarTemp 0;
BA_ "GenSigSNA" SG_ 2005 DIR_negDcBusbarTemp "0";
BA_ "Confidence" SG_ 2005 DIR_posDcBusbarTemp 0;
BA_ "GenSigSNA" SG_ 2005 DIR_posDcBusbarTemp "0";
BA_ "Confidence" SG_ 2005 DIR_statorEndWindingTemp 0;
BA_ "GenSigSNA" SG_ 2005 DIR_statorEndWindingTemp "0";
BA_ "Confidence" SG_ 2005 DIR_rotorMaxMagnetTemp 0;
BA_ "GenSigSNA" SG_ 2005 DIR_rotorMaxMagnetTemp "0";
BA_ "Confidence" SG_ 2005 DIR_lightSenseV 0;
BA_ "Confidence" SG_ 2005 DIR_pyroSenseV 0;
BA_ "Confidence" SG_ 2005 DIR_statorSlotWindingTemp 0;
BA_ "GenSigSNA" SG_ 2005 DIR_statorSlotWindingTemp "0";
BA_ "Confidence" SG_ 2005 DIR_intervalMaxHvBusV 0;
BA_ "Confidence" SG_ 633 DIR_hvStatusChecksum 0;
BA_ "Confidence" SG_ 633 DIR_hvStatusCounter 0;
BA_ "Confidence" SG_ 633 DIR_hvilCurrent 0;
BA_ "Confidence" SG_ 633 DIR_hvilCmVoltage 0;
BA_ "Confidence" SG_ 633 DIR_hvilStatus 0;
BA_ "GenSigSNA" SG_ 633 DIR_hvilStatus "3";
BA_ "Confidence" SG_ 633 DIR_hvilSupplyState 0;
BA_ "Confidence" SG_ 633 DIR_activeDischargeCtrl 0;
BA_ "Confidence" SG_ 633 DIR_activeDischargeStatus 0;
BA_ "Confidence" SG_ 633 DIR_vBat 0;
BA_ "Confidence" SG_ 633 DIR_vBatQF 0;
BA_ "Confidence" SG_ 633 DIR_powerStageSafeState 0;
BA_ "Confidence" SG_ 633 DIR_fluxState 0;
BA_ "Confidence" SG_ 633 DIR_vBusDiag 0;
BA_ "Confidence" SG_ 633 DIR_gateDriveState 0;
BA_ "Confidence" SG_ 821 DIR_infoIndex 1;
BA_ "Confidence" SG_ 821 DIR_buildType 0;
BA_ "Confidence" SG_ 821 DIR_buildConfigurationId 0;
BA_ "Confidence" SG_ 821 DIR_hardwareId 0;
BA_ "Confidence" SG_ 821 DIR_componentId 0;
BA_ "Confidence" SG_ 821 DIR_pcbaId 0;
BA_ "Confidence" SG_ 821 DIR_assemblyId 0;
BA_ "Confidence" SG_ 821 DIR_usageId 0;
BA_ "Confidence" SG_ 821 DIR_subUsageId 0;
BA_ "Confidence" SG_ 821 DIR_motorType 1;
BA_ "GenSigSNA" SG_ 821 DIR_motorType "0";
BA_ "Confidence" SG_ 821 DIR_siliconType 0;
BA_ "Confidence" SG_ 821 DIR_mechSafeStateType 0;
BA_ "GenSigSNA" SG_ 821 DIR_mechSafeStateType "0";
BA_ "Confidence" SG_ 821 DIR_applicationCrc 0;
BA_ "Confidence" SG_ 821 DIR_oilPumpBuildType 0;
BA_ "Confidence" SG_ 821 DIR_oilPumpAppCrc 0;
BA_ "Confidence" SG_ 821 DIR_FPGA_version 0;
BA_ "GenSigSNA" SG_ 821 DIR_FPGA_version "255";
BA_ "Confidence" SG_ 821 DIR_bootGitHash 0;
BA_ "Confidence" SG_ 821 DIR_infoBootLdUdsProtocolVersion 0;
BA_ "Confidence" SG_ 821 DIR_bootloaderCrc 0;
BA_ "Confidence" SG_ 821 DIR_oilPumpPcbaId 0;
BA_ "Confidence" SG_ 821 DIR_oilPumpAssemblyId 0;
BA_ "Confidence" SG_ 821 DIR_oilPumpUsageId 0;
BA_ "Confidence" SG_ 821 DIR_refRotorFlux 0;
BA_ "Confidence" SG_ 821 DIR_refRotorOffset 0;
BA_ "GenSigSNA" SG_ 821 DIR_refRotorOffset "2048";
BA_ "Confidence" SG_ 821 DIR_speedWearTotal 0;
BA_ "GenSigSNA" SG_ 821 DIR_speedWearTotal "255";
BA_ "Confidence" SG_ 821 DIR_torqueWearTotal 0;
BA_ "GenSigSNA" SG_ 821 DIR_torqueWearTotal "255";
BA_ "Confidence" SG_ 917 DIR_oilPumpState 0;
BA_ "GenSigSNA" SG_ 917 DIR_oilPumpState "7";
BA_ "Confidence" SG_ 917 DIR_oilPumpFluidTQF 0;
BA_ "Confidence" SG_ 917 DIR_oilPumpLeadAngle 0;
BA_ "Confidence" SG_ 917 DIR_oilPumpFlowTarget 0;
BA_ "GenSigSNA" SG_ 917 DIR_oilPumpFlowTarget "255";
BA_ "Confidence" SG_ 917 DIR_oilPumpFlowActual 0;
BA_ "GenSigSNA" SG_ 917 DIR_oilPumpFlowActual "255";
BA_ "Confidence" SG_ 917 DIR_oilPumpFluidT 0;
BA_ "GenSigSNA" SG_ 917 DIR_oilPumpFluidT "255";
BA_ "Confidence" SG_ 917 DIR_oilPumpPhaseCurrent 0;
BA_ "GenSigSNA" SG_ 917 DIR_oilPumpPhaseCurrent "255";
BA_ "Confidence" SG_ 917 DIR_oilPumpPressureEstimate 0;
BA_ "GenSigSNA" SG_ 917 DIR_oilPumpPressureEstimate "255";
BA_ "Confidence" SG_ 917 DIR_oilPumpPressureExpected 0;
BA_ "GenSigSNA" SG_ 917 DIR_oilPumpPressureExpected "255";
BA_ "Confidence" SG_ 917 DIR_oilPumpPressureResidual 0;
BA_ "GenSigSNA" SG_ 917 DIR_oilPumpPressureResidual "255";
BA_ "Confidence" SG_ 614 DIR_elecPower 0;
BA_ "GenSigSNA" SG_ 614 DIR_elecPower "1024";
BA_ "Confidence" SG_ 614 DIR_heatPowerOptimal 0;
BA_ "Confidence" SG_ 614 DIR_heatPowerMax 0;
BA_ "Confidence" SG_ 614 DIR_heatPowerActual 0;
BA_ "Confidence" SG_ 614 DIR_excessHeatCommand 0;
BA_ "Confidence" SG_ 614 DIR_drivePowerMax 0;
BA_ "GenSigSNA" SG_ 614 DIR_drivePowerMax "511";
BA_ "Confidence" SG_ 789 DIR_tempIndex 1;
BA_ "Confidence" SG_ 789 DIR_inverterTQF 0;
BA_ "Confidence" SG_ 789 DIR_pcbT 0;
BA_ "GenSigSNA" SG_ 789 DIR_pcbT "0";
BA_ "Confidence" SG_ 789 DIR_inverterT 0;
BA_ "Confidence" SG_ 789 DIR_statorT 0;
BA_ "GenSigSNA" SG_ 789 DIR_statorT "0";
BA_ "Confidence" SG_ 789 DIR_dcCapT 0;
BA_ "GenSigSNA" SG_ 789 DIR_dcCapT "0";
BA_ "Confidence" SG_ 789 DIR_heatsinkT 0;
BA_ "GenSigSNA" SG_ 789 DIR_heatsinkT "0";
BA_ "Confidence" SG_ 789 DIR_inverterTpct 0;
BA_ "Confidence" SG_ 789 DIR_statorTpct 0;
BA_ "Confidence" SG_ 789 DIR_fluidInTemp 0;
BA_ "GenSigSNA" SG_ 789 DIR_fluidInTemp "0";
BA_ "Confidence" SG_ 789 DIR_normalFetBurnIn 0;
BA_ "GenSigSNA" SG_ 789 DIR_normalFetBurnIn "65535";
BA_ "Confidence" SG_ 789 DIR_additionalFetBurnIn 0;
BA_ "GenSigSNA" SG_ 789 DIR_additionalFetBurnIn "65535";
BA_ "Confidence" SG_ 789 DIR_currentWeibullMiles 0;
BA_ "GenSigSNA" SG_ 789 DIR_currentWeibullMiles "32767";
BA_ "Confidence" SG_ 789 DIR_endOfServiceWeibullMiles 0;
BA_ "GenSigSNA" SG_ 789 DIR_endOfServiceWeibullMiles "32767";
BA_ "Confidence" SG_ 789 DIR_burnInDamageRatio 0;
BA_ "GenSigSNA" SG_ 789 DIR_burnInDamageRatio "511";
BA_ "Confidence" SG_ 789 DIR_inverterSensorEst 0;
BA_ "Confidence" SG_ 789 DIR_inverterHS1Est 0;
BA_ "Confidence" SG_ 789 DIR_initialBurnInVehicleOdometer 0;
BA_ "GenSigSNA" SG_ 789 DIR_initialBurnInVehicleOdometer "4294967295";
BA_ "Confidence" SG_ 789 DIR_inverterHS2Est 0;
BA_ "Confidence" SG_ 789 DIR_inverterInletEst 0;
BA_ "Confidence" SG_ 1495 DIR_passiveInletTempReq 0;
BA_ "Confidence" SG_ 1495 DIR_activeInletTempReq 0;
BA_ "Confidence" SG_ 1495 DIR_coolantFlowReq 0;
BA_ "Confidence" SG_ 1495 DIR_oilFlowReq 0;
BA_ "GenSigSNA" SG_ 1495 DIR_oilFlowReq "255";
BA_ "Confidence" SG_ 1495 DIR_criticalFlowReq 0;
BA_ "Confidence" SG_ 1495 DIR_burnInStatus 0;
VAL_ 909 APP_inTunnel 2 "NOT_IN_TUNNEL" 1 "IN_TUNNEL" 0 "IN_TUNNEL_SNA" ;
VAL_ 909 APP_windshieldHeaterOnReason 7 "WINDSHIELD_HEATER_ON_REASON_HVAC_REQUESTED" 6 "WINDSHIELD_HEATER_ON_REASON_OVERRIDE" 5 "WINDSHIELD_HEATER_ON_REASON_OFF" 4 "WINDSHIELD_HEATER_ON_REASON_STARTUP" 3 "WINDSHIELD_HEATER_ON_REASON_CONDENSATION_LIKELY" 2 "WINDSHIELD_HEATER_ON_REASON_OCCLUDED" 1 "WINDSHIELD_HEATER_ON_REASON_DEFROST" 0 "WINDSHIELD_HEATER_ON_REASON_SNA" ;
VAL_ 909 APP_selfieCameraBlocked 2 "SELFIE_CAMERA_BLOCKED" 1 "SELFIE_CAMERA_NOT_BLOCKED" 0 "SELFIE_CAMERA_BLOCKED_SNA" ;
VAL_ 909 APP_selfieCameraLUX 255 "SNA" 254 "SATURATED" ;
VAL_ 909 APP_sceneTagClearlyRaining 2 "NOT_ACTIVATED" 1 "ACTIVATED" 0 "SNA" ;
VAL_ 909 APP_sceneTagFog 2 "NOT_ACTIVATED" 1 "ACTIVATED" 0 "SNA" ;
VAL_ 909 APP_sceneTagFullyBlocked 2 "NOT_ACTIVATED" 1 "ACTIVATED" 0 "SNA" ;
VAL_ 909 APP_sceneTagIndoors 2 "NOT_ACTIVATED" 1 "ACTIVATED" 0 "SNA" ;
VAL_ 909 APP_sceneTagLensFlare 2 "NOT_ACTIVATED" 1 "ACTIVATED" 0 "SNA" ;
VAL_ 909 APP_sceneTagRaining 2 "NOT_ACTIVATED" 1 "ACTIVATED" 0 "SNA" ;
VAL_ 909 APP_sceneTagSevereWeather 2 "NOT_ACTIVATED" 1 "ACTIVATED" 0 "SNA" ;
VAL_ 909 APP_sceneTagSnowing 2 "NOT_ACTIVATED" 1 "ACTIVATED" 0 "SNA" ;
VAL_ 909 APP_sceneTagSnowyRoad 2 "NOT_ACTIVATED" 1 "ACTIVATED" 0 "SNA" ;
VAL_ 909 APP_sceneTagSunGlare 2 "NOT_ACTIVATED" 1 "ACTIVATED" 0 "SNA" ;
VAL_ 909 APP_sceneTagTunnel 2 "NOT_ACTIVATED" 1 "ACTIVATED" 0 "SNA" ;
VAL_ 909 APP_sceneTagWetRoad 2 "NOT_ACTIVATED" 1 "ACTIVATED" 0 "SNA" ;
VAL_ 909 APP_fisheyeInPathVisibility 4 "VISIBILITY_CONDITION_NOMINAL" 3 "VISIBILITY_OCCLUDED_LOW_SEVERITY" 2 "VISIBILITY_OCCLUDED_MEDIUM_SEVERITY" 1 "VISIBILITY_OCCLUDED_HIGH_SEVERITY" 0 "VISIBILITY_CONDITION_SNA" ;
VAL_ 909 APP_fisheyeOverallVisibility 4 "VISIBILITY_CONDITION_NOMINAL" 3 "VISIBILITY_OCCLUDED_LOW_SEVERITY" 2 "VISIBILITY_OCCLUDED_MEDIUM_SEVERITY" 1 "VISIBILITY_OCCLUDED_HIGH_SEVERITY" 0 "VISIBILITY_CONDITION_SNA" ;
VAL_ 909 APP_mainInPathVisibility 4 "VISIBILITY_CONDITION_NOMINAL" 3 "VISIBILITY_OCCLUDED_LOW_SEVERITY" 2 "VISIBILITY_OCCLUDED_MEDIUM_SEVERITY" 1 "VISIBILITY_OCCLUDED_HIGH_SEVERITY" 0 "VISIBILITY_CONDITION_SNA" ;
VAL_ 909 APP_mainOverallVisibility 4 "VISIBILITY_CONDITION_NOMINAL" 3 "VISIBILITY_OCCLUDED_LOW_SEVERITY" 2 "VISIBILITY_OCCLUDED_MEDIUM_SEVERITY" 1 "VISIBILITY_OCCLUDED_HIGH_SEVERITY" 0 "VISIBILITY_CONDITION_SNA" ;
VAL_ 909 APP_narrowInPathVisibility 4 "VISIBILITY_CONDITION_NOMINAL" 3 "VISIBILITY_OCCLUDED_LOW_SEVERITY" 2 "VISIBILITY_OCCLUDED_MEDIUM_SEVERITY" 1 "VISIBILITY_OCCLUDED_HIGH_SEVERITY" 0 "VISIBILITY_CONDITION_SNA" ;
VAL_ 909 APP_narrowOverallVisibility 4 "VISIBILITY_CONDITION_NOMINAL" 3 "VISIBILITY_OCCLUDED_LOW_SEVERITY" 2 "VISIBILITY_OCCLUDED_MEDIUM_SEVERITY" 1 "VISIBILITY_OCCLUDED_HIGH_SEVERITY" 0 "VISIBILITY_CONDITION_SNA" ;
VAL_ 909 APP_frontCamOcclusionType 6 "UNKNOWN_OCCLUSION" 5 "DEW" 4 "STREAK" 3 "SUN_GLARE" 2 "DIRTY_OR_BLOCKED" 1 "CONDENSATION" 0 "OFFGASSING" ;
VAL_ 818 BMS_bmbMinMaxMultiplexer 2 "END" 1 "VOLT_MUX1" 0 "THERM_MUX0" ;
VAL_ 1138 BMS_chargeCurrentLimitMode 20 "CHG_LIMIT_RIPPLE_HEAT_ACTIVE" 19 "CHG_LIMIT_NEAR_HWOT_LIMIT" 18 "CHG_LIMIT_LIMP_MODE" 17 "CHG_LIMIT_MISSING_CELL" 16 "CHG_LIMIT_CAC_IMBALANCE" 15 "CHG_LIMIT_PCS_IMPLICIT" 14 "CHG_LIMIT_EVSE_IMPLICIT" 13 "CHG_LIMIT_RAMP_UP_PHASE" 12 "CHG_LIMIT_HVAC_COOLING" 11 "CHG_LIMIT_HV_CHAIN" 10 "CHG_LIMIT_CONFIG" 9 "CHG_LIMIT_TETHERING" 8 "CHG_LIMIT_LEAKY_BUCKET" 7 "CHG_LIMIT_BRICK_VOLTAGE_REG" 6 "CHG_LIMIT_BRICK_TEMP_TOO_COLD" 5 "CHG_LIMIT_BRICK_TEMP_TOO_HOT" 4 "CHG_LIMIT_BRICK_TEMP_OPTIMAL_CELL_PROFILE" 3 "CHG_LIMIT_CP" 2 "CHG_LIMIT_PCS" 1 "CHG_LIMIT_EVSE" 0 "CHG_LIMIT_NONE" ;
VAL_ 1138 BMS_timeToFinishHeatForCharge 127 "SNA" 126 "CALCULATING" ;
VAL_ 1138 BMS_diNodeModelTemp 2047 "SNA" ;
VAL_ 850 BMS_energyStatusMultiplexer 2 "Mux2" 1 "Mux1" 0 "Mux0" ;
VAL_ 850 BMS_nominalFullPackEnergy 65535 "SNA" ;
VAL_ 850 BMS_nominalEnergyRemaining 65535 "SNA" ;
VAL_ 850 BMS_idealEnergyRemaining 65535 "SNA" ;
VAL_ 850 BMS_energyBuffer 65535 "SNA" ;
VAL_ 850 BMS_expectedEnergyRemaining 65535 "SNA" ;
VAL_ 850 BMS_energyToChargeComplete 65535 "SNA" ;
VAL_ 850 BMS_energyRemainingDisplay 65535 "SNA" ;
VAL_ 850 BMS_energyRemainingTDisplay 65535 "SNA" ;
VAL_ 850 BMS_userFacingSoe 2047 "SNA" ;
VAL_ 306 BMS_packCurrent -32768 "SNA" ;
VAL_ 306 BMS_currentUnfiltered -32768 "SNA" ;
VAL_ 306 BMS_chgTimeToFull 4095 "SNA" ;
VAL_ 768 BMS_infoIndex 255 "END" 31 "SUBCOMPONENT_GITHASH" 30 "PACKAGE_SN_8_14" 29 "PACKAGE_SN_1_7" 27 "PACKAGE_PN_15_20" 26 "PACKAGE_PN_8_14" 25 "PACKAGE_PN_1_7" 23 "SUBCOMPONENT2" 22 "VARIANTCRC" 20 "UDS_PROTOCOL_BOOTCRC" 19 "VERSION_DEPRECATED" 18 "BOOTLOADER_GITHASH" 17 "APP_GITHASH" 16 "SUBCOMPONENT" 15 "BOOTLOADER_CRC" 14 "BOOTLOADER_SVN" 13 "APP_CRC" 11 "PCBAID_ASSYID_USAGEID" 10 "BUILD_HWID_COMPONENTID" 9 "DEPRECATED_9" 8 "DEPRECATED_8" 7 "DEPRECATED_7" 6 "DEPRECATED_6" 5 "DEPRECATED_5" 4 "DEPRECATED_4" 3 "DEPRECATED_3" 2 "DEPRECATED_2" 1 "DEPRECATED_1" 0 "DEPRECATED_0" ;
VAL_ 768 BMS_buildType 4 "INFO_MFG_BUILD" 3 "INFO_TRACEABLE_CI_BUILD" 2 "INFO_LOCAL_BUILD" 1 "INFO_PLATFORM_BUILD" 0 "INFO_UNKNOWN_BUILD" ;
VAL_ 1010 BMS_kwhCounter_Id 14 "END" 13 "MUX13" 12 "MUX12" 11 "MUX11" 10 "MUX10" 9 "MUX9" 8 "MUX8" 7 "MUX7" 6 "MUX6" 5 "MUX5" 4 "MUX4" 3 "MUX3" 2 "MUX2" 1 "MUX1" 0 "MUX0" ;
VAL_ 882 BMS_log1MuxId 27 "SLEEP_CURRENT_2" 26 "SLEEP_CURRENT_1" 25 "CHARGE_LIMIT_2" 24 "CHARGE_LIMIT_1" 23 "CHARGE_ENERGY_4" 22 "CHARGE_ENERGY_3" 21 "CHARGE_ENERGY_2" 20 "CHARGE_ENERGY_1" 19 "PACK_DATA" 18 "IMPEDANCE_DEVIATION_2" 17 "IMPEDANCE_DEVIATION_1" 16 "SOC_BY_DELTA_V_2" 15 "SOC_BY_DELTA_V_1" 14 "CHARGE_REGULATION" 13 "CHARGE_TERMINATION" 12 "BANDOLIER_MODEL_THERMISTOR_TEMPS_2" 11 "BANDOLIER_MODEL_THERMISTOR_TEMPS_1" 10 "BANDOLIER_MODEL_PACK_TEMPS" 9 "CHARGE_INTERFACE_2" 8 "CHARGE_INTERFACE_1" 7 "NEG_CTR_HEALTH_2" 6 "NEG_CTR_HEALTH_1" 5 "POS_CTR_HEALTH_2" 4 "POS_CTR_HEALTH_1" 3 "STATES_AND_BOOLS" 2 "CPU_USAGE3" 1 "CPU_USAGE2" 0 "CPU_USAGE1" ;
VAL_ 946 BMS_log2MuxId 83 "MUX_83" 82 "MUX_82" 81 "MUX_81" 80 "MUX_80" 79 "MUX_79" 78 "MUX_78" 77 "MUX_77" 76 "MUX_76" 75 "MUX_75" 74 "MUX_74" 73 "MUX_73" 72 "MUX_72" 71 "MUX_71" 70 "MUX_70" 69 "MUX_69" 68 "MUX_68" 67 "MUX_67" 66 "MUX_66" 65 "MUX_65" 64 "MUX_64" 63 "MUX_63" 62 "MUX_62" 61 "MUX_61" 60 "MUX_60" 59 "MUX_59" 58 "MUX_58" 57 "MUX_57" 56 "MUX_56" 55 "LIFE_MODEL_HIST_SUMMARY_DATA" 54 "LIFE_MODEL_STORAGE_HIST_DATA" 53 "SPME_MAX_SOC_BRICK_DATA" 52 "SPME_MIN_SOC_BRICK_DATA" 51 "SPME_DATA_3" 50 "SPME_BRICK_1_DATA_2" 49 "SPME_BRICK_1_DATA_1" 48 "SPME_PACK_LEVEL" 47 "BRICK_BLEED_TIMES_5" 46 "HISTOGRAMS_SUMMARY" 45 "SOH" 44 "CAC4" 43 "ISOLATION" 42 "BRICK_BLEED_TIMES_4" 41 "BRICK_BLEED_TIMES_3" 40 "BRICK_BLEED_TIMES_2" 39 "BRICK_BLEED_TIMES_1" 38 "LIFE_MODEL" 37 "BRICK_BALANCE_4" 36 "BRICK_BALANCE_3" 35 "BRICK_BALANCE_2" 34 "BRICK_BALANCE_1" 33 "ALPHA_1" 32 "HISTOGRAMS_4" 31 "HISTOGRAMS_3" 30 "HISTOGRAMS_2" 29 "HISTOGRAMS_1" 28 "HISTOGRAMS_0" 27 "VSH_RES_3" 26 "VSH_RES_2" 25 "VSH_RES_1" 24 "SOC_BY_OCV_CORRECTION" 23 "BRICK_VOLTAGE_CHANGE" 22 "CAC3" 21 "ENERGY_AND_REST_DATA" 20 "FC_LINK_LEAKAGE_TEST" 19 "ENERGY_RESERVE" 18 "HV_CHAIN_MODEL" 17 "NEG_CTR_HEALTH_4" 16 "NEG_CTR_HEALTH_3" 15 "NEG_CTR_HEALTH_2" 14 "NEG_CTR_HEALTH_1" 13 "POS_CTR_HEALTH_4" 12 "POS_CTR_HEALTH_3" 11 "POS_CTR_HEALTH_2" 10 "POS_CTR_HEALTH_1" 9 "CTR_RESISTANCE" 8 "100HZ_1KHZ_TASK_STATS" 7 "10HZ_TASK_STATS" 6 "1HZ_TASK_STATS" 5 "AHR_COUNTER" 4 "CHARGING" 3 "VSH_TEST" 2 "FLOOD_PORT" 1 "CAC2" 0 "CAC1" ;
VAL_ 946 BMS_hvChain_iLimit 16383 "SNA" ;
VAL_ 946 BMS_hvChain_limitingState 511 "SNA" ;
VAL_ 946 BMS_hvChain_limitingStateTempera -4096 "SNA" ;
VAL_ 946 BMS_fcLinkTestDecayTime 1023 "SNA" ;
VAL_ 946 BMS_idealEnergyFloor 1023 "SNA" ;
VAL_ 946 BMS_dynamicEnergyBuffer 1023 "SNA" ;
VAL_ 946 BMS_dSocNormalizedMin 4095 "SNA" ;
VAL_ 946 BMS_dSocNormalizedFiltMin 4095 "SNA" ;
VAL_ 946 BMS_dSocMinAlpha 4095 "SNA" ;
VAL_ 946 BMS_dSocCacMargin 511 "SNA" ;
VAL_ 946 BMS_lifeModelAvgTempSeverity 31 "SNA" ;
VAL_ 946 BMS_lifeModelDepthOfDischargeSev 255 "SNA" ;
VAL_ 946 BMS_lifeModelHistogramCapacityLo 511 "SNA" ;
VAL_ 946 BMS_lifeModelHistogramBrickCapac 8191 "SNA" ;
VAL_ 946 BMS_lifeModelDcrGrowthPercent -8192 "SNA" ;
VAL_ 946 BMS_nominalFullPackEnergyRaw 65535 "SNA" ;
VAL_ 946 BMS_userChargeCalibratingReason 2 "USR_CHG_CALIBRATING_RUBBER_BANDING_HOLD" 1 "USR_CHG_CALIBRATING_FULL_CHARGE" 0 "USR_CHG_CALIBRATING_INACTIVE" ;
VAL_ 946 BMS_nominalEnergyRemainingBuffer 65535 "SNA" ;
VAL_ 946 BMS_idealEnergyRemainingBuffered 65535 "SNA" ;
VAL_ 946 BMS_largestCacSpreadErrorLower 4095 "SNA" ;
VAL_ 946 BMS_lifeModelAverageCac 4095 "SNA" ;
VAL_ 946 BMS_lifeModelCacBrick1 4095 "SNA" ;
VAL_ 946 BMS_lifeModelAverageOffset -512 "SNA" ;
VAL_ 946 BMS_lifeModelMaxCacBrickId 255 "SNA" ;
VAL_ 946 BMS_lifeModelMaxCac 4095 "SNA" ;
VAL_ 946 BMS_lifeModelMinCacBrickId 255 "SNA" ;
VAL_ 946 BMS_lifeModelMinCac 4095 "SNA" ;
VAL_ 946 BMS_restingPointCacAvg 4095 "SNA" ;
VAL_ 946 BMS_cacEstimationSource 2 "CAC_SOURCE_LIFE_MODEL" 1 "CAC_SOURCE_RESTING_POINT_CAC" 0 "CAC_SOURCE_UNKNOWN" ;
VAL_ 946 BMS_synchronizedCacMaxRaw 4095 "SNA" ;
VAL_ 946 BMS_synchronizedCacMinRaw 4095 "SNA" ;
VAL_ 946 BMS_sohEnergy 2047 "SNA" ;
VAL_ 946 BMS_fullCapacitySohEnergy 2047 "SNA" ;
VAL_ 946 BMS_calibratedCapacitySohEnergy 2047 "SNA" ;
VAL_ 946 BMS_estimatedCapacitySohEnergy 2047 "SNA" ;
VAL_ 946 BMS_prevUserFacingSohEnergy 2047 "SNA" ;
VAL_ 946 BMS_stateOfHealthMinCac 8191 "SNA" ;
VAL_ 946 BMS_lifeModelStorageLossPackAge 16383 "SNA" ;
VAL_ 946 BMS_lifeModelThroughputCycleCoun 4095 "SNA" ;
VAL_ 946 BMS_lifeModelThroughputDcrCycleC 4095 "SNA" ;
VAL_ 946 BMS_stateOfHealth 1023 "SNA" ;
VAL_ 914 BMS_packConfigMultiplexer 1 "Mux1" 0 "Mux0" ;
VAL_ 914 BMS_reservedConfig_0 31 "BMS_CONFIG_31" 30 "BMS_CONFIG_30" 29 "BMS_CONFIG_29" 28 "BMS_CONFIG_28" 27 "BMS_CONFIG_27" 26 "BMS_CONFIG_26" 25 "BMS_CONFIG_25" 24 "BMS_CONFIG_24" 23 "BMS_CONFIG_23" 22 "BMS_CONFIG_22" 21 "BMS_CONFIG_21" 20 "BMS_CONFIG_20" 19 "BMS_CONFIG_19" 18 "BMS_CONFIG_18" 17 "BMS_CONFIG_17" 16 "BMS_CONFIG_16" 15 "BMS_CONFIG_15" 14 "BMS_CONFIG_14" 13 "BMS_CONFIG_13" 12 "BMS_CONFIG_12" 11 "BMS_CONFIG_11" 10 "BMS_CONFIG_10" 9 "BMS_CONFIG_9" 8 "BMS_CONFIG_8" 7 "BMS_CONFIG_7" 6 "BMS_CONFIG_6" 5 "BMS_CONFIG_5" 4 "BMS_CONFIG_4" 3 "BMS_CONFIG_3" 2 "BMS_CONFIG_2" 1 "BMS_CONFIG_1" 0 "BMS_CONFIG_0" ;
VAL_ 914 BMS_moduleType 5 "BMS_MOD_TYPE_5" 4 "BMS_MOD_TYPE_4" 3 "BMS_MOD_TYPE_3" 2 "BMS_MOD_TYPE_2" 1 "BMS_MOD_TYPE_1" 0 "BMS_MOD_TYPE_UNKNOWN" ;
VAL_ 914 BMS_thermalPackType 9 "E3D_40P" 8 "E3D" 7 "BLADERUNNER_E1" 6 "BFF00S" 5 "P2" 4 "BFF00_E1" 3 "CATL_E1" 2 "E3" 1 "E1" 0 "UNKNOWN" ;
VAL_ 914 BMS_standbySupplyContinuousPower 3 "17W" 2 "16W" 1 "4W" 0 "0W" ;
VAL_ 594 BMS_powerLimitsState 1 "POWER_CALCULATED_FOR_DRIVE" 0 "POWER_NOT_CALCULATED_FOR_DRIVE" ;
VAL_ 594 BMS_instantChargePowerCapability 65535 "SNA" ;
VAL_ 674 BMS_acRippleFrequencyRequest 63 "SNA" ;
VAL_ 674 BMS_acRippleRequest 4 "RIPPLE_FAULTED" 3 "RIPPLE_ON" 2 "RIPPLE_STANDBY" 1 "RIPPLE_OFF" 0 "RIPPLE_NOT_SUPPORTED" ;
VAL_ 658 BMS_beginningOfLifePackEnergy 1023 "SNA" ;
VAL_ 658 BMS_battTempPct 255 "SNA" ;
VAL_ 658 BMS_userChargeCurrentLimitMode 4 "USR_CHG_LIMIT_EVSE_RELOCATION_RECOMMENDED" 3 "USR_CHG_LIMIT_HIGH_SOC" 2 "USR_CHG_LIMIT_BATT_TEMP_LOW" 1 "USR_CHG_LIMIT_EVSE" 0 "USR_CHG_LIMIT_NONE" ;
VAL_ 1170 BMS_sohEnergyPercent 1023 "SNA" ;
VAL_ 1170 BMS_userFacingSohTestState 5 "CHARGE_REST" 4 "CHARGE" 3 "DISCHARGE_REST" 2 "DISCHARGE" 1 "HEAT_PACK" 0 "NOT_RUNNING" ;
VAL_ 1170 BMS_userFacingSohTestEndMode 5 "TEST_COMPLETE_WITH_SOC_IMBALANCE" 4 "TEST_COMPLETE" 3 "FAILED" 2 "REQUEST_DROPPED" 1 "RUNNING" 0 "NONE" ;
VAL_ 1170 BMS_timeSinceSohUpdate 4095 "SNA" ;
VAL_ 1170 BMS_requiredEvsePowerForSoh 255 "SNA" ;
VAL_ 1170 BMS_distanceSinceSohUpdate 65535 "SNA" ;
VAL_ 530 BMS_contactorState 6 "BMS_CTRSET_BLOCKED" 5 "BMS_CTRSET_WELDED" 4 "BMS_CTRSET_CLOSED" 3 "BMS_CTRSET_CLOSING" 2 "BMS_CTRSET_OPENING" 1 "BMS_CTRSET_OPEN" 0 "BMS_CTRSET_SNA" ;
VAL_ 530 BMS_userChargeStatus 6 "BMS_CALIBRATING" 5 "BMS_CHARGE_STOPPED" 4 "BMS_CHARGE_COMPLETE" 3 "BMS_CHARGING" 2 "BMS_ABOUT_TO_CHARGE" 1 "BMS_NO_POWER" 0 "BMS_DISCONNECTED" ;
VAL_ 530 BMS_state 10 "BMS_DIAG" 9 "BMS_SNA" 8 "BMS_TEST" 7 "BMS_WELD" 6 "BMS_FAULT" 5 "BMS_CLEAR_FAULT" 4 "BMS_FEIM" 3 "BMS_CHARGE" 2 "BMS_SUPPORT" 1 "BMS_DRIVE" 0 "BMS_STANDBY" ;
VAL_ 530 BMS_diLimpRequest 1 "LIMP_REQUEST_WELDED" 0 "LIMP_REQUEST_NONE" ;
VAL_ 530 BMS_chgPowerAvailable 4095 "SNA" ;
VAL_ 530 BMS_smStateRequest 10 "BMS_DIAG" 9 "BMS_SNA" 8 "BMS_TEST" 7 "BMS_WELD" 6 "BMS_FAULT" 5 "BMS_CLEAR_FAULT" 4 "BMS_FEIM" 3 "BMS_CHARGE" 2 "BMS_SUPPORT" 1 "BMS_DRIVE" 0 "BMS_STANDBY" ;
VAL_ 530 BMS_hvState 6 "HV_UP" 5 "HV_UP_FOR_DC_CHARGE" 4 "HV_UP_FOR_CHARGE" 3 "HV_UP_FOR_DRIVE" 2 "HV_GOING_DOWN" 1 "HV_COMING_UP" 0 "HV_DOWN" ;
VAL_ 754 BMS_nmKeepAwakeReason 7 "BMS_KEEPAWAKE_REASON_PRECONDITIONING" 6 "BMS_KEEPAWAKE_REASON_CP_ACTIVE" 5 "BMS_KEEPAWAKE_REASON_BMS_ACTIVE" 4 "BMS_KEEPAWAKE_REASON_HVP_ACTIVE" 3 "BMS_KEEPAWAKE_REASON_FC_CTR_CLEANING" 2 "BMS_KEEPAWAKE_REASON_CRITICAL_ALERT" 1 "BMS_KEEPAWAKE_REASON_CTRS_CLOSED" 0 "BMS_KEEPAWAKE_REASON_NONE_SNA" ;
VAL_ 754 BMS_nmWakeUpReason 4 "BMS_WAKEUP_REASON_CRITICALALERT" 3 "BMS_WAKEUP_REASON_WANTTOCHARGE" 2 "BMS_WAKEUP_REASON_CAN_HVS" 1 "BMS_WAKEUP_REASON_CAN_VEH" 0 "BMS_WAKEUP_REASON_NONE" ;
VAL_ 810 BMS_isolationResistance 1023 "SNA" ;
VAL_ 796 CC_currentLimit 255 "SNA" ;
VAL_ 796 CC_pilotState 3 "CC_PILOT_STATE_SNA" 2 "CC_PILOT_STATE_FAULTED" 1 "CC_PILOT_STATE_IDLE" 0 "CC_PILOT_STATE_READY" ;
VAL_ 796 CC_numPhases 0 "SNA" ;
VAL_ 796 CC_line1Voltage 511 "SNA" ;
VAL_ 796 CC_gridGrounding 2 "CC_GRID_GROUNDING_SNA" 1 "CC_GRID_GROUNDING_IT_SplitPhase" 0 "CC_GRID_GROUNDING_TN_TT" ;
VAL_ 796 CC_line2Voltage 511 "SNA" ;
VAL_ 796 CC_line3Voltage 511 "SNA" ;
VAL_ 796 CC_groundResistance 4095 "SNA" 4094 "NO_GROUND" ;
VAL_ 797 CC_chgStatus2Index 0 "Mux0" ;
VAL_ 797 CC_buttonState 1 "CC_BUTTON_PRESSED" 0 "CC_BUTTON_RELEASED" ;
VAL_ 812 CC_logIndex 13 "Mux13" 12 "Mux12" 11 "Mux11" 10 "Mux10" 4 "Mux4" 3 "Mux3" 2 "Mux2" 1 "Mux1" 0 "Mux0" ;
VAL_ 812 CC_activeConnectorID 255 "SNA" ;
VAL_ 812 CC_temperature1 127 "SNA" ;
VAL_ 812 CC_temperature2 127 "SNA" ;
VAL_ 812 CC_temperature3 127 "SNA" ;
VAL_ 812 CC_contactor1Closed 3 "CC_CONTACTOR_SNA" 1 "CC_CONTACTOR_CLOSED" 0 "CC_CONTACTOR_OPEN" ;
VAL_ 812 CC_contactor2Closed 3 "CC_CONTACTOR_SNA" 1 "CC_CONTACTOR_CLOSED" 0 "CC_CONTACTOR_OPEN" ;
VAL_ 812 CC_temperature4 127 "SNA" ;
VAL_ 812 CC_conn1Current 255 "SNA" ;
VAL_ 812 CC_conn2Current 255 "SNA" ;
VAL_ 812 CC_conn3Current 255 "SNA" ;
VAL_ 812 CC_conn4Current 255 "SNA" ;
VAL_ 870 CMPD_infoIndex 255 "END" 31 "SUBCOMPONENT_GITHASH" 30 "PACKAGE_SN_8_14" 29 "PACKAGE_SN_1_7" 27 "PACKAGE_PN_15_20" 26 "PACKAGE_PN_8_14" 25 "PACKAGE_PN_1_7" 23 "SUBCOMPONENT2" 22 "VARIANTCRC" 20 "UDS_PROTOCOL_BOOTCRC" 19 "VERSION_DEPRECATED" 18 "BOOTLOADER_GITHASH" 17 "APP_GITHASH" 16 "SUBCOMPONENT" 15 "BOOTLOADER_CRC" 14 "BOOTLOADER_SVN" 13 "APP_CRC" 11 "PCBAID_ASSYID_USAGEID" 10 "BUILD_HWID_COMPONENTID" 9 "DEPRECATED_9" 8 "DEPRECATED_8" 7 "DEPRECATED_7" 6 "DEPRECATED_6" 5 "DEPRECATED_5" 4 "DEPRECATED_4" 3 "DEPRECATED_3" 2 "DEPRECATED_2" 1 "DEPRECATED_1" 0 "DEPRECATED_0" ;
VAL_ 870 CMPD_infoBuildType 4 "INFO_MFG_BUILD" 3 "INFO_TRACEABLE_CI_BUILD" 2 "INFO_LOCAL_BUILD" 1 "INFO_PLATFORM_BUILD" 0 "INFO_UNKNOWN_BUILD" ;
VAL_ 870 CMPD_infoAssemblyId 255 "ASSEMBLY_SNA" 1 "ASSEMBLY1" ;
VAL_ 679 CMPD_state 15 "CMPD_STATE_SNA" 4 "CMPD_STATE_IDLE" 3 "CMPD_STATE_FAULT" 2 "CMPD_STATE_STANDBY" 1 "CMPD_STATE_RUNNING" 0 "CMPD_STATE_INIT" ;
VAL_ 679 CMPD_wasteHeatState 3 "CMPD_WASTE_HEAT_STATE_UNUSED" 2 "CMPD_WASTE_HEAT_STATE_NOT_AVAILABLE" 1 "CMPD_WASTE_HEAT_STATE_ACTIVE" 0 "CMPD_WASTE_HEAT_STATE_OFF" ;
VAL_ 867 CMP_infoIndex 255 "END" 31 "SUBCOMPONENT_GITHASH" 30 "PACKAGE_SN_8_14" 29 "PACKAGE_SN_1_7" 27 "PACKAGE_PN_15_20" 26 "PACKAGE_PN_8_14" 25 "PACKAGE_PN_1_7" 23 "SUBCOMPONENT2" 22 "VARIANTCRC" 20 "UDS_PROTOCOL_BOOTCRC" 19 "VERSION_DEPRECATED" 18 "BOOTLOADER_GITHASH" 17 "APP_GITHASH" 16 "SUBCOMPONENT" 15 "BOOTLOADER_CRC" 14 "BOOTLOADER_SVN" 13 "APP_CRC" 11 "PCBAID_ASSYID_USAGEID" 10 "BUILD_HWID_COMPONENTID" 9 "DEPRECATED_9" 8 "DEPRECATED_8" 7 "DEPRECATED_7" 6 "DEPRECATED_6" 5 "DEPRECATED_5" 4 "DEPRECATED_4" 3 "DEPRECATED_3" 2 "DEPRECATED_2" 1 "DEPRECATED_1" 0 "DEPRECATED_0" ;
VAL_ 867 CMP_infoBuildType 4 "INFO_MFG_BUILD" 3 "INFO_TRACEABLE_CI_BUILD" 2 "INFO_LOCAL_BUILD" 1 "INFO_PLATFORM_BUILD" 0 "INFO_UNKNOWN_BUILD" ;
VAL_ 867 CMP_infoAssemblyId 255 "ASSEMBLY_SNA" 1 "ASSEMBLY1" ;
VAL_ 541 CP_proximity 3 "CHG_PROXIMITY_LATCHED" 2 "CHG_PROXIMITY_UNLATCHED" 1 "CHG_PROXIMITY_DISCONNECTED" 0 "CHG_PROXIMITY_SNA" ;
VAL_ 541 CP_pilot 7 "CHG_PILOT_SNA" 6 "CHG_PILOT_UNUSED_6" 5 "CHG_PILOT_INVALID" 4 "CHG_PILOT_IDLE" 3 "CHG_PILOT_FAST_CHARGE" 2 "CHG_PILOT_LINE_CHARGE" 1 "CHG_PILOT_FAULTED" 0 "CHG_PILOT_NONE" ;
VAL_ 541 CP_cableType 5 "CHG_CABLE_TYPE_SNA" 4 "CHG_CABLE_TYPE_MCS" 3 "CHG_CABLE_TYPE_GB_DC" 2 "CHG_CABLE_TYPE_GB_AC" 1 "CHG_CABLE_TYPE_SAE" 0 "CHG_CABLE_TYPE_IEC" ;
VAL_ 541 CP_iecPilotState 9 "IEC_PILOT_SNA" 8 "IEC_PILOT_NUM" 7 "IEC_PILOT_F" 6 "IEC_PILOT_E" 5 "IEC_PILOT_C3" 4 "IEC_PILOT_C2" 3 "IEC_PILOT_C1" 2 "IEC_PILOT_B3" 1 "IEC_PILOT_B2" 0 "IEC_PILOT_B1" ;
VAL_ 541 CP_teslaSwcanState 8 "TESLA_SWCAN_V2L_ESTABLISHED" 7 "TESLA_SWCAN_V2L_RECEIVE" 6 "TESLA_SWCAN_OFFBOARD_UPDATE_IN_PROGRESS" 5 "TESLA_SWCAN_GO_TO_SLEEP" 4 "TESLA_SWCAN_FAULT" 3 "TESLA_SWCAN_ESTABLISHED" 2 "TESLA_SWCAN_RECEIVE" 1 "TESLA_SWCAN_ACCEPT" 0 "TESLA_SWCAN_INACTIVE" ;
VAL_ 541 CP_evseChargeType_UI 2 "AC_CHARGER_PRESENT" 1 "DC_CHARGER_PRESENT" 0 "NO_CHARGER_PRESENT" ;
VAL_ 541 CP_gbState 15 "GBDC_TESTER_PRESENT" 14 "GBDC_FAULTED" 13 "GBDC_RETRY_CHARGE" 12 "GBDC_ERROR_HANDLING" 11 "GBDC_END_OF_CHARGE" 10 "GBDC_CHARGE_DISABLING" 9 "GBDC_STOP_CHARGE_REQUESTED" 8 "GBDC_CHARGING" 7 "GBDC_READY_TO_CHARGE" 6 "GBDC_VEH_PACK_PRECHARGE" 5 "GBDC_CHARGE_PARAM_CONFIG" 4 "GBDC_RECOGNITION" 3 "GBDC_HANDSHAKING_EXT_ISO" 2 "GBDC_COMMS_RECEIVED" 1 "GBDC_WAIT_FOR_COMMS" 0 "GBDC_INACTIVE" ;
VAL_ 541 CP_gbdcStopChargeReason 8 "GBDC_PARAM_MISMATCH" 7 "GBDC_SUPERCHARGER_COMMS_TIMEOUT" 6 "GBDC_LIVE_DISCONNECT" 5 "GBDC_EVSE_CRITICAL_FAULT" 4 "GBDC_EVSE_FAULT" 3 "GBDC_COMMS_TIMEOUT" 2 "GBDC_EVSE_REQUESTED" 1 "GBDC_VEH_REQUESTED" 0 "GBDC_STOP_REASON_NONE" ;
VAL_ 541 CP_gbdcFailureReason 3 "GBDC_CRITICAL_FAILURE" 2 "GBDC_SHUTDOWN_FAILURE" 1 "GBDC_ATTEMPTS_EXPIRED" 0 "GBDC_FAILURE_NONE" ;
VAL_ 541 CP_acChargeState 6 "AC_CHARGE_FAULT" 5 "AC_CHARGE_VEH_SHUTDOWN" 4 "AC_CHARGE_ONBOARD_CHARGER_SHUTDOWN" 3 "AC_CHARGE_ENABLED" 2 "AC_CHARGE_STANDBY" 1 "AC_CHARGE_CONNECTED_CHARGE_BLOCKED" 0 "AC_CHARGE_INACTIVE" ;
VAL_ 541 CP_teslaDcState 10 "TESLA_DC_FAULT" 9 "TESLA_DC_EMERGENCY_SHUTDOWN" 8 "TESLA_DC_VEH_SHUTDOWN" 7 "TESLA_DC_EVSE_SHUTDOWN" 6 "TESLA_DC_ENABLED" 5 "TESLA_DC_EXT_PRECHARGE_ACTIVE" 4 "TESLA_DC_EXT_TEST_ACTIVE" 3 "TESLA_DC_EXT_TESTS_ENABLED" 2 "TESLA_DC_STANDBY" 1 "TESLA_DC_CONNECTED_CHARGE_BLOCKED" 0 "TESLA_DC_INACTIVE" ;
VAL_ 1342 CP_infoIndex 255 "END" 31 "SUBCOMPONENT_GITHASH" 30 "PACKAGE_SN_8_14" 29 "PACKAGE_SN_1_7" 27 "PACKAGE_PN_15_20" 26 "PACKAGE_PN_8_14" 25 "PACKAGE_PN_1_7" 23 "SUBCOMPONENT2" 22 "VARIANTCRC" 20 "UDS_PROTOCOL_BOOTCRC" 19 "VERSION_DEPRECATED" 18 "BOOTLOADER_GITHASH" 17 "APP_GITHASH" 16 "SUBCOMPONENT" 15 "BOOTLOADER_CRC" 14 "BOOTLOADER_SVN" 13 "APP_CRC" 11 "PCBAID_ASSYID_USAGEID" 10 "BUILD_HWID_COMPONENTID" 9 "DEPRECATED_9" 8 "DEPRECATED_8" 7 "DEPRECATED_7" 6 "DEPRECATED_6" 5 "DEPRECATED_5" 4 "DEPRECATED_4" 3 "DEPRECATED_3" 2 "DEPRECATED_2" 1 "DEPRECATED_1" 0 "DEPRECATED_0" ;
VAL_ 1342 CP_buildType 4 "INFO_MFG_BUILD" 3 "INFO_TRACEABLE_CI_BUILD" 2 "INFO_LOCAL_BUILD" 1 "INFO_PLATFORM_BUILD" 0 "INFO_UNKNOWN_BUILD" ;
VAL_ 1885 CP_loggingFastSelect 5 "5" 4 "4" 3 "3" 2 "2" 1 "1" 0 "0" ;
VAL_ 1885 CP_chargeCablePresent 1 "CABLE_PRESENT" 0 "CABLE_NOT_PRESENT" ;
VAL_ 1885 CP_UHF_controlState 10 "CP_UHF_FAULT" 9 "CP_UHF_SLEEP" 8 "CP_UHF_HANDLE_FOUND" 7 "CP_UHF_READ_RXFIFO" 6 "CP_UHF_CHECK_RX" 5 "CP_UHF_RX" 4 "CP_UHF_PREPARE_RX" 3 "CP_UHF_CALIBRATE" 2 "CP_UHF_IDLE" 1 "CP_UHF_CONFIG" 0 "CP_UHF_INIT" ;
VAL_ 1885 CP_doorOpenRequest 8 "CPD_OPEN_REQ_NUM" 7 "CPD_OPEN_REQ_CABLE_RECONNECTED" 6 "CPD_OPEN_REQ_VCFRONT" 5 "CPD_OPEN_REQ_CLOSING_FAILED" 4 "CPD_OPEN_REQ_PUSH_TO_OPEN" 3 "CPD_OPEN_REQ_UHF" 2 "CPD_OPEN_REQ_SEC" 1 "CPD_OPEN_REQ_UI" 0 "CPD_OPEN_REQ_NONE" ;
VAL_ 1885 CP_doorOpenEndOfDriveReason 7 "CP_STOP_DRIVE_REASON_OVERCURRENT" 6 "CP_STOP_DRIVE_REASON_REQ_OVERRIDE" 5 "CP_STOP_DRIVE_REASON_ABSOLUTE_TIMEOUT" 4 "CP_STOP_DRIVE_REASON_MAX_TARGET_V" 3 "CP_STOP_DRIVE_REASON_REACHED_STOP" 2 "CP_STOP_DRIVE_REASON_STOPPED_MOVING_TIMEOUT" 1 "CP_STOP_DRIVE_REASON_STALLED" 0 "CP_STOP_DRIVE_REASON_NONE" ;
VAL_ 1885 CP_doorCloseEndOfDriveReason 7 "CP_STOP_DRIVE_REASON_OVERCURRENT" 6 "CP_STOP_DRIVE_REASON_REQ_OVERRIDE" 5 "CP_STOP_DRIVE_REASON_ABSOLUTE_TIMEOUT" 4 "CP_STOP_DRIVE_REASON_MAX_TARGET_V" 3 "CP_STOP_DRIVE_REASON_REACHED_STOP" 2 "CP_STOP_DRIVE_REASON_STOPPED_MOVING_TIMEOUT" 1 "CP_STOP_DRIVE_REASON_STALLED" 0 "CP_STOP_DRIVE_REASON_NONE" ;
VAL_ 1885 CP_doorCloseRequest 16 "CPD_CLOSE_REQ_NUM" 15 "CPD_CLOSE_REQ_COVER_OPEN" 14 "CPD_CLOSE_REQ_VCFRONT" 13 "CPD_CLOSE_REQ_OPEN_ON_WAKE" 12 "CPD_CLOSE_REQ_SENSOR_COMMS_RECOVERED" 11 "CPD_CLOSE_REQ_SENSOR_MISMATCH" 10 "CPD_CLOSE_REQ_INITIAL_CINCH" 9 "CPD_CLOSE_REQ_OPENED_IN_DRIVE_STATE" 8 "CPD_CLOSE_REQ_ENTER_DRIVE" 7 "CPD_CLOSE_REQ_FAULT_LINE" 6 "CPD_CLOSE_REQ_CAR_WASH" 5 "CPD_CLOSE_REQ_PUSH_TO_CLOSE" 4 "CPD_CLOSE_REQ_SEC" 3 "CPD_CLOSE_REQ_UI" 2 "CPD_CLOSE_REQ_DOOR_OPEN_TIMEOUT" 1 "CPD_CLOSE_REQ_CABLE_UNPLUGGED" 0 "CPD_CLOSE_REQ_NONE" ;
VAL_ 1885 CP_latchDisengagingStopReason 7 "CP_STOP_DRIVE_REASON_OVERCURRENT" 6 "CP_STOP_DRIVE_REASON_REQ_OVERRIDE" 5 "CP_STOP_DRIVE_REASON_ABSOLUTE_TIMEOUT" 4 "CP_STOP_DRIVE_REASON_MAX_TARGET_V" 3 "CP_STOP_DRIVE_REASON_REACHED_STOP" 2 "CP_STOP_DRIVE_REASON_STOPPED_MOVING_TIMEOUT" 1 "CP_STOP_DRIVE_REASON_STALLED" 0 "CP_STOP_DRIVE_REASON_NONE" ;
VAL_ 1885 CP_latchEngagingStopReason 7 "CP_STOP_DRIVE_REASON_OVERCURRENT" 6 "CP_STOP_DRIVE_REASON_REQ_OVERRIDE" 5 "CP_STOP_DRIVE_REASON_ABSOLUTE_TIMEOUT" 4 "CP_STOP_DRIVE_REASON_MAX_TARGET_V" 3 "CP_STOP_DRIVE_REASON_REACHED_STOP" 2 "CP_STOP_DRIVE_REASON_STOPPED_MOVING_TIMEOUT" 1 "CP_STOP_DRIVE_REASON_STALLED" 0 "CP_STOP_DRIVE_REASON_NONE" ;
VAL_ 1885 CP_doorIdDetectionState 2 "DOOR_ID_VALID" 1 "DOOR_ID_INVALID" 0 "DOOR_ID_UNKNOWN_SNA" ;
VAL_ 1885 CP_doorIdDetectedBin 3 "DOOR_ID_BIN_OPAL" 2 "DOOR_ID_BIN_HMC" 1 "DOOR_ID_BIN_NMB" 0 "DOOR_ID_BIN_UNKNOWN" ;
VAL_ 989 CP_loggingSlowSelect 7 "7" 6 "6" 5 "5" 4 "4" 3 "3" 2 "2" 1 "1" 0 "0" ;
VAL_ 989 CP_inlet1HarnessIdState 2 "HARNESS_PEDIGREE_VALID" 1 "HARNESS_PEDIGREE_INVALID" 0 "HARNESS_PEDIGREE_UNKNOWN_SNA" ;
VAL_ 989 CP_inlet2HarnessIdState 2 "HARNESS_PEDIGREE_VALID" 1 "HARNESS_PEDIGREE_INVALID" 0 "HARNESS_PEDIGREE_UNKNOWN_SNA" ;
VAL_ 989 CP_inletHeaterState 3 "INLET_HEATER_FAULTED" 2 "INLET_HEATER_ENABLED_LOWTEMP" 1 "INLET_HEATER_ENABLED_HIGHTEMP" 0 "INLET_HEATER_DISABLED" ;
VAL_ 989 CP_doorOpenLimiterMaxRequestType 8 "CPD_OPEN_REQ_NUM" 7 "CPD_OPEN_REQ_CABLE_RECONNECTED" 6 "CPD_OPEN_REQ_VCFRONT" 5 "CPD_OPEN_REQ_CLOSING_FAILED" 4 "CPD_OPEN_REQ_PUSH_TO_OPEN" 3 "CPD_OPEN_REQ_UHF" 2 "CPD_OPEN_REQ_SEC" 1 "CPD_OPEN_REQ_UI" 0 "CPD_OPEN_REQ_NONE" ;
VAL_ 989 CP_doorCloseLimiterMaxRequestTyp 16 "CPD_CLOSE_REQ_NUM" 15 "CPD_CLOSE_REQ_COVER_OPEN" 14 "CPD_CLOSE_REQ_VCFRONT" 13 "CPD_CLOSE_REQ_OPEN_ON_WAKE" 12 "CPD_CLOSE_REQ_SENSOR_COMMS_RECOVERED" 11 "CPD_CLOSE_REQ_SENSOR_MISMATCH" 10 "CPD_CLOSE_REQ_INITIAL_CINCH" 9 "CPD_CLOSE_REQ_OPENED_IN_DRIVE_STATE" 8 "CPD_CLOSE_REQ_ENTER_DRIVE" 7 "CPD_CLOSE_REQ_FAULT_LINE" 6 "CPD_CLOSE_REQ_CAR_WASH" 5 "CPD_CLOSE_REQ_PUSH_TO_CLOSE" 4 "CPD_CLOSE_REQ_SEC" 3 "CPD_CLOSE_REQ_UI" 2 "CPD_CLOSE_REQ_DOOR_OPEN_TIMEOUT" 1 "CPD_CLOSE_REQ_CABLE_UNPLUGGED" 0 "CPD_CLOSE_REQ_NONE" ;
VAL_ 605 CP_type 3 "CP_TYPE_IEC_CCS" 2 "CP_TYPE_GB" 1 "CP_TYPE_EURO_IEC" 0 "CP_TYPE_US_TESLA" ;
VAL_ 605 CP_latchState 3 "CP_LATCH_BLOCKING" 2 "CP_LATCH_ENGAGED" 1 "CP_LATCH_DISENGAGED" 0 "CP_LATCH_SNA" ;
VAL_ 605 CP_doorControlState 6 "CP_doorSenseClosed" 5 "CP_doorClosing" 4 "CP_doorSenseOpen" 3 "CP_doorOpening" 2 "CP_doorOpenRequested" 1 "CP_doorIdle" 0 "CP_doorInit" ;
VAL_ 605 CP_chargeCableState 2 "CHARGE_CABLE_CONNECTED" 1 "CHARGE_CABLE_NOT_CONNECTED" 0 "CHARGE_CABLE_UNKNOWN_SNA" ;
VAL_ 605 CP_latchControlState 5 "CP_latchEngaging" 4 "CP_latchDisengaged" 3 "CP_latchDisengaging" 2 "CP_latchDisengageRequested" 1 "CP_latchIdle" 0 "CP_latchInit" ;
VAL_ 605 CP_ledColor 13 "CP_LEDS_FLASHING_WHITE" 12 "CP_LEDS_FADING_OUT" 11 "CP_LEDS_FLASHING_PURPLE" 10 "CP_LEDS_FLASHING_BLUE" 9 "CP_LEDS_DEBUG" 8 "CP_LEDS_RAVE" 7 "CP_LEDS_AMBER" 6 "CP_LEDS_FLASHING_AMBER" 5 "CP_LEDS_FLASHING_GREEN" 4 "CP_LEDS_WHITE" 3 "CP_LEDS_BLUE" 2 "CP_LEDS_GREEN" 1 "CP_LEDS_RED" 0 "CP_LEDS_OFF" ;
VAL_ 605 CP_faultLineSensed 1 "FAULT_LINE_SET" 0 "FAULT_LINE_CLEARED" ;
VAL_ 605 CP_doorPresenceState 7 "CP_DOOR_PRESENCE_STATE_FAULT" 6 "CP_DOOR_PRESENCE_STATE_OFF_CHARGE" 5 "CP_DOOR_PRESENCE_STATE_OFF_DRIVE" 4 "CP_DOOR_PRESENCE_STATE_NOT_PRESENT" 3 "CP_DOOR_PRESENCE_STATE_PRESENT" 2 "CP_DOOR_PRESENCE_STATE_INIT_FROM_DRIVE" 1 "CP_DOOR_PRESENCE_STATE_INIT_FROM_CHARGE" 0 "CP_DOOR_PRESENCE_STATE_INIT" ;
VAL_ 605 CP_inductiveSensorState 7 "CP_INDUCTIVE_SENSOR_CONFIG" 6 "CP_INDUCTIVE_SENSOR_RESET" 5 "CP_INDUCTIVE_SENSOR_FAULT" 4 "CP_INDUCTIVE_SENSOR_WAIT_FOR_INIT" 3 "CP_INDUCTIVE_SENSOR_PAUSE" 2 "CP_INDUCTIVE_SENSOR_SHUTDOWN" 1 "CP_INDUCTIVE_SENSOR_POLL" 0 "CP_INDUCTIVE_SENSOR_INIT" ;
VAL_ 605 CP_coldWeatherMode 1 "CP_COLD_WEATHER_LATCH_MITIGATION" 0 "CP_COLD_WEATHER_NONE" ;
VAL_ 605 CP_inletHeaterUiState 4 "CP_HEATER_FAULTED" 3 "CP_HEATER_ENABLED" 2 "CP_HEATER_AVAILABLE" 1 "CP_HEATER_NOT_AVAILABLE" 0 "CP_HEATER_NOT_SUPPORTED" ;
VAL_ 893 CP_thermalStatusSelect 1 "1" 0 "0" ;
VAL_ 1001 DAS_headlightRequest 3 "DAS_HEADLIGHT_REQUEST_INVALID" 2 "DAS_HEADLIGHT_REQUEST_TAIL_LIGHTS_ONLY" 1 "DAS_HEADLIGHT_REQUEST_ON" 0 "DAS_HEADLIGHT_REQUEST_OFF" ;
VAL_ 1001 DAS_hazardLightRequest 3 "DAS_REQUEST_HAZARDS_SNA" 2 "DAS_REQUEST_HAZARDS_ON_FAST" 1 "DAS_REQUEST_HAZARDS_ON" 0 "DAS_REQUEST_HAZARDS_OFF" ;
VAL_ 1001 DAS_wiperSpeed 15 "DAS_WIPER_SPEED_INVALID" 14 "DAS_WIPER_SPEED_14" 13 "DAS_WIPER_SPEED_13" 12 "DAS_WIPER_SPEED_12" 11 "DAS_WIPER_SPEED_11" 10 "DAS_WIPER_SPEED_10" 9 "DAS_WIPER_SPEED_9" 8 "DAS_WIPER_SPEED_8" 7 "DAS_WIPER_SPEED_7" 6 "DAS_WIPER_SPEED_6" 5 "DAS_WIPER_SPEED_5" 4 "DAS_WIPER_SPEED_4" 3 "DAS_WIPER_SPEED_3" 2 "DAS_WIPER_SPEED_2" 1 "DAS_WIPER_SPEED_1" 0 "DAS_WIPER_SPEED_OFF" ;
VAL_ 1001 DAS_turnIndicatorRequest 4 "DAS_TURN_INDICATOR_DEFER" 3 "DAS_TURN_INDICATOR_CANCEL" 2 "DAS_TURN_INDICATOR_RIGHT" 1 "DAS_TURN_INDICATOR_LEFT" 0 "DAS_TURN_INDICATOR_NONE" ;
VAL_ 1001 DAS_highLowBeamDecision 3 "DAS_HIGH_BEAM_SNA" 2 "DAS_HIGH_BEAM_ON" 1 "DAS_HIGH_BEAM_OFF" 0 "DAS_HIGH_BEAM_UNDECIDED" ;
VAL_ 1001 DAS_heaterRequest 2 "DAS_HEATER_ON" 1 "DAS_HEATER_OFF" 0 "DAS_HEATER_SNA" ;
VAL_ 1001 DAS_highLowBeamOffReason 5 "HIGH_BEAM_OFF_REASON_SNA" 4 "HIGH_BEAM_OFF_REASON_HEAD_LIGHT" 3 "HIGH_BEAM_OFF_REASON_AMBIENT_LIGHT" 2 "HIGH_BEAM_OFF_REASON_MOVING_RADAR_TARGET" 1 "HIGH_BEAM_OFF_REASON_MOVING_VISION_TARGET" 0 "HIGH_BEAM_ON" ;
VAL_ 1001 DAS_mirrorFoldRequest 3 "DAS_MIRROR_REQUEST_SNA" 2 "DAS_MIRROR_REQUEST_UNFOLD" 1 "DAS_MIRROR_REQUEST_FOLD" 0 "DAS_MIRROR_REQUEST_NONE" ;
VAL_ 1001 DAS_autoWiperState 5 "DAS_AUTO_WIPER_STATE_SNA" 4 "DAS_AUTO_WIPER_STATE_FAST_CONTINUOUS" 3 "DAS_AUTO_WIPER_STATE_SLOW_CONTINUOUS" 2 "DAS_AUTO_WIPER_STATE_FAST_INTERMITTENT" 1 "DAS_AUTO_WIPER_STATE_SLOW_INTERMITTENT" 0 "DAS_AUTO_WIPER_STATE_OFF" ;
VAL_ 1001 DAS_turnIndicatorRequestReason 24 "DAS_ACTIVE_SIMULTANEOUS_LANE_CHANGE_AVOIDANCE" 23 "DAS_ACTIVE_INFEASIBLE_KINEMATICS_LANE_CHANGE" 22 "DAS_ACTIVE_STAY_OUT_OF_RIGHTMOST_LANE_LANE_CHANGE" 21 "DAS_ACTIVE_AWAY_FROM_MERGE_LANE_CHANGE" 20 "DAS_ACTIVE_EXIT_RIGHT_LANE_LANE_CHANGE" 19 "DAS_ACTIVE_EXIT_PASSING_LANE_LANE_CHANGE" 18 "DAS_ACTIVE_INCORRECT_ROAD_SIDE_LANE_CHANGE" 17 "DAS_ACTIVE_STATIC_OBJECT_LANE_CHANGE" 15 "DAS_CANCEL_MANUAL_BLINKER" 14 "DAS_CANCEL_AUTO_PARK" 13 "DAS_ACTIVE_AUTO_PARK" 12 "DAS_CANCEL_SUMMMON" 11 "DAS_ACTIVE_SUMMMON" 10 "DAS_CANCEL_INTERSECTION" 9 "DAS_ACTIVE_INTERSECTION" 8 "DAS_ACTIVE_COMMANDED_LANE_CHANGE" 7 "DAS_CANCEL_MERGE" 6 "DAS_ACTIVE_MERGE" 5 "DAS_CANCEL_FORK" 4 "DAS_CANCEL_LANE_CHANGE" 3 "DAS_ACTIVE_FORK" 2 "DAS_ACTIVE_SPEED_LANE_CHANGE" 1 "DAS_ACTIVE_NAV_LANE_CHANGE" 0 "DAS_NONE" ;
VAL_ 1001 DAS_restrictDoorReleaseLeft 1 "RESTRICT_DOOR_RELEASE_ACTIVE" 0 "RESTRICT_DOOR_RELEASE_INACTIVE" ;
VAL_ 1001 DAS_restrictDoorReleaseRight 1 "RESTRICT_DOOR_RELEASE_ACTIVE" 0 "RESTRICT_DOOR_RELEASE_INACTIVE" ;
VAL_ 634 DIF_hvilStatus 3 "SNA" 2 "CLOSED" 1 "OPEN" 0 "DISABLED" ;
VAL_ 634 DIF_hvilSupplyState 2 "ACTIVE" 1 "INACTIVE" 0 "NOT_AVAILABLE" ;
VAL_ 634 DIF_vBatQF 1 "QUALIFIED" 0 "NOT_QUALIFIED" ;
VAL_ 634 DIF_powerStageSafeState 3 "PSTG_SAFESTATE_3PS_LOW" 2 "PSTG_SAFESTATE_3PS_HIGH" 1 "PSTG_SAFESTATE_ALL_OFF" 0 "PSTG_SAFESTATE_NONE" ;
VAL_ 634 DIF_fluxState 12 "DI_FLUXSTATE_DISABLED" 11 "DI_FLUXSTATE_MAGNET_FLUX_DETECT" 10 "DI_FLUXSTATE_STATIONARY_WASTE" 9 "DI_FLUXSTATE_FAULT" 7 "DI_FLUXSTATE_VCONTROL" 6 "DI_FLUXSTATE_ICONTROL" 5 "DI_FLUXSTATE_ENABLED" 4 "DI_FLUXSTATE_FLUX_DOWN" 3 "DI_FLUXSTATE_FLUX_UP" 2 "DI_FLUXSTATE_STANDBY" 1 "DI_FLUXSTATE_TEST" 0 "DI_FLUXSTATE_START" ;
VAL_ 634 DIF_gateDriveState 4 "PSTG_GD_STATE_NOT_CONFIGURED" 3 "PSTG_GD_STATE_CONFIGURED" 2 "PSTG_GD_STATE_CONFIGURING" 1 "PSTG_GD_STATE_SELFTEST" 0 "PSTG_GD_STATE_INIT" ;
VAL_ 741 DIF_elecPower -1024 "SNA" ;
VAL_ 741 DIF_drivePowerMax 511 "SNA" ;
VAL_ 886 DIF_tempIndex 4 "Mux4" 3 "Mux3" 2 "Mux2" 1 "Mux1" 0 "Mux0" ;
VAL_ 886 DIF_inverterTQF 3 "INVERTERT_UNKNOWN" 2 "INVERTERT_RATIONAL" 1 "INVERTERT_IRRATIONAL" 0 "INVERTERT_INIT" ;
VAL_ 886 DIF_pcbT 0 "SNA" ;
VAL_ 886 DIF_statorT 0 "SNA" ;
VAL_ 886 DIF_dcCapT 0 "SNA" ;
VAL_ 886 DIF_heatsinkT 0 "SNA" ;
VAL_ 886 DIF_fluidInTemp 0 "SNA" ;
VAL_ 886 DIF_normalFetBurnIn 65535 "SNA" ;
VAL_ 886 DIF_additionalFetBurnIn 65535 "SNA" ;
VAL_ 886 DIF_currentWeibullMiles 32767 "SNA" ;
VAL_ 886 DIF_endOfServiceWeibullMiles 32767 "SNA" ;
VAL_ 886 DIF_burnInDamageRatio 511 "SNA" 510 "DEFAULT_1" ;
VAL_ 886 DIF_initialBurnInVehicleOdometer 4294967295 "SNA" ;
VAL_ 1367 DIF_oilFlowReq 255 "SNA" ;
VAL_ 1367 DIF_criticalFlowReq 1 "ACTIVE" 0 "NOT_ACTIVE" ;
VAL_ 1367 DIF_burnInStatus 5 "COMPLETE" 4 "ACTIVE" 3 "INCOMPLETE" 2 "UNAVAILABLE" 1 "NOT_REQUIRED" 0 "INIT" ;
VAL_ 2005 DIR_debugSelector 132 "Mux132" 131 "Mux131" 128 "Mux128" 72 "Mux72" 70 "Mux70" 69 "Mux69" 68 "Mux68" 67 "Mux67" 66 "Mux66" 64 "Mux64" 63 "Mux63" 52 "Mux52" 50 "Mux50" 49 "Mux49" 48 "Mux48" 47 "Mux47" 46 "Mux46" 44 "Mux44" 43 "Mux43" 42 "Mux42" 41 "Mux41" 40 "Mux40" 39 "Mux39" 38 "Mux38" 37 "Mux37" 36 "Mux36" 35 "Mux35" 34 "Mux34" 33 "Mux33" 32 "Mux32" ;
VAL_ 2005 DIR_phaseOutBusbarTemp 0 "SNA" ;
VAL_ 2005 DIR_phaseOutBusbarWeldTemp 0 "SNA" ;
VAL_ 2005 DIR_phaseOutLugTemp 0 "SNA" ;
VAL_ 2005 DIR_dcLinkCapTemp 0 "SNA" ;
VAL_ 2005 DIR_hvDcCableTemp 0 "SNA" ;
VAL_ 2005 DIR_negDcBusbarTemp 0 "SNA" ;
VAL_ 2005 DIR_posDcBusbarTemp 0 "SNA" ;
VAL_ 2005 DIR_statorEndWindingTemp 0 "SNA" ;
VAL_ 2005 DIR_rotorMaxMagnetTemp 0 "SNA" ;
VAL_ 2005 DIR_statorSlotWindingTemp 0 "SNA" ;
VAL_ 633 DIR_hvilStatus 3 "SNA" 2 "CLOSED" 1 "OPEN" 0 "DISABLED" ;
VAL_ 633 DIR_hvilSupplyState 2 "ACTIVE" 1 "INACTIVE" 0 "NOT_AVAILABLE" ;
VAL_ 633 DIR_vBatQF 1 "QUALIFIED" 0 "NOT_QUALIFIED" ;
VAL_ 633 DIR_powerStageSafeState 3 "PSTG_SAFESTATE_3PS_LOW" 2 "PSTG_SAFESTATE_3PS_HIGH" 1 "PSTG_SAFESTATE_ALL_OFF" 0 "PSTG_SAFESTATE_NONE" ;
VAL_ 633 DIR_fluxState 12 "DI_FLUXSTATE_DISABLED" 11 "DI_FLUXSTATE_MAGNET_FLUX_DETECT" 10 "DI_FLUXSTATE_STATIONARY_WASTE" 9 "DI_FLUXSTATE_FAULT" 7 "DI_FLUXSTATE_VCONTROL" 6 "DI_FLUXSTATE_ICONTROL" 5 "DI_FLUXSTATE_ENABLED" 4 "DI_FLUXSTATE_FLUX_DOWN" 3 "DI_FLUXSTATE_FLUX_UP" 2 "DI_FLUXSTATE_STANDBY" 1 "DI_FLUXSTATE_TEST" 0 "DI_FLUXSTATE_START" ;
VAL_ 633 DIR_gateDriveState 4 "PSTG_GD_STATE_NOT_CONFIGURED" 3 "PSTG_GD_STATE_CONFIGURED" 2 "PSTG_GD_STATE_CONFIGURING" 1 "PSTG_GD_STATE_SELFTEST" 0 "PSTG_GD_STATE_INIT" ;
VAL_ 821 DIR_infoIndex 255 "INFO_END" 44 "TRACKING_DATA_5" 43 "TRACKING_DATA_4" 42 "TRACKING_DATA_3" 41 "TRACKING_DATA_2" 40 "TRACKING_DATA_1" 34 "INFO_SUBCOMPONENT2_HWID" 33 "INFO_SUBCOMPONENT_HWID" 32 "INFO_SUBCOMPONENT2_GITHASH" 31 "INFO_SUBCOMPONENT_GITHASH" 23 "INFO_SUBCOMPONENT2" 20 "INFO_UDS_PROTOCOL_BOOTCRC" 19 "INFO_VERSION_DEPRECATED" 18 "INFO_BOOTLOADER_GITHASH" 17 "INFO_APP_GITHASH" 16 "INFO_SUBCOMPONENT" 15 "INFO_BOOTLOADER_CRC" 14 "INFO_BOOTLOADER_SVN" 13 "INFO_APP_CRC" 11 "INFO_PCBAID_ASSYID_USAGEID" 10 "INFO_BUILD_HWID_COMPONENTID" 9 "INFO_DEPRECATED_9" 8 "INFO_DEPRECATED_8" 7 "INFO_DEPRECATED_7" 6 "INFO_DEPRECATED_6" 5 "INFO_DEPRECATED_5" 4 "INFO_DEPRECATED_4" 3 "INFO_DEPRECATED_3" 2 "INFO_DEPRECATED_2" 1 "INFO_DEPRECATED_1" 0 "INFO_DEPRECATED_0" ;
VAL_ 821 DIR_buildType 4 "INFO_MFG_BUILD" 3 "INFO_TRACEABLE_CI_BUILD" 2 "INFO_LOCAL_BUILD" 1 "INFO_PLATFORM_BUILD" 0 "INFO_UNKNOWN_BUILD" ;
VAL_ 821 DIR_hardwareId 252 "CONFIGURABLE_HWID_PLACEHOLDER" ;
VAL_ 821 DIR_motorType 31 "DI_MOTOR_PM216E" 20 "DI_MOTOR_PM215D_1KV" 18 "DI_MOTOR_IM260E_1KV" 17 "DI_MOTOR_IM260D_1KV" 16 "DI_MOTOR_PM261C" 15 "DI_MOTOR_PM215C_1KV" 14 "DI_MOTOR_IM260C_1KV" 13 "DI_MOTOR_PM215A_1KV" 12 "DI_MOTOR_IM260A_1KV" 11 "DI_MOTOR_IM228HEA" 10 "DI_MOTOR_PM228HEA" 9 "DI_MOTOR_PM275C" 8 "DI_MOTOR_PM291D" 7 "DI_MOTOR_PM291C" 6 "DI_MOTOR_PM228C" 5 "DI_MOTOR_PM350B" 4 "DI_MOTOR_PM275B" 3 "DI_MOTOR_IM130D_AL" 2 "DI_MOTOR_IM130D" 1 "DI_MOTOR_PM216D" 0 "DI_MOTOR_SNA" ;
VAL_ 821 DIR_siliconType 1 "IGBT" 0 "MOSFET" ;
VAL_ 821 DIR_mechSafeStateType 2 "DI_MECH_SAFE_STATE_TYPE_PRESENT" 1 "DI_MECH_SAFE_STATE_TYPE_NONE" 0 "DI_MECH_SAFE_STATE_TYPE_SNA" ;
VAL_ 821 DIR_oilPumpBuildType 4 "INFO_MFG_BUILD" 3 "INFO_TRACEABLE_CI_BUILD" 2 "INFO_LOCAL_BUILD" 1 "INFO_PLATFORM_BUILD" 0 "INFO_UNKNOWN_BUILD" ;
VAL_ 821 DIR_FPGA_version 255 "SNA" 254 "LOCAL_BUILD" ;
VAL_ 821 DIR_refRotorOffset -2048 "SNA" ;
VAL_ 821 DIR_speedWearTotal 255 "SNA" ;
VAL_ 821 DIR_torqueWearTotal 255 "SNA" ;
VAL_ 917 DIR_oilPumpState 7 "OIL_PUMP_SNA" 6 "OIL_PUMP_FAULTED" 2 "OIL_PUMP_COLD_STARTUP" 1 "OIL_PUMP_ENABLE" 0 "OIL_PUMP_STANDBY" ;
VAL_ 917 DIR_oilPumpFluidTQF 1 "OIL_PUMP_FLUIDT_HIGH_CONFIDENCE" 0 "OIL_PUMP_FLUIDT_LOW_CONFIDENCE" ;
VAL_ 917 DIR_oilPumpFlowTarget 255 "SNA" ;
VAL_ 917 DIR_oilPumpFlowActual 255 "SNA" ;
VAL_ 917 DIR_oilPumpFluidT 255 "SNA" ;
VAL_ 917 DIR_oilPumpPhaseCurrent 255 "SNA" ;
VAL_ 917 DIR_oilPumpPressureEstimate 255 "SNA" ;
VAL_ 917 DIR_oilPumpPressureExpected 255 "SNA" ;
VAL_ 917 DIR_oilPumpPressureResidual 255 "SNA" ;
VAL_ 614 DIR_elecPower -1024 "SNA" ;
VAL_ 614 DIR_drivePowerMax 511 "SNA" ;
VAL_ 789 DIR_tempIndex 4 "Mux4" 3 "Mux3" 2 "Mux2" 1 "Mux1" 0 "Mux0" ;
VAL_ 789 DIR_inverterTQF 3 "INVERTERT_UNKNOWN" 2 "INVERTERT_RATIONAL" 1 "INVERTERT_IRRATIONAL" 0 "INVERTERT_INIT" ;
VAL_ 789 DIR_pcbT 0 "SNA" ;
VAL_ 789 DIR_statorT 0 "SNA" ;
VAL_ 789 DIR_dcCapT 0 "SNA" ;
VAL_ 789 DIR_heatsinkT 0 "SNA" ;
VAL_ 789 DIR_fluidInTemp 0 "SNA" ;
VAL_ 789 DIR_normalFetBurnIn 65535 "SNA" ;
VAL_ 789 DIR_additionalFetBurnIn 65535 "SNA" ;
VAL_ 789 DIR_currentWeibullMiles 32767 "SNA" ;
VAL_ 789 DIR_endOfServiceWeibullMiles 32767 "SNA" ;
VAL_ 789 DIR_burnInDamageRatio 511 "SNA" 510 "DEFAULT_1" ;
VAL_ 789 DIR_initialBurnInVehicleOdometer 4294967295 "SNA" ;
VAL_ 1495 DIR_oilFlowReq 255 "SNA" ;
VAL_ 1495 DIR_criticalFlowReq 1 "ACTIVE" 0 "NOT_ACTIVE" ;
VAL_ 1495 DIR_burnInStatus 5 "COMPLETE" 4 "ACTIVE" 3 "INCOMPLETE" 2 "UNAVAILABLE" 1 "NOT_REQUIRED" 0 "INIT" ;
